VERSION ""

NS_ :

BS_:

BU_: HVESP01 HVESS
VAL_TABLE_ HVESP_HVPackBalance 3 "SNA" 2 "BalancingComplete" 1 "Balancing" 0 "NotBalancing" ;
VAL_TABLE_ HVESP_PackState 7 "Disengage" 6 "Connected" 5 "ExternalIsolationCheck" 4 "PrepareBusJoin" 3 "PrepareBusPrecharge" 2 "StandbyReady" 1 "StandbyNotReady" 0 "StandbyInit" ;
VAL_TABLE_ HVESP_OperationalStatus 15 "NA" 14 "Error" 13 "Reserved" 12 "Reserved" 11 "Reserved" 10 "Reserved" 9 "Reserved" 8 "Reserved" 7 "Reserved" 6 "DisabledInt" 5 "DisabledExtCmd" 4 "EmergencyPowerDown" 3 "NormalPowerDown" 2 "Operational" 1 "InitComplete" 0 "InitInProcess" ;
VAL_TABLE_ HVESP_HvBusConnectionStatus 15 "NA" 14 "Error" 13 "Reserved" 12 "Reserved" 11 "Reserved" 10 "Reserved" 9 "Reserved" 8 "Reserved" 7 "Reserved" 6 "Reserved" 5 "Reserved" 4 "DisconnectedPreChgFail" 3 "DisconnectionInProcess" 2 "ConnectionInProcess" 1 "Connected" 0 "Disconnected" ;
VAL_TABLE_ HVESP_CellBalancingActive 3 "NA" 2 "Error" 1 "CellBalancingActive" 0 "CellBalancingNotActive" ;
VAL_TABLE_ HVESP_InternalChargeStatus 3 "NA" 2 "Error" 1 "ChargingOn" 0 "ChargingOff" ;
VAL_TABLE_ HVESP_CellBalanceStatus 3 "NA" 2 "Error" 1 "CellsUnbalanced" 0 "CellsBalanced" ;
VAL_TABLE_ HVESP_SocStatus 15 "NA" 14 "Error" 13 "Reserved" 12 "Reserved" 11 "Reserved" 10 "Reserved" 9 "Reserved" 8 "Reserved" 7 "Reserved" 6 "SocAboveUpperLimit" 5 "SocRecommendedUpperLimit" 4 "SocApproachingUpperLimit" 3 "SocBelowLowerLimit" 2 "SocRecommendedLowerLimit" 1 "SocApproachingLowerLimit" 0 "SocLevelAcceptableLimit" ;
VAL_TABLE_ HVESP_InertiaSwitchStatus 3 "NA" 2 "Error" 1 "ImpactSensed" 0 "NoImpactSensed" ;
VAL_TABLE_ HVESP_HvilStatus 3 "NA" 2 "Error" 1 "HvilOpen" 0 "HvilClosed" ;
VAL_TABLE_ HVESP_HvBusPassiveIsoTestStatus 15 "NA" 14 "Error" 13 "Reserved" 12 "Reserved" 11 "Reserved" 10 "Reserved" 9 "Reserved" 8 "Reserved" 7 "Reserved" 6 "Reserved" 5 "TestCompleteFault" 4 "TestCompleteMarginal" 3 "TestCompleteAcceptable" 2 "TestInProcess" 1 "TestRequestedNotInProgress" 0 "NoTestRequested" ;
VAL_TABLE_ HVESP_HvBusActiveIsoTestStatus 15 "NA" 14 "Error" 13 "Reserved" 12 "Reserved" 11 "Reserved" 10 "Reserved" 9 "Reserved" 8 "Reserved" 7 "Reserved" 6 "Reserved" 5 "TestCompleteFault" 4 "TestCompleteMarginal" 3 "TestCompleteAcceptable" 2 "TestInProcess" 1 "TestRequestedNotInProgress" 0 "NoTestRequested" ;
VAL_TABLE_ HVESP_CenterOfPackContState 3 "NA" 2 "Error" 1 "ContactorClosed" 0 "ContactorOpen" ;
VAL_TABLE_ HVESP_HvBusPrechgRelayState 3 "NA" 2 "Error" 1 "RelayOpen" 0 "RelayClosed" ;
VAL_TABLE_ HVESP_HvBusDisconnect 15 "NA" 14 "Error" 13 "DisconnectImminent" 12 "Reserved" 11 "Reserved" 10 "Reserved" 9 "Reserved" 8 "Reserved" 7 "DisconnectImminentPckCurrMax" 6 "DisconnectImminentCellVoltMax" 5 "DisconnectImminentCellVoltMin" 4 "DisconnectImminentModVoltMax" 3 "DisconnectImminentModVoltMin" 2 "DisconnectImminentBattPckVoltMax" 1 "DisconnectImminentBattPackVoltMin" 0 "DisconnectNotPending" ;
VAL_TABLE_ HVESP_HvBusNegContState 3 "NA" 2 "Error" 1 "ContactorClosed" 0 "ContactorOpen" ;
VAL_TABLE_ HVESP_HvBusPosContState 3 "NA" 2 "Error" 1 "ContactorClosed" 0 "ContactorOpen" ;
VAL_TABLE_ HVESP_ThermMngmntMaintReq 3 "DontCare" 2 "Reserved" 1 "ThermMngmntMaintModeNotReq" 0 "ThermMngmntMaintReq" ;
VAL_TABLE_ HVESP_HvBusLsResistor 3 "DontCare" 2 "Reserved" 1 "ConnectionRequested" 0 "ConnectionNotRequested" ;
VAL_TABLE_ HVESP_HvBusHsResistor 3 "DontCare" 2 "Reserved" 1 "ConnectionRequested" 0 "ConnectionNotRequested" ;
VAL_TABLE_ HVESP_OperationConsent 3 "DontCare" 2 "Reserved" 1 "ConsentGiven" 0 "ConsentRevoked" ;
VAL_TABLE_ HVESP_EnableIntChargerCmd 3 "DontCare" 2 "Error" 1 "EnableCharging" 0 "DisableCharging" ;
VAL_TABLE_ HVESP_CellBalancingCmd 3 "DontCare" 2 "Reserved" 1 "CellBalancingRequested" 0 "CellBalancingNotRequested" ;
VAL_TABLE_ HVESP_HvBusPassiveIsolationTest 3 "DontCare" 2 "Reserved" 1 "PassiveIsolationTestRequested" 0 "PassiveIsolationTestNotRequested" ;
VAL_TABLE_ HVESP_HvBusActiveIsoTestCmd 3 "DontCare" 2 "Reserved" 1 "ActiveIsoTestRequested" 0 "ActiveIsoTestNotRequested" ;
VAL_TABLE_ HVESP_PowerDownCmd 3 "DontCare" 2 "EmergencyPowerDown" 1 "NormalPowerDown" 0 "PowerDownNotRequested" ;
VAL_TABLE_ HVESP_HvBusConnectCmd 3 "DontCare" 2 "EmergencyContactorClose" 1 "CloseContactor" 0 "OpenContactor" ;

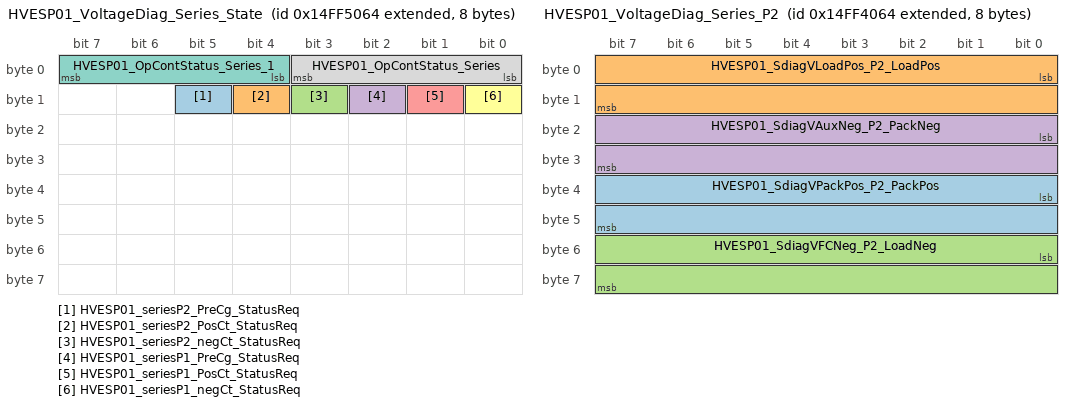
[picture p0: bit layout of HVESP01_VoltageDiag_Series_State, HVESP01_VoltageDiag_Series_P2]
BO_ 2499760228 HVESP01_VoltageDiag_Series_State: 8 HVESP01
 SG_ HVESP01_seriesP2_PreCg_StatusReq : 13|1@1+ (1,0) [0|1] ""  HVESP01
 SG_ HVESP01_seriesP2_PosCt_StatusReq : 12|1@1+ (1,0) [0|1] ""  HVESP01
 SG_ HVESP01_seriesP2_negCt_StatusReq : 11|1@1+ (1,0) [0|1] ""  HVESP01
 SG_ HVESP01_seriesP1_PreCg_StatusReq : 10|1@1+ (1,0) [0|1] ""  HVESP01
 SG_ HVESP01_seriesP1_PosCt_StatusReq : 9|1@1+ (1,0) [0|1] ""  HVESP01
 SG_ HVESP01_seriesP1_negCt_StatusReq : 8|1@1+ (1,0) [0|1] ""  HVESP01
 SG_ HVESP01_OpContStatus_Series_1 : 4|4@1+ (1,0) [0|15] ""  HVESP01
 SG_ HVESP01_OpContStatus_Series : 0|4@1+ (1,0) [0|15] ""  HVESP01

BO_ 2499756132 HVESP01_VoltageDiag_Series_P2: 8 HVESP01
 SG_ HVESP01_SdiagVPackPos_P2_PackPos : 32|16@1+ (0.01,0) [0|655.35] "v"  HVESP01
 SG_ HVESP01_SdiagVLoadPos_P2_LoadPos : 0|16@1+ (0.01,0) [0|655.35] "v"  HVESP01
 SG_ HVESP01_SdiagVFCNeg_P2_LoadNeg : 48|16@1+ (0.01,0) [0|655.35] "v"  HVESP01
 SG_ HVESP01_SdiagVAuxNeg_P2_PackNeg : 16|16@1+ (0.01,0) [0|655.35] "v"  HVESP01

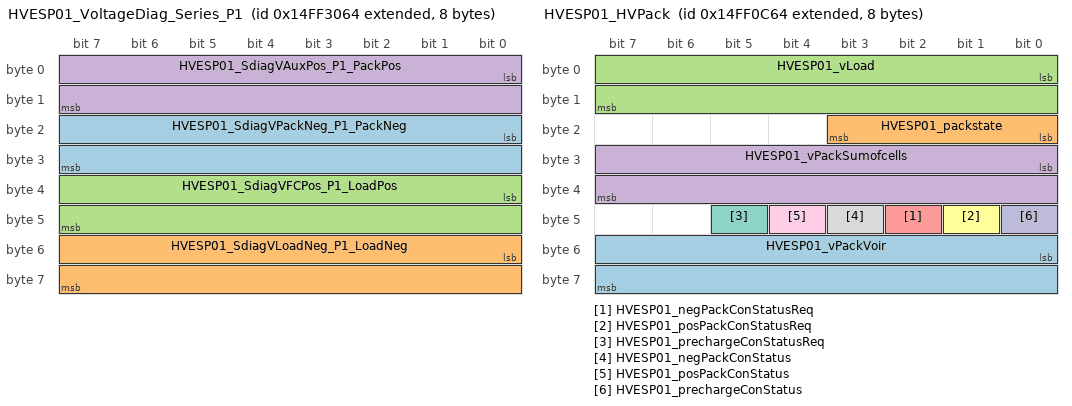
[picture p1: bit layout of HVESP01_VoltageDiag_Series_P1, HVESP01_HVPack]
BO_ 2499752036 HVESP01_VoltageDiag_Series_P1: 8 HVESP01
 SG_ HVESP01_SdiagVPackNeg_P1_PackNeg : 16|16@1+ (0.01,0) [0|655.35] "v"  HVESP01
 SG_ HVESP01_SdiagVLoadNeg_P1_LoadNeg : 48|16@1+ (0.01,0) [0|655.35] "v"  HVESP01
 SG_ HVESP01_SdiagVFCPos_P1_LoadPos : 32|16@1+ (0.01,0) [0|655.35] "v"  HVESP01
 SG_ HVESP01_SdiagVAuxPos_P1_PackPos : 0|16@1+ (0.01,0) [0|655.35] "v"  HVESP01

BO_ 2499760996 HVESP01_packBoardDetails: 2 HVESP01
 SG_ HVESP01_packBoardDetails_pack_id : 8|4@1+ (1,0) [0|15] ""  HVESP01
 SG_ HVESP01_packBoardDetails_board : 0|4@1+ (1,0) [0|15] ""  HVESP01

BO_ 2499743588 HVESP01_brickCapacity: 8 HVESP01
 SG_ HVESP01_brickCapacity_01 m0 : 8|14@1+ (1,0) [0|16383] "Ah"  HVESP01
 SG_ HVESP01_brickCapacity_02 m0 : 22|14@1+ (1,0) [0|16383] "Ah"  HVESP01
 SG_ HVESP01_brickCapacity_03 m0 : 36|14@1+ (1,0) [0|16383] "Ah"  HVESP01
 SG_ HVESP01_brickCapacity_04 m0 : 50|14@1+ (1,0) [0|16383] "Ah"  HVESP01
 SG_ HVESP01_brickCapacity_05 m1 : 8|14@1+ (1,0) [0|16383] "Ah"  HVESP01
 SG_ HVESP01_brickCapacity_06 m1 : 22|14@1+ (1,0) [0|16383] "Ah"  HVESP01
 SG_ HVESP01_brickCapacity_07 m1 : 36|14@1+ (1,0) [0|16383] "Ah"  HVESP01
 SG_ HVESP01_brickCapacity_08 m1 : 50|14@1+ (1,0) [0|16383] "Ah"  HVESP01
 SG_ HVESP01_brickCapacity_09 m2 : 8|14@1+ (1,0) [0|16383] "Ah"  HVESP01
 SG_ HVESP01_brickCapacity_10 m2 : 22|14@1+ (1,0) [0|16383] "Ah"  HVESP01
 SG_ HVESP01_brickCapacity_11 m2 : 36|14@1+ (1,0) [0|16383] "Ah"  HVESP01
 SG_ HVESP01_brickCapacity_12 m2 : 50|14@1+ (1,0) [0|16383] "Ah"  HVESP01
 SG_ HVESP01_brickCapacity_13 m3 : 8|14@1+ (1,0) [0|16383] "Ah"  HVESP01
 SG_ HVESP01_brickCapacity_14 m3 : 22|14@1+ (1,0) [0|16383] "Ah"  HVESP01
 SG_ HVESP01_brickCapacity_15 m3 : 36|14@1+ (1,0) [0|16383] "Ah"  HVESP01
 SG_ HVESP01_brickCapacity_16 m3 : 50|14@1+ (1,0) [0|16383] "Ah"  HVESP01
 SG_ HVESP01_brickCapacity_17 m4 : 8|14@1+ (1,0) [0|16383] "Ah"  HVESP01
 SG_ HVESP01_brickCapacity_18 m4 : 22|14@1+ (1,0) [0|16383] "Ah"  HVESP01
 SG_ HVESP01_brickCapacity_19 m4 : 36|14@1+ (1,0) [0|16383] "Ah"  HVESP01
 SG_ HVESP01_brickCapacity_20 m4 : 50|14@1+ (1,0) [0|16383] "Ah"  HVESP01
 SG_ HVESP01_brickCapacity_21 m5 : 8|14@1+ (1,0) [0|16383] "Ah"  HVESP01
 SG_ HVESP01_brickCapacity_22 m5 : 22|14@1+ (1,0) [0|16383] "Ah"  HVESP01
 SG_ HVESP01_brickCapacity_23 m5 : 36|14@1+ (1,0) [0|16383] "Ah"  HVESP01
 SG_ HVESP01_brickCapacity_24 m5 : 50|14@1+ (1,0) [0|16383] "Ah"  HVESP01
 SG_ HVESP01_brickCapacity_25 m6 : 8|14@1+ (1,0) [0|16383] "Ah"  HVESP01
 SG_ HVESP01_brickCapacity_26 m6 : 22|14@1+ (1,0) [0|16383] "Ah"  HVESP01
 SG_ HVESP01_brickCapacity_27 m6 : 36|14@1+ (1,0) [0|16383] "Ah"  HVESP01
 SG_ HVESP01_brickCapacity_28 m6 : 50|14@1+ (1,0) [0|16383] "Ah"  HVESP01
 SG_ HVESP01_brickCapacity_29 m7 : 8|14@1+ (1,0) [0|16383] "Ah"  HVESP01
 SG_ HVESP01_brickCapacity_30 m7 : 22|14@1+ (1,0) [0|16383] "Ah"  HVESP01
 SG_ HVESP01_brickCapacity_31 m7 : 36|14@1+ (1,0) [0|16383] "Ah"  HVESP01
 SG_ HVESP01_brickCapacity_32 m7 : 50|14@1+ (1,0) [0|16383] "Ah"  HVESP01
 SG_ HVESP01_brickCapacity_33 m8 : 8|14@1+ (1,0) [0|16383] "Ah"  HVESP01
 SG_ HVESP01_brickCapacity_34 m8 : 22|14@1+ (1,0) [0|16383] "Ah"  HVESP01
 SG_ HVESP01_brickCapacity_35 m8 : 36|14@1+ (1,0) [0|16383] "Ah"  HVESP01
 SG_ HVESP01_brickCapacity_36 m8 : 50|14@1+ (1,0) [0|16383] "Ah"  HVESP01
 SG_ HVESP01_brickCapacity_37 m9 : 8|14@1+ (1,0) [0|16383] "Ah"  HVESP01
 SG_ HVESP01_brickCapacity_38 m9 : 22|14@1+ (1,0) [0|16383] "Ah"  HVESP01
 SG_ HVESP01_brickCapacity_39 m9 : 36|14@1+ (1,0) [0|16383] "Ah"  HVESP01
 SG_ HVESP01_brickCapacity_40 m9 : 50|14@1+ (1,0) [0|16383] "Ah"  HVESP01
 SG_ HVESP01_brickCapacity_41 m10 : 8|14@1+ (1,0) [0|16383] "Ah"  HVESP01
 SG_ HVESP01_brickCapacity_42 m10 : 22|14@1+ (1,0) [0|16383] "Ah"  HVESP01
 SG_ HVESP01_brickCapacity_43 m10 : 36|14@1+ (1,0) [0|16383] "Ah"  HVESP01
 SG_ HVESP01_brickCapacity_44 m10 : 50|14@1+ (1,0) [0|16383] "Ah"  HVESP01
 SG_ HVESP01_brickCapacity_45 m11 : 8|14@1+ (1,0) [0|16383] "Ah"  HVESP01
 SG_ HVESP01_brickCapacity_46 m11 : 22|14@1+ (1,0) [0|16383] "Ah"  HVESP01
 SG_ HVESP01_brickCapacity_47 m11 : 36|14@1+ (1,0) [0|16383] "Ah"  HVESP01
 SG_ HVESP01_brickCapacity_48 m11 : 50|14@1+ (1,0) [0|16383] "Ah"  HVESP01
 SG_ HVESP01_brickCapacity_49 m12 : 8|14@1+ (1,0) [0|16383] "Ah"  HVESP01
 SG_ HVESP01_brickCapacity_50 m12 : 22|14@1+ (1,0) [0|16383] "Ah"  HVESP01
 SG_ HVESP01_brickCapacity_51 m12 : 36|14@1+ (1,0) [0|16383] "Ah"  HVESP01
 SG_ HVESP01_brickCapacity_52 m12 : 50|14@1+ (1,0) [0|16383] "Ah"  HVESP01
 SG_ HVESP01_brickCapacity_53 m13 : 8|14@1+ (1,0) [0|16383] "Ah"  HVESP01
 SG_ HVESP01_brickCapacity_54 m13 : 22|14@1+ (1,0) [0|16383] "Ah"  HVESP01
 SG_ HVESP01_brickCapacity_55 m13 : 36|14@1+ (1,0) [0|16383] "Ah"  HVESP01
 SG_ HVESP01_brickCapacity_56 m13 : 50|14@1+ (1,0) [0|16383] "Ah"  HVESP01
 SG_ HVESP01_brickCapacity_57 m14 : 8|14@1+ (1,0) [0|16383] "Ah"  HVESP01
 SG_ HVESP01_brickCapacity_58 m14 : 22|14@1+ (1,0) [0|16383] "Ah"  HVESP01
 SG_ HVESP01_brickCapacity_59 m14 : 36|14@1+ (1,0) [0|16383] "Ah"  HVESP01
 SG_ HVESP01_brickCapacity_60 m14 : 50|14@1+ (1,0) [0|16383] "Ah"  HVESP01
 SG_ HVESP01_brickCapacity_61 m15 : 8|14@1+ (1,0) [0|16383] "Ah"  HVESP01
 SG_ HVESP01_brickCapacity_62 m15 : 22|14@1+ (1,0) [0|16383] "Ah"  HVESP01
 SG_ HVESP01_brickCapacity_63 m15 : 36|14@1+ (1,0) [0|16383] "Ah"  HVESP01
 SG_ HVESP01_brickCapacity_64 m15 : 50|14@1+ (1,0) [0|16383] "Ah"  HVESP01
 SG_ HVESP01_brickCapacity_65 m16 : 8|14@1+ (1,0) [0|16383] "Ah"  HVESP01
 SG_ HVESP01_brickCapacity_66 m16 : 22|14@1+ (1,0) [0|16383] "Ah"  HVESP01
 SG_ HVESP01_brickCapacity_67 m16 : 36|14@1+ (1,0) [0|16383] "Ah"  HVESP01
 SG_ HVESP01_brickCapacity_68 m16 : 50|14@1+ (1,0) [0|16383] "Ah"  HVESP01
 SG_ HVESP01_brickCapacity_69 m17 : 8|14@1+ (1,0) [0|16383] "Ah"  HVESP01
 SG_ HVESP01_brickCapacity_70 m17 : 22|14@1+ (1,0) [0|16383] "Ah"  HVESP01
 SG_ HVESP01_brickCapacity_71 m17 : 36|14@1+ (1,0) [0|16383] "Ah"  HVESP01
 SG_ HVESP01_brickCapacity_72 m17 : 50|14@1+ (1,0) [0|16383] "Ah"  HVESP01
 SG_ HVESP01_brickCapacity_73 m18 : 8|14@1+ (1,0) [0|16383] "Ah"  HVESP01
 SG_ HVESP01_brickCapacity_74 m18 : 22|14@1+ (1,0) [0|16383] "Ah"  HVESP01
 SG_ HVESP01_brickCapacity_75 m18 : 36|14@1+ (1,0) [0|16383] "Ah"  HVESP01
 SG_ HVESP01_brickCapacity_76 m18 : 50|14@1+ (1,0) [0|16383] "Ah"  HVESP01
 SG_ HVESP01_brickCapacity_77 m19 : 8|14@1+ (1,0) [0|16383] "Ah"  HVESP01
 SG_ HVESP01_brickCapacity_78 m19 : 22|14@1+ (1,0) [0|16383] "Ah"  HVESP01
 SG_ HVESP01_brickCapacity_79 m19 : 36|14@1+ (1,0) [0|16383] "Ah"  HVESP01
 SG_ HVESP01_brickCapacity_80 m19 : 50|14@1+ (1,0) [0|16383] "Ah"  HVESP01
 SG_ HVESP01_brickCapacity_81 m20 : 8|14@1+ (1,0) [0|16383] "Ah"  HVESP01
 SG_ HVESP01_brickCapacity_82 m20 : 22|14@1+ (1,0) [0|16383] "Ah"  HVESP01
 SG_ HVESP01_brickCapacity_83 m20 : 36|14@1+ (1,0) [0|16383] "Ah"  HVESP01
 SG_ HVESP01_brickCapacity_84 m20 : 50|14@1+ (1,0) [0|16383] "Ah"  HVESP01
 SG_ HVESP01_brickCapacity_85 m21 : 8|14@1+ (1,0) [0|16383] "Ah"  HVESP01
 SG_ HVESP01_brickCapacity_86 m21 : 22|14@1+ (1,0) [0|16383] "Ah"  HVESP01
 SG_ HVESP01_brickCapacity_87 m21 : 36|14@1+ (1,0) [0|16383] "Ah"  HVESP01
 SG_ HVESP01_brickCapacity_88 m21 : 50|14@1+ (1,0) [0|16383] "Ah"  HVESP01
 SG_ HVESP01_brickCapacity_89 m22 : 8|14@1+ (1,0) [0|16383] "Ah"  HVESP01
 SG_ HVESP01_brickCapacity_90 m22 : 22|14@1+ (1,0) [0|16383] "Ah"  HVESP01
 SG_ HVESP01_brickCapacity_91 m22 : 36|14@1+ (1,0) [0|16383] "Ah"  HVESP01
 SG_ HVESP01_brickCapacity_92 m22 : 50|14@1+ (1,0) [0|16383] "Ah"  HVESP01
 SG_ HVESP01_brickCapacity_93 m23 : 8|14@1+ (1,0) [0|16383] "Ah"  HVESP01
 SG_ HVESP01_brickCapacity_94 m23 : 22|14@1+ (1,0) [0|16383] "Ah"  HVESP01
 SG_ HVESP01_brickCapacity_95 m23 : 36|14@1+ (1,0) [0|16383] "Ah"  HVESP01
 SG_ HVESP01_brickCapacity_96 m23 : 50|14@1+ (1,0) [0|16383] "Ah"  HVESP01
 SG_ HVESP01_brickCapacity_97 m24 : 8|14@1+ (1,0) [0|16383] "Ah"  HVESP01
 SG_ HVESP01_brickCapacity_98 m24 : 22|14@1+ (1,0) [0|16383] "Ah"  HVESP01
 SG_ HVESP01_brickCapacity_99 m24 : 36|14@1+ (1,0) [0|16383] "Ah"  HVESP01
 SG_ HVESP01_brickCapacity_100 m24 : 50|14@1+ (1,0) [0|16383] "Ah"  HVESP01
 SG_ HVESP01_brickCapacity_101 m25 : 8|14@1+ (1,0) [0|16383] "Ah"  HVESP01
 SG_ HVESP01_brickCapacity_102 m25 : 22|14@1+ (1,0) [0|16383] "Ah"  HVESP01
 SG_ HVESP01_brickCapacity_103 m25 : 36|14@1+ (1,0) [0|16383] "Ah"  HVESP01
 SG_ HVESP01_brickCapacity_104 m25 : 50|14@1+ (1,0) [0|16383] "Ah"  HVESP01
 SG_ HVESP01_brickCapacity_105 m26 : 8|14@1+ (1,0) [0|16383] "Ah"  HVESP01
 SG_ HVESP01_brickCapacity_106 m26 : 22|14@1+ (1,0) [0|16383] "Ah"  HVESP01
 SG_ HVESP01_brickCapacity_107 m26 : 36|14@1+ (1,0) [0|16383] "Ah"  HVESP01
 SG_ HVESP01_brickCapacity_108 m26 : 50|14@1+ (1,0) [0|16383] "Ah"  HVESP01
 SG_ HVESP01_brickCapacity_109 m27 : 8|14@1+ (1,0) [0|16383] "Ah"  HVESP01
 SG_ HVESP01_brickCapacity_110 m27 : 22|14@1+ (1,0) [0|16383] "Ah"  HVESP01
 SG_ HVESP01_brickCapacity_111 m27 : 36|14@1+ (1,0) [0|16383] "Ah"  HVESP01
 SG_ HVESP01_brickCapacity_112 m27 : 50|14@1+ (1,0) [0|16383] "Ah"  HVESP01
 SG_ HVESP01_brickCapacity_113 m28 : 8|14@1+ (1,0) [0|16383] "Ah"  HVESP01
 SG_ HVESP01_brickCapacity_114 m28 : 22|14@1+ (1,0) [0|16383] "Ah"  HVESP01
 SG_ HVESP01_brickCapacity_115 m28 : 36|14@1+ (1,0) [0|16383] "Ah"  HVESP01
 SG_ HVESP01_brickCapacity_116 m28 : 50|14@1+ (1,0) [0|16383] "Ah"  HVESP01
 SG_ HVESP01_brickCapacity_117 m29 : 8|14@1+ (1,0) [0|16383] "Ah"  HVESP01
 SG_ HVESP01_brickCapacity_118 m29 : 22|14@1+ (1,0) [0|16383] "Ah"  HVESP01
 SG_ HVESP01_brickCapacity_119 m29 : 36|14@1+ (1,0) [0|16383] "Ah"  HVESP01
 SG_ HVESP01_brickCapacity_120 m29 : 50|14@1+ (1,0) [0|16383] "Ah"  HVESP01
 SG_ HVESP01_brickCapacity_121 m30 : 8|14@1+ (1,0) [0|16383] "Ah"  HVESP01
 SG_ HVESP01_brickCapacity_122 m30 : 22|14@1+ (1,0) [0|16383] "Ah"  HVESP01
 SG_ HVESP01_brickCapacity_123 m30 : 36|14@1+ (1,0) [0|16383] "Ah"  HVESP01
 SG_ HVESP01_brickCapacity_124 m30 : 50|14@1+ (1,0) [0|16383] "Ah"  HVESP01
 SG_ HVESP01_brickCapacity_125 m31 : 8|14@1+ (1,0) [0|16383] "Ah"  HVESP01
 SG_ HVESP01_brickCapacity_126 m31 : 22|14@1+ (1,0) [0|16383] "Ah"  HVESP01
 SG_ HVESP01_brickCapacity_127 m31 : 36|14@1+ (1,0) [0|16383] "Ah"  HVESP01
 SG_ HVESP01_brickCapacity_128 m31 : 50|14@1+ (1,0) [0|16383] "Ah"  HVESP01
 SG_ HVESP01_brickCapacity_129 m32 : 8|14@1+ (1,0) [0|16383] "Ah"  HVESP01
 SG_ HVESP01_brickCapacity_130 m32 : 22|14@1+ (1,0) [0|16383] "Ah"  HVESP01
 SG_ HVESP01_brickCapacity_131 m32 : 36|14@1+ (1,0) [0|16383] "Ah"  HVESP01
 SG_ HVESP01_brickCapacity_132 m32 : 50|14@1+ (1,0) [0|16383] "Ah"  HVESP01
 SG_ HVESP01_brickCapacity_133 m33 : 8|14@1+ (1,0) [0|16383] "Ah"  HVESP01
 SG_ HVESP01_brickCapacity_134 m33 : 22|14@1+ (1,0) [0|16383] "Ah"  HVESP01
 SG_ HVESP01_brickCapacity_135 m33 : 36|14@1+ (1,0) [0|16383] "Ah"  HVESP01
 SG_ HVESP01_brickCapacity_136 m33 : 50|14@1+ (1,0) [0|16383] "Ah"  HVESP01
 SG_ HVESP01_brickCapacity_137 m34 : 8|14@1+ (1,0) [0|16383] "Ah"  HVESP01
 SG_ HVESP01_brickCapacity_138 m34 : 22|14@1+ (1,0) [0|16383] "Ah"  HVESP01
 SG_ HVESP01_brickCapacity_139 m34 : 36|14@1+ (1,0) [0|16383] "Ah"  HVESP01
 SG_ HVESP01_brickCapacity_140 m34 : 50|14@1+ (1,0) [0|16383] "Ah"  HVESP01
 SG_ HVESP01_brickCapacity_141 m35 : 8|14@1+ (1,0) [0|16383] "Ah"  HVESP01
 SG_ HVESP01_brickCapacity_142 m35 : 22|14@1+ (1,0) [0|16383] "Ah"  HVESP01
 SG_ HVESP01_brickCapacity_143 m35 : 36|14@1+ (1,0) [0|16383] "Ah"  HVESP01
 SG_ HVESP01_brickCapacity_144 m35 : 50|14@1+ (1,0) [0|16383] "Ah"  HVESP01
 SG_ HVESP01_brickCapacity_145 m36 : 8|14@1+ (1,0) [0|16383] "Ah"  HVESP01
 SG_ HVESP01_brickCapacity_146 m36 : 22|14@1+ (1,0) [0|16383] "Ah"  HVESP01
 SG_ HVESP01_brickCapacity_147 m36 : 36|14@1+ (1,0) [0|16383] "Ah"  HVESP01
 SG_ HVESP01_brickCapacity_148 m36 : 50|14@1+ (1,0) [0|16383] "Ah"  HVESP01
 SG_ HVESP01_brickCapacity_149 m37 : 8|14@1+ (1,0) [0|16383] "Ah"  HVESP01
 SG_ HVESP01_brickCapacity_150 m37 : 22|14@1+ (1,0) [0|16383] "Ah"  HVESP01
 SG_ HVESP01_brickCapacity_151 m37 : 36|14@1+ (1,0) [0|16383] "Ah"  HVESP01
 SG_ HVESP01_brickCapacity_152 m37 : 50|14@1+ (1,0) [0|16383] "Ah"  HVESP01
 SG_ HVESP01_brickCapacity_153 m38 : 8|14@1+ (1,0) [0|16383] "Ah"  HVESP01
 SG_ HVESP01_brickCapacity_154 m38 : 22|14@1+ (1,0) [0|16383] "Ah"  HVESP01
 SG_ HVESP01_brickCapacity_155 m38 : 36|14@1+ (1,0) [0|16383] "Ah"  HVESP01
 SG_ HVESP01_brickCapacity_156 m38 : 50|14@1+ (1,0) [0|16383] "Ah"  HVESP01
 SG_ HVESP01_brickCapacity_157 m39 : 8|14@1+ (1,0) [0|16383] "Ah"  HVESP01
 SG_ HVESP01_brickCapacity_158 m39 : 22|14@1+ (1,0) [0|16383] "Ah"  HVESP01
 SG_ HVESP01_brickCapacity_159 m39 : 36|14@1+ (1,0) [0|16383] "Ah"  HVESP01
 SG_ HVESP01_brickCapacity_160 m39 : 50|14@1+ (1,0) [0|16383] "Ah"  HVESP01
 SG_ HVESP01_brickCapacity_161 m40 : 8|14@1+ (1,0) [0|16383] "Ah"  HVESP01
 SG_ HVESP01_brickCapacity_162 m40 : 22|14@1+ (1,0) [0|16383] "Ah"  HVESP01
 SG_ HVESP01_brickCapacity_163 m40 : 36|14@1+ (1,0) [0|16383] "Ah"  HVESP01
 SG_ HVESP01_brickCapacity_164 m40 : 50|14@1+ (1,0) [0|16383] "Ah"  HVESP01
 SG_ HVESP01_brickCapacity_165 m41 : 8|14@1+ (1,0) [0|16383] "Ah"  HVESP01
 SG_ HVESP01_brickCapacity_166 m41 : 22|14@1+ (1,0) [0|16383] "Ah"  HVESP01
 SG_ HVESP01_brickCapacity_167 m41 : 36|14@1+ (1,0) [0|16383] "Ah"  HVESP01
 SG_ HVESP01_brickCapacity_168 m41 : 50|14@1+ (1,0) [0|16383] "Ah"  HVESP01
 SG_ HVESP01_brickCapacity_169 m42 : 8|14@1+ (1,0) [0|16383] "Ah"  HVESP01
 SG_ HVESP01_brickCapacity_170 m42 : 22|14@1+ (1,0) [0|16383] "Ah"  HVESP01
 SG_ HVESP01_brickCapacity_171 m42 : 36|14@1+ (1,0) [0|16383] "Ah"  HVESP01
 SG_ HVESP01_brickCapacity_172 m42 : 50|14@1+ (1,0) [0|16383] "Ah"  HVESP01
 SG_ HVESP01_brickCapacity_173 m43 : 8|14@1+ (1,0) [0|16383] "Ah"  HVESP01
 SG_ HVESP01_brickCapacity_174 m43 : 22|14@1+ (1,0) [0|16383] "Ah"  HVESP01
 SG_ HVESP01_brickCapacity_175 m43 : 36|14@1+ (1,0) [0|16383] "Ah"  HVESP01
 SG_ HVESP01_brickCapacity_176 m43 : 50|14@1+ (1,0) [0|16383] "Ah"  HVESP01
 SG_ HVESP01_brickCapacity_177 m44 : 8|14@1+ (1,0) [0|16383] "Ah"  HVESP01
 SG_ HVESP01_brickCapacity_178 m44 : 22|14@1+ (1,0) [0|16383] "Ah"  HVESP01
 SG_ HVESP01_brickCapacity_179 m44 : 36|14@1+ (1,0) [0|16383] "Ah"  HVESP01
 SG_ HVESP01_brickCapacity_180 m44 : 50|14@1+ (1,0) [0|16383] "Ah"  HVESP01
 SG_ multiplexorcap M : 0|8@1+ (1,0) [0|255] ""  HVESP01

BO_ 2499743332 HVESP01_CellBalance: 8 HVESP01
 SG_ HVESP01_PackBalance : 16|2@1+ (1,0) [0|3] ""  HVESP01
 SG_ HVESP01_CellBalance_01 m0 : 8|1@1+ (1,0) [0|1] ""  HVESP01
 SG_ HVESP01_CellBalance_02 m0 : 9|1@1+ (1,0) [0|1] ""  HVESP01
 SG_ HVESP01_CellBalance_03 m0 : 10|1@1+ (1,0) [0|1] ""  HVESP01
 SG_ HVESP01_CellBalance_04 m0 : 11|1@1+ (1,0) [0|1] ""  HVESP01
 SG_ HVESP01_CellBalance_05 m0 : 12|1@1+ (1,0) [0|1] ""  HVESP01
 SG_ HVESP01_CellBalance_06 m0 : 13|1@1+ (1,0) [0|1] ""  HVESP01
 SG_ HVESP01_CellBalance_07 m0 : 14|1@1+ (1,0) [0|1] ""  HVESP01
 SG_ HVESP01_CellBalance_08 m0 : 15|1@1+ (1,0) [0|1] ""  HVESP01
 SG_ HVESP01_CellBalance_09 m1 : 8|1@1+ (1,0) [0|1] ""  HVESP01
 SG_ HVESP01_CellBalance_10 m1 : 9|1@1+ (1,0) [0|1] ""  HVESP01
 SG_ HVESP01_CellBalance_11 m1 : 10|1@1+ (1,0) [0|1] ""  HVESP01
 SG_ HVESP01_CellBalance_12 m1 : 11|1@1+ (1,0) [0|1] ""  HVESP01
 SG_ HVESP01_CellBalance_13 m1 : 12|1@1+ (1,0) [0|1] ""  HVESP01
 SG_ HVESP01_CellBalance_14 m1 : 13|1@1+ (1,0) [0|1] ""  HVESP01
 SG_ HVESP01_CellBalance_15 m1 : 14|1@1+ (1,0) [0|1] ""  HVESP01
 SG_ HVESP01_CellBalance_16 m1 : 15|1@1+ (1,0) [0|1] ""  HVESP01
 SG_ HVESP01_CellBalance_17 m2 : 8|1@1+ (1,0) [0|1] ""  HVESP01
 SG_ HVESP01_CellBalance_18 m2 : 9|1@1+ (1,0) [0|1] ""  HVESP01
 SG_ HVESP01_CellBalance_19 m2 : 10|1@1+ (1,0) [0|1] ""  HVESP01
 SG_ HVESP01_CellBalance_20 m2 : 11|1@1+ (1,0) [0|1] ""  HVESP01
 SG_ HVESP01_CellBalance_21 m2 : 12|1@1+ (1,0) [0|1] ""  HVESP01
 SG_ HVESP01_CellBalance_22 m2 : 13|1@1+ (1,0) [0|1] ""  HVESP01
 SG_ HVESP01_CellBalance_23 m2 : 14|1@1+ (1,0) [0|1] ""  HVESP01
 SG_ HVESP01_CellBalance_24 m2 : 15|1@1+ (1,0) [0|1] ""  HVESP01
 SG_ HVESP01_CellBalance_25 m3 : 8|1@1+ (1,0) [0|1] ""  HVESP01
 SG_ HVESP01_CellBalance_26 m3 : 9|1@1+ (1,0) [0|1] ""  HVESP01
 SG_ HVESP01_CellBalance_27 m3 : 10|1@1+ (1,0) [0|1] ""  HVESP01
 SG_ HVESP01_CellBalance_28 m3 : 11|1@1+ (1,0) [0|1] ""  HVESP01
 SG_ HVESP01_CellBalance_29 m3 : 12|1@1+ (1,0) [0|1] ""  HVESP01
 SG_ HVESP01_CellBalance_30 m3 : 13|1@1+ (1,0) [0|1] ""  HVESP01
 SG_ HVESP01_CellBalance_31 m3 : 14|1@1+ (1,0) [0|1] ""  HVESP01
 SG_ HVESP01_CellBalance_32 m3 : 15|1@1+ (1,0) [0|1] ""  HVESP01
 SG_ HVESP01_CellBalance_33 m4 : 8|1@1+ (1,0) [0|1] ""  HVESP01
 SG_ HVESP01_CellBalance_34 m4 : 9|1@1+ (1,0) [0|1] ""  HVESP01
 SG_ HVESP01_CellBalance_35 m4 : 10|1@1+ (1,0) [0|1] ""  HVESP01
 SG_ HVESP01_CellBalance_36 m4 : 11|1@1+ (1,0) [0|1] ""  HVESP01
 SG_ HVESP01_CellBalance_37 m4 : 12|1@1+ (1,0) [0|1] ""  HVESP01
 SG_ HVESP01_CellBalance_38 m4 : 13|1@1+ (1,0) [0|1] ""  HVESP01
 SG_ HVESP01_CellBalance_39 m4 : 14|1@1+ (1,0) [0|1] ""  HVESP01
 SG_ HVESP01_CellBalance_40 m4 : 15|1@1+ (1,0) [0|1] ""  HVESP01
 SG_ HVESP01_CellBalance_41 m5 : 8|1@1+ (1,0) [0|1] ""  HVESP01
 SG_ HVESP01_CellBalance_42 m5 : 9|1@1+ (1,0) [0|1] ""  HVESP01
 SG_ HVESP01_CellBalance_43 m5 : 10|1@1+ (1,0) [0|1] ""  HVESP01
 SG_ HVESP01_CellBalance_44 m5 : 11|1@1+ (1,0) [0|1] ""  HVESP01
 SG_ HVESP01_CellBalance_45 m5 : 12|1@1+ (1,0) [0|1] ""  HVESP01
 SG_ HVESP01_CellBalance_46 m5 : 13|1@1+ (1,0) [0|1] ""  HVESP01
 SG_ HVESP01_CellBalance_47 m5 : 14|1@1+ (1,0) [0|1] ""  HVESP01
 SG_ HVESP01_CellBalance_48 m5 : 15|1@1+ (1,0) [0|1] ""  HVESP01
 SG_ HVESP01_CellBalance_49 m6 : 8|1@1+ (1,0) [0|1] ""  HVESP01
 SG_ HVESP01_CellBalance_50 m6 : 9|1@1+ (1,0) [0|1] ""  HVESP01
 SG_ HVESP01_CellBalance_51 m6 : 10|1@1+ (1,0) [0|1] ""  HVESP01
 SG_ HVESP01_CellBalance_52 m6 : 11|1@1+ (1,0) [0|1] ""  HVESP01
 SG_ HVESP01_CellBalance_53 m6 : 12|1@1+ (1,0) [0|1] ""  HVESP01
 SG_ HVESP01_CellBalance_54 m6 : 13|1@1+ (1,0) [0|1] ""  HVESP01
 SG_ HVESP01_CellBalance_55 m6 : 14|1@1+ (1,0) [0|1] ""  HVESP01
 SG_ HVESP01_CellBalance_56 m6 : 15|1@1+ (1,0) [0|1] ""  HVESP01
 SG_ HVESP01_CellBalance_57 m7 : 8|1@1+ (1,0) [0|1] ""  HVESP01
 SG_ HVESP01_CellBalance_58 m7 : 9|1@1+ (1,0) [0|1] ""  HVESP01
 SG_ HVESP01_CellBalance_59 m7 : 10|1@1+ (1,0) [0|1] ""  HVESP01
 SG_ HVESP01_CellBalance_60 m7 : 11|1@1+ (1,0) [0|1] ""  HVESP01
 SG_ HVESP01_CellBalance_61 m7 : 12|1@1+ (1,0) [0|1] ""  HVESP01
 SG_ HVESP01_CellBalance_62 m7 : 13|1@1+ (1,0) [0|1] ""  HVESP01
 SG_ HVESP01_CellBalance_63 m7 : 14|1@1+ (1,0) [0|1] ""  HVESP01
 SG_ HVESP01_CellBalance_64 m7 : 15|1@1+ (1,0) [0|1] ""  HVESP01
 SG_ HVESP01_CellBalance_65 m8 : 8|1@1+ (1,0) [0|1] ""  HVESP01
 SG_ HVESP01_CellBalance_66 m8 : 9|1@1+ (1,0) [0|1] ""  HVESP01
 SG_ HVESP01_CellBalance_67 m8 : 10|1@1+ (1,0) [0|1] ""  HVESP01
 SG_ HVESP01_CellBalance_68 m8 : 11|1@1+ (1,0) [0|1] ""  HVESP01
 SG_ HVESP01_CellBalance_69 m8 : 12|1@1+ (1,0) [0|1] ""  HVESP01
 SG_ HVESP01_CellBalance_70 m8 : 13|1@1+ (1,0) [0|1] ""  HVESP01
 SG_ HVESP01_CellBalance_71 m8 : 14|1@1+ (1,0) [0|1] ""  HVESP01
 SG_ HVESP01_CellBalance_72 m8 : 15|1@1+ (1,0) [0|1] ""  HVESP01
 SG_ HVESP01_CellBalance_73 m9 : 8|1@1+ (1,0) [0|1] ""  HVESP01
 SG_ HVESP01_CellBalance_74 m9 : 9|1@1+ (1,0) [0|1] ""  HVESP01
 SG_ HVESP01_CellBalance_75 m9 : 10|1@1+ (1,0) [0|1] ""  HVESP01
 SG_ HVESP01_CellBalance_76 m9 : 11|1@1+ (1,0) [0|1] ""  HVESP01
 SG_ HVESP01_CellBalance_77 m9 : 12|1@1+ (1,0) [0|1] ""  HVESP01
 SG_ HVESP01_CellBalance_78 m9 : 13|1@1+ (1,0) [0|1] ""  HVESP01
 SG_ HVESP01_CellBalance_79 m9 : 14|1@1+ (1,0) [0|1] ""  HVESP01
 SG_ HVESP01_CellBalance_80 m9 : 15|1@1+ (1,0) [0|1] ""  HVESP01
 SG_ HVESP01_CellBalance_81 m10 : 8|1@1+ (1,0) [0|1] ""  HVESP01
 SG_ HVESP01_CellBalance_82 m10 : 9|1@1+ (1,0) [0|1] ""  HVESP01
 SG_ HVESP01_CellBalance_83 m10 : 10|1@1+ (1,0) [0|1] ""  HVESP01
 SG_ HVESP01_CellBalance_84 m10 : 11|1@1+ (1,0) [0|1] ""  HVESP01
 SG_ HVESP01_CellBalance_85 m10 : 12|1@1+ (1,0) [0|1] ""  HVESP01
 SG_ HVESP01_CellBalance_86 m10 : 13|1@1+ (1,0) [0|1] ""  HVESP01
 SG_ HVESP01_CellBalance_87 m10 : 14|1@1+ (1,0) [0|1] ""  HVESP01
 SG_ HVESP01_CellBalance_88 m10 : 15|1@1+ (1,0) [0|1] ""  HVESP01
 SG_ HVESP01_CellBalance_89 m11 : 8|1@1+ (1,0) [0|1] ""  HVESP01
 SG_ HVESP01_CellBalance_90 m11 : 9|1@1+ (1,0) [0|1] ""  HVESP01
 SG_ HVESP01_CellBalance_91 m11 : 10|1@1+ (1,0) [0|1] ""  HVESP01
 SG_ HVESP01_CellBalance_92 m11 : 11|1@1+ (1,0) [0|1] ""  HVESP01
 SG_ HVESP01_CellBalance_93 m11 : 12|1@1+ (1,0) [0|1] ""  HVESP01
 SG_ HVESP01_CellBalance_94 m11 : 13|1@1+ (1,0) [0|1] ""  HVESP01
 SG_ HVESP01_CellBalance_95 m11 : 14|1@1+ (1,0) [0|1] ""  HVESP01
 SG_ HVESP01_CellBalance_96 m11 : 15|1@1+ (1,0) [0|1] ""  HVESP01
 SG_ HVESP01_CellBalance_97 m12 : 8|1@1+ (1,0) [0|1] ""  HVESP01
 SG_ HVESP01_CellBalance_98 m12 : 9|1@1+ (1,0) [0|1] ""  HVESP01
 SG_ HVESP01_CellBalance_99 m12 : 10|1@1+ (1,0) [0|1] ""  HVESP01
 SG_ HVESP01_CellBalance_100 m12 : 11|1@1+ (1,0) [0|1] ""  HVESP01
 SG_ HVESP01_CellBalance_101 m12 : 12|1@1+ (1,0) [0|1] ""  HVESP01
 SG_ HVESP01_CellBalance_102 m12 : 13|1@1+ (1,0) [0|1] ""  HVESP01
 SG_ HVESP01_CellBalance_103 m12 : 14|1@1+ (1,0) [0|1] ""  HVESP01
 SG_ HVESP01_CellBalance_104 m12 : 15|1@1+ (1,0) [0|1] ""  HVESP01
 SG_ HVESP01_CellBalance_105 m13 : 8|1@1+ (1,0) [0|1] ""  HVESP01
 SG_ HVESP01_CellBalance_106 m13 : 9|1@1+ (1,0) [0|1] ""  HVESP01
 SG_ HVESP01_CellBalance_107 m13 : 10|1@1+ (1,0) [0|1] ""  HVESP01
 SG_ HVESP01_CellBalance_108 m13 : 11|1@1+ (1,0) [0|1] ""  HVESP01
 SG_ HVESP01_CellBalance_109 m13 : 12|1@1+ (1,0) [0|1] ""  HVESP01
 SG_ HVESP01_CellBalance_110 m13 : 13|1@1+ (1,0) [0|1] ""  HVESP01
 SG_ HVESP01_CellBalance_111 m13 : 14|1@1+ (1,0) [0|1] ""  HVESP01
 SG_ HVESP01_CellBalance_112 m13 : 15|1@1+ (1,0) [0|1] ""  HVESP01
 SG_ HVESP01_CellBalance_113 m14 : 8|1@1+ (1,0) [0|1] ""  HVESP01
 SG_ HVESP01_CellBalance_114 m14 : 9|1@1+ (1,0) [0|1] ""  HVESP01
 SG_ HVESP01_CellBalance_115 m14 : 10|1@1+ (1,0) [0|1] ""  HVESP01
 SG_ HVESP01_CellBalance_116 m14 : 11|1@1+ (1,0) [0|1] ""  HVESP01
 SG_ HVESP01_CellBalance_117 m14 : 12|1@1+ (1,0) [0|1] ""  HVESP01
 SG_ HVESP01_CellBalance_118 m14 : 13|1@1+ (1,0) [0|1] ""  HVESP01
 SG_ HVESP01_CellBalance_119 m14 : 14|1@1+ (1,0) [0|1] ""  HVESP01
 SG_ HVESP01_CellBalance_120 m14 : 15|1@1+ (1,0) [0|1] ""  HVESP01
 SG_ HVESP01_CellBalance_121 m15 : 8|1@1+ (1,0) [0|1] ""  HVESP01
 SG_ HVESP01_CellBalance_122 m15 : 9|1@1+ (1,0) [0|1] ""  HVESP01
 SG_ HVESP01_CellBalance_123 m15 : 10|1@1+ (1,0) [0|1] ""  HVESP01
 SG_ HVESP01_CellBalance_124 m15 : 11|1@1+ (1,0) [0|1] ""  HVESP01
 SG_ HVESP01_CellBalance_125 m15 : 12|1@1+ (1,0) [0|1] ""  HVESP01
 SG_ HVESP01_CellBalance_126 m15 : 13|1@1+ (1,0) [0|1] ""  HVESP01
 SG_ HVESP01_CellBalance_127 m15 : 14|1@1+ (1,0) [0|1] ""  HVESP01
 SG_ HVESP01_CellBalance_128 m15 : 15|1@1+ (1,0) [0|1] ""  HVESP01
 SG_ HVESP01_CellBalance_129 m16 : 8|1@1+ (1,0) [0|1] ""  HVESP01
 SG_ HVESP01_CellBalance_130 m16 : 9|1@1+ (1,0) [0|1] ""  HVESP01
 SG_ HVESP01_CellBalance_131 m16 : 10|1@1+ (1,0) [0|1] ""  HVESP01
 SG_ HVESP01_CellBalance_132 m16 : 11|1@1+ (1,0) [0|1] ""  HVESP01
 SG_ HVESP01_CellBalance_133 m16 : 12|1@1+ (1,0) [0|1] ""  HVESP01
 SG_ HVESP01_CellBalance_134 m16 : 13|1@1+ (1,0) [0|1] ""  HVESP01
 SG_ HVESP01_CellBalance_135 m16 : 14|1@1+ (1,0) [0|1] ""  HVESP01
 SG_ HVESP01_CellBalance_136 m16 : 15|1@1+ (1,0) [0|1] ""  HVESP01
 SG_ HVESP01_CellBalance_137 m17 : 8|1@1+ (1,0) [0|1] ""  HVESP01
 SG_ HVESP01_CellBalance_138 m17 : 9|1@1+ (1,0) [0|1] ""  HVESP01
 SG_ HVESP01_CellBalance_139 m17 : 10|1@1+ (1,0) [0|1] ""  HVESP01
 SG_ HVESP01_CellBalance_140 m17 : 11|1@1+ (1,0) [0|1] ""  HVESP01
 SG_ HVESP01_CellBalance_141 m17 : 12|1@1+ (1,0) [0|1] ""  HVESP01
 SG_ HVESP01_CellBalance_142 m17 : 13|1@1+ (1,0) [0|1] ""  HVESP01
 SG_ HVESP01_CellBalance_143 m17 : 14|1@1+ (1,0) [0|1] ""  HVESP01
 SG_ HVESP01_CellBalance_144 m17 : 15|1@1+ (1,0) [0|1] ""  HVESP01
 SG_ HVESP01_CellBalance_145 m18 : 8|1@1+ (1,0) [0|1] ""  HVESP01
 SG_ HVESP01_CellBalance_146 m18 : 9|1@1+ (1,0) [0|1] ""  HVESP01
 SG_ HVESP01_CellBalance_147 m18 : 10|1@1+ (1,0) [0|1] ""  HVESP01
 SG_ HVESP01_CellBalance_148 m18 : 11|1@1+ (1,0) [0|1] ""  HVESP01
 SG_ HVESP01_CellBalance_149 m18 : 12|1@1+ (1,0) [0|1] ""  HVESP01
 SG_ HVESP01_CellBalance_150 m18 : 13|1@1+ (1,0) [0|1] ""  HVESP01
 SG_ HVESP01_CellBalance_151 m18 : 14|1@1+ (1,0) [0|1] ""  HVESP01
 SG_ HVESP01_CellBalance_152 m18 : 15|1@1+ (1,0) [0|1] ""  HVESP01
 SG_ HVESP01_CellBalance_153 m19 : 8|1@1+ (1,0) [0|1] ""  HVESP01
 SG_ HVESP01_CellBalance_154 m19 : 9|1@1+ (1,0) [0|1] ""  HVESP01
 SG_ HVESP01_CellBalance_155 m19 : 10|1@1+ (1,0) [0|1] ""  HVESP01
 SG_ HVESP01_CellBalance_156 m19 : 11|1@1+ (1,0) [0|1] ""  HVESP01
 SG_ HVESP01_CellBalance_157 m19 : 12|1@1+ (1,0) [0|1] ""  HVESP01
 SG_ HVESP01_CellBalance_158 m19 : 13|1@1+ (1,0) [0|1] ""  HVESP01
 SG_ HVESP01_CellBalance_159 m19 : 14|1@1+ (1,0) [0|1] ""  HVESP01
 SG_ HVESP01_CellBalance_160 m19 : 15|1@1+ (1,0) [0|1] ""  HVESP01
 SG_ HVESP01_CellBalance_161 m20 : 8|1@1+ (1,0) [0|1] ""  HVESP01
 SG_ HVESP01_CellBalance_162 m20 : 9|1@1+ (1,0) [0|1] ""  HVESP01
 SG_ HVESP01_CellBalance_163 m20 : 10|1@1+ (1,0) [0|1] ""  HVESP01
 SG_ HVESP01_CellBalance_164 m20 : 11|1@1+ (1,0) [0|1] ""  HVESP01
 SG_ HVESP01_CellBalance_165 m20 : 12|1@1+ (1,0) [0|1] ""  HVESP01
 SG_ HVESP01_CellBalance_166 m20 : 13|1@1+ (1,0) [0|1] ""  HVESP01
 SG_ HVESP01_CellBalance_167 m20 : 14|1@1+ (1,0) [0|1] ""  HVESP01
 SG_ HVESP01_CellBalance_168 m20 : 15|1@1+ (1,0) [0|1] ""  HVESP01
 SG_ HVESP01_CellBalance_169 m21 : 8|1@1+ (1,0) [0|1] ""  HVESP01
 SG_ HVESP01_CellBalance_170 m21 : 9|1@1+ (1,0) [0|1] ""  HVESP01
 SG_ HVESP01_CellBalance_171 m21 : 10|1@1+ (1,0) [0|1] ""  HVESP01
 SG_ HVESP01_CellBalance_172 m21 : 11|1@1+ (1,0) [0|1] ""  HVESP01
 SG_ HVESP01_CellBalance_173 m21 : 12|1@1+ (1,0) [0|1] ""  HVESP01
 SG_ HVESP01_CellBalance_174 m21 : 13|1@1+ (1,0) [0|1] ""  HVESP01
 SG_ HVESP01_CellBalance_175 m21 : 14|1@1+ (1,0) [0|1] ""  HVESP01
 SG_ HVESP01_CellBalance_176 m21 : 15|1@1+ (1,0) [0|1] ""  HVESP01
 SG_ HVESP01_CellBalance_177 m22 : 8|1@1+ (1,0) [0|1] ""  HVESP01
 SG_ HVESP01_CellBalance_178 m22 : 9|1@1+ (1,0) [0|1] ""  HVESP01
 SG_ HVESP01_CellBalance_179 m22 : 10|1@1+ (1,0) [0|1] ""  HVESP01
 SG_ HVESP01_CellBalance_180 m22 : 11|1@1+ (1,0) [0|1] ""  HVESP01
 SG_ HVESP01_CellBalance_181 m22 : 12|1@1+ (1,0) [0|1] ""  HVESP01
 SG_ HVESP01_CellBalance_182 m22 : 13|1@1+ (1,0) [0|1] ""  HVESP01
 SG_ HVESP01_CellBalance_183 m22 : 14|1@1+ (1,0) [0|1] ""  HVESP01
 SG_ HVESP01_CellBalance_184 m22 : 15|1@1+ (1,0) [0|1] ""  HVESP01
 SG_ multiplexorcb M : 0|8@1+ (1,0) [0|255] ""  HVESP01

BO_ 2499743076 HVESP01_Version: 8 HVESP01
 SG_ HVESP01_SwVerSubMinorApp m0 : 24|8@1+ (1,0) [0|255] ""  HVESP01
 SG_ HVESP01_SwVerMinorApp m0 : 16|8@1+ (1,0) [0|255] ""  HVESP01
 SG_ HVESP01_SwVerMajorApp m0 : 8|8@1+ (1,0) [0|255] ""  HVESP01
 SG_ HVESP01_HwVerApp m0 : 32|8@1+ (1,0) [0|255] ""  HVESP01
 SG_ HVESP01_SwVerAbsCusApp m0 : 40|8@1+ (1,0) [0|255] ""  HVESP01
 SG_ HVESP01_SwVerAbsIntApp m0 : 48|8@1+ (1,0) [0|255] ""  HVESP01
 SG_ HVESP01_SwVerSubMinorBl m1 : 24|8@1+ (1,0) [0|255] ""  HVESP01
 SG_ HVESP01_SwVerMinorBl m1 : 16|8@1+ (1,0) [0|255] ""  HVESP01
 SG_ HVESP01_SwVerMajorBl m1 : 8|8@1+ (1,0) [0|255] ""  HVESP01
 SG_ HVESP01_HwVerBl m1 : 32|8@1+ (1,0) [0|255] ""  HVESP01
 SG_ HVESP01_SwVerAbsCusBl m1 : 40|8@1+ (1,0) [0|255] ""  HVESP01
 SG_ HVESP01_SwVerAbsIntBl m1 : 48|8@1+ (1,0) [0|255] ""  HVESP01
 SG_ HVESP01_SwVerSubMinorCal m2 : 24|8@1+ (1,0) [0|255] ""  HVESP01
 SG_ HVESP01_SwVerMinorCal m2 : 16|8@1+ (1,0) [0|255] ""  HVESP01
 SG_ HVESP01_SwVerMajorCal m2 : 8|8@1+ (1,0) [0|255] ""  HVESP01
 SG_ HVESP01_HwVerCal m2 : 32|8@1+ (1,0) [0|255] ""  HVESP01
 SG_ HVESP01_SwVerAbsCusCal m2 : 40|8@1+ (1,0) [0|255] ""  HVESP01
 SG_ HVESP01_SwVerAbsIntCal m2 : 48|8@1+ (1,0) [0|255] ""  HVESP01
 SG_ multiplexorvr M : 0|2@1+ (1,0) [0|2] ""  HVESP01

BO_ 2499742820 HVESP01_HVPack: 8 HVESP01
 SG_ HVESP01_vPackVoir : 48|16@1+ (0.05,0) [0|3276.75] "V"  HVESP01
 SG_ HVESP01_packstate : 16|4@1+ (1,0) [0|15] ""  HVESP01
 SG_ HVESP01_vLoad : 0|16@1+ (0.05,0) [0|3276.75] "V"  HVESP01
 SG_ HVESP01_vPackSumofcells : 24|16@1+ (0.05,0) [0|3276.75] "V"  HVESP01
 SG_ HVESP01_negPackConStatusReq : 42|1@1+ (1,0) [0|1] ""  HVESP01
 SG_ HVESP01_posPackConStatusReq : 41|1@1+ (1,0) [0|1] ""  HVESP01
 SG_ HVESP01_prechargeConStatusReq : 45|1@1+ (1,0) [0|1] ""  HVESP01
 SG_ HVESP01_negPackConStatus : 43|1@1+ (1,0) [0|1] ""  HVESP01
 SG_ HVESP01_posPackConStatus : 44|1@1+ (1,0) [0|1] ""  HVESP01
 SG_ HVESP01_prechargeConStatus : 40|1@1+ (1,0) [0|1] ""  HVESP01

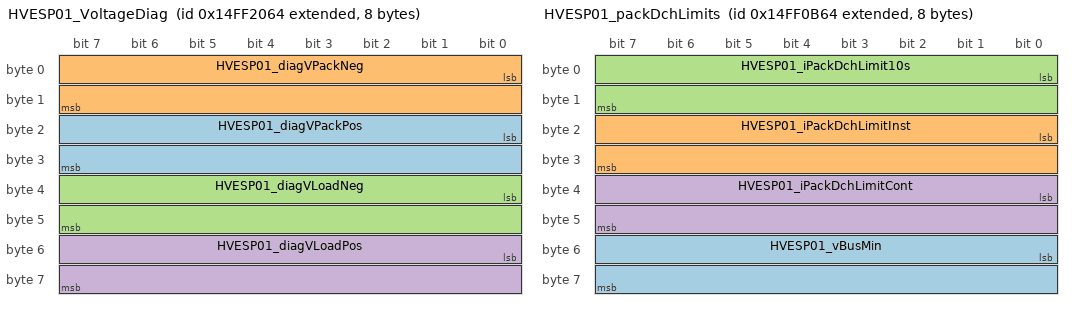
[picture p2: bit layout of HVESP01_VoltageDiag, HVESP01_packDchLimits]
BO_ 2499747940 HVESP01_VoltageDiag: 8 HVESP01
 SG_ HVESP01_diagVPackPos : 16|16@1+ (0.01,0) [0|655.35] "v"  HVESP01
 SG_ HVESP01_diagVPackNeg : 0|16@1+ (0.01,0) [0|655.35] "v"  HVESP01
 SG_ HVESP01_diagVLoadNeg : 32|16@1+ (0.01,0) [0|655.35] "v"  HVESP01
 SG_ HVESP01_diagVLoadPos : 48|16@1+ (0.01,0) [0|655.35] "v"  HVESP01

BO_ 2499742564 HVESP01_packDchLimits: 8 HVESP01
 SG_ HVESP01_vBusMin : 48|16@1+ (0.01,0) [0|655.35] "V"  HVESP01
 SG_ HVESP01_iPackDchLimitInst : 16|16@1- (0.1,0) [-3276.8|0] "A"  HVESP01
 SG_ HVESP01_iPackDchLimit10s : 0|16@1- (-0.1,0) [-3276.7|0] "A"  HVESP01
 SG_ HVESP01_iPackDchLimitCont : 32|16@1- (0.02,0) [-655.36|0] "A"  HVESP01

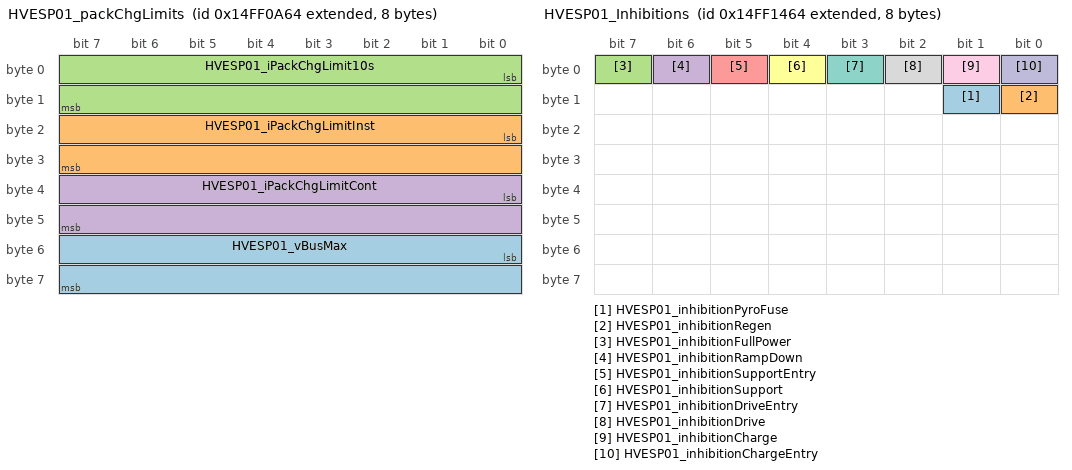
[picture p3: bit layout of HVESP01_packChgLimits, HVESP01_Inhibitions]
BO_ 2499742308 HVESP01_packChgLimits: 8 HVESP01
 SG_ HVESP01_vBusMax : 48|16@1+ (0.01,0) [0|655.35] "V"  HVESP01
 SG_ HVESP01_iPackChgLimitInst : 16|16@1+ (0.025,0) [0|1638.375] "A"  HVESP01
 SG_ HVESP01_iPackChgLimit10s : 0|16@1+ (0.025,0) [0|1638.375] "A"  HVESP01
 SG_ HVESP01_iPackChgLimitCont : 32|16@1+ (0.01,0) [0|655.35] "A"  HVESP01

BO_ 2499741796 HVESP01_InternalResistance: 8 HVESP01
 SG_ HVESP01_brickResistance_01_ m0 : 8|14@1+ (0.01,0) [0|50] "mOhm"  HVESP01
 SG_ HVESP01_brickResistance_02_ m0 : 22|14@1+ (0.01,0) [0|50] "mOhm"  HVESP01
 SG_ HVESP01_brickResistance_03_ m0 : 36|14@1+ (0.01,0) [0|50] "mOhm"  HVESP01
 SG_ HVESP01_brickResistance_04_ m0 : 50|14@1+ (0.01,0) [0|50] "mOhm"  HVESP01
 SG_ HVESP01_brickResistance_05_ m1 : 8|14@1+ (0.01,0) [0|50] "mOhm"  HVESP01
 SG_ HVESP01_brickResistance_06_ m1 : 22|14@1+ (0.01,0) [0|50] "mOhm"  HVESP01
 SG_ HVESP01_brickResistance_07_ m1 : 36|14@1+ (0.01,0) [0|50] "mOhm"  HVESP01
 SG_ HVESP01_brickResistance_08_ m1 : 50|14@1+ (0.01,0) [0|50] "mOhm"  HVESP01
 SG_ HVESP01_brickResistance_09_ m2 : 8|14@1+ (0.01,0) [0|50] "mOhm"  HVESP01
 SG_ HVESP01_brickResistance_10_ m2 : 22|14@1+ (0.01,0) [0|50] "mOhm"  HVESP01
 SG_ HVESP01_brickResistance_11_ m2 : 36|14@1+ (0.01,0) [0|50] "mOhm"  HVESP01
 SG_ HVESP01_brickResistance_12_ m2 : 50|14@1+ (0.01,0) [0|50] "mOhm"  HVESP01
 SG_ HVESP01_brickResistance_13_ m3 : 8|14@1+ (0.01,0) [0|50] "mOhm"  HVESP01
 SG_ HVESP01_brickResistance_14_ m3 : 22|14@1+ (0.01,0) [0|50] "mOhm"  HVESP01
 SG_ HVESP01_brickResistance_15_ m3 : 36|14@1+ (0.01,0) [0|50] "mOhm"  HVESP01
 SG_ HVESP01_brickResistance_16_ m3 : 50|14@1+ (0.01,0) [0|50] "mOhm"  HVESP01
 SG_ HVESP01_brickResistance_17_ m4 : 8|14@1+ (0.01,0) [0|50] "mOhm"  HVESP01
 SG_ HVESP01_brickResistance_18_ m4 : 22|14@1+ (0.01,0) [0|50] "mOhm"  HVESP01
 SG_ HVESP01_brickResistance_19_ m4 : 36|14@1+ (0.01,0) [0|50] "mOhm"  HVESP01
 SG_ HVESP01_brickResistance_20_ m4 : 50|14@1+ (0.01,0) [0|50] "mOhm"  HVESP01
 SG_ HVESP01_brickResistance_21_ m5 : 8|14@1+ (0.01,0) [0|50] "mOhm"  HVESP01
 SG_ HVESP01_brickResistance_22_ m5 : 22|14@1+ (0.01,0) [0|50] "mOhm"  HVESP01
 SG_ HVESP01_brickResistance_23_ m5 : 36|14@1+ (0.01,0) [0|50] "mOhm"  HVESP01
 SG_ HVESP01_brickResistance_24_ m5 : 50|14@1+ (0.01,0) [0|50] "mOhm"  HVESP01
 SG_ HVESP01_brickResistance_25_ m6 : 8|14@1+ (0.01,0) [0|50] "mOhm"  HVESP01
 SG_ HVESP01_brickResistance_26_ m6 : 22|14@1+ (0.01,0) [0|50] "mOhm"  HVESP01
 SG_ HVESP01_brickResistance_27_ m6 : 36|14@1+ (0.01,0) [0|50] "mOhm"  HVESP01
 SG_ HVESP01_brickResistance_28_ m6 : 50|14@1+ (0.01,0) [0|50] "mOhm"  HVESP01
 SG_ HVESP01_brickResistance_29_ m7 : 8|14@1+ (0.01,0) [0|50] "mOhm"  HVESP01
 SG_ HVESP01_brickResistance_30_ m7 : 22|14@1+ (0.01,0) [0|50] "mOhm"  HVESP01
 SG_ HVESP01_brickResistance_31_ m7 : 36|14@1+ (0.01,0) [0|50] "mOhm"  HVESP01
 SG_ HVESP01_brickResistance_32_ m7 : 50|14@1+ (0.01,0) [0|50] "mOhm"  HVESP01
 SG_ HVESP01_brickResistance_33_ m8 : 8|14@1+ (0.01,0) [0|50] "mOhm"  HVESP01
 SG_ HVESP01_brickResistance_34_ m8 : 22|14@1+ (0.01,0) [0|50] "mOhm"  HVESP01
 SG_ HVESP01_brickResistance_35_ m8 : 36|14@1+ (0.01,0) [0|50] "mOhm"  HVESP01
 SG_ HVESP01_brickResistance_36_ m8 : 50|14@1+ (0.01,0) [0|50] "mOhm"  HVESP01
 SG_ HVESP01_brickResistance_37_ m9 : 8|14@1+ (0.01,0) [0|50] "mOhm"  HVESP01
 SG_ HVESP01_brickResistance_38_ m9 : 22|14@1+ (0.01,0) [0|50] "mOhm"  HVESP01
 SG_ HVESP01_brickResistance_39_ m9 : 36|14@1+ (0.01,0) [0|50] "mOhm"  HVESP01
 SG_ HVESP01_brickResistance_40_ m9 : 50|14@1+ (0.01,0) [0|50] "mOhm"  HVESP01
 SG_ HVESP01_brickResistance_41_ m10 : 8|14@1+ (0.01,0) [0|50] "mOhm"  HVESP01
 SG_ HVESP01_brickResistance_42_ m10 : 22|14@1+ (0.01,0) [0|50] "mOhm"  HVESP01
 SG_ HVESP01_brickResistance_43_ m10 : 36|14@1+ (0.01,0) [0|50] "mOhm"  HVESP01
 SG_ HVESP01_brickResistance_44_ m10 : 50|14@1+ (0.01,0) [0|50] "mOhm"  HVESP01
 SG_ HVESP01_brickResistance_45_ m11 : 8|14@1+ (0.01,0) [0|50] "mOhm"  HVESP01
 SG_ HVESP01_brickResistance_46_ m11 : 22|14@1+ (0.01,0) [0|50] "mOhm"  HVESP01
 SG_ HVESP01_brickResistance_47_ m11 : 36|14@1+ (0.01,0) [0|50] "mOhm"  HVESP01
 SG_ HVESP01_brickResistance_48_ m11 : 50|14@1+ (0.01,0) [0|50] "mOhm"  HVESP01
 SG_ HVESP01_brickResistance_49_ m12 : 8|14@1+ (0.01,0) [0|50] "mOhm"  HVESP01
 SG_ HVESP01_brickResistance_50_ m12 : 22|14@1+ (0.01,0) [0|50] "mOhm"  HVESP01
 SG_ HVESP01_brickResistance_51_ m12 : 36|14@1+ (0.01,0) [0|50] "mOhm"  HVESP01
 SG_ HVESP01_brickResistance_52_ m12 : 50|14@1+ (0.01,0) [0|50] "mOhm"  HVESP01
 SG_ HVESP01_brickResistance_53_ m13 : 8|14@1+ (0.01,0) [0|50] "mOhm"  HVESP01
 SG_ HVESP01_brickResistance_54_ m13 : 22|14@1+ (0.01,0) [0|50] "mOhm"  HVESP01
 SG_ HVESP01_brickResistance_55_ m13 : 36|14@1+ (0.01,0) [0|50] "mOhm"  HVESP01
 SG_ HVESP01_brickResistance_56_ m13 : 50|14@1+ (0.01,0) [0|50] "mOhm"  HVESP01
 SG_ HVESP01_brickResistance_57_ m14 : 8|14@1+ (0.01,0) [0|50] "mOhm"  HVESP01
 SG_ HVESP01_brickResistance_58_ m14 : 22|14@1+ (0.01,0) [0|50] "mOhm"  HVESP01
 SG_ HVESP01_brickResistance_59_ m14 : 36|14@1+ (0.01,0) [0|50] "mOhm"  HVESP01
 SG_ HVESP01_brickResistance_60_ m14 : 50|14@1+ (0.01,0) [0|50] "mOhm"  HVESP01
 SG_ HVESP01_brickResistance_61_ m15 : 8|14@1+ (0.01,0) [0|50] "mOhm"  HVESP01
 SG_ HVESP01_brickResistance_62_ m15 : 22|14@1+ (0.01,0) [0|50] "mOhm"  HVESP01
 SG_ HVESP01_brickResistance_63_ m15 : 36|14@1+ (0.01,0) [0|50] "mOhm"  HVESP01
 SG_ HVESP01_brickResistance_64_ m15 : 50|14@1+ (0.01,0) [0|50] "mOhm"  HVESP01
 SG_ HVESP01_brickResistance_65_ m16 : 8|14@1+ (0.01,0) [0|50] "mOhm"  HVESP01
 SG_ HVESP01_brickResistance_66_ m16 : 22|14@1+ (0.01,0) [0|50] "mOhm"  HVESP01
 SG_ HVESP01_brickResistance_67_ m16 : 36|14@1+ (0.01,0) [0|50] "mOhm"  HVESP01
 SG_ HVESP01_brickResistance_68_ m16 : 50|14@1+ (0.01,0) [0|50] "mOhm"  HVESP01
 SG_ HVESP01_brickResistance_69_ m17 : 8|14@1+ (0.01,0) [0|50] "mOhm"  HVESP01
 SG_ HVESP01_brickResistance_70_ m17 : 22|14@1+ (0.01,0) [0|50] "mOhm"  HVESP01
 SG_ HVESP01_brickResistance_71_ m17 : 36|14@1+ (0.01,0) [0|50] "mOhm"  HVESP01
 SG_ HVESP01_brickResistance_72_ m17 : 50|14@1+ (0.01,0) [0|50] "mOhm"  HVESP01
 SG_ HVESP01_brickResistance_73_ m18 : 8|14@1+ (0.01,0) [0|50] "mOhm"  HVESP01
 SG_ HVESP01_brickResistance_74_ m18 : 22|14@1+ (0.01,0) [0|50] "mOhm"  HVESP01
 SG_ HVESP01_brickResistance_75_ m18 : 36|14@1+ (0.01,0) [0|50] "mOhm"  HVESP01
 SG_ HVESP01_brickResistance_76_ m18 : 50|14@1+ (0.01,0) [0|50] "mOhm"  HVESP01
 SG_ HVESP01_brickResistance_77_ m19 : 8|14@1+ (0.01,0) [0|50] "mOhm"  HVESP01
 SG_ HVESP01_brickResistance_78_ m19 : 22|14@1+ (0.01,0) [0|50] "mOhm"  HVESP01
 SG_ HVESP01_brickResistance_79_ m19 : 36|14@1+ (0.01,0) [0|50] "mOhm"  HVESP01
 SG_ HVESP01_brickResistance_80_ m19 : 50|14@1+ (0.01,0) [0|50] "mOhm"  HVESP01
 SG_ HVESP01_brickResistance_81_ m20 : 8|14@1+ (0.01,0) [0|50] "mOhm"  HVESP01
 SG_ HVESP01_brickResistance_82_ m20 : 22|14@1+ (0.01,0) [0|50] "mOhm"  HVESP01
 SG_ HVESP01_brickResistance_83_ m20 : 36|14@1+ (0.01,0) [0|50] "mOhm"  HVESP01
 SG_ HVESP01_brickResistance_84_ m20 : 50|14@1+ (0.01,0) [0|50] "mOhm"  HVESP01
 SG_ HVESP01_brickResistance_85_ m21 : 8|14@1+ (0.01,0) [0|50] "mOhm"  HVESP01
 SG_ HVESP01_brickResistance_86_ m21 : 22|14@1+ (0.01,0) [0|50] "mOhm"  HVESP01
 SG_ HVESP01_brickResistance_87_ m21 : 36|14@1+ (0.01,0) [0|50] "mOhm"  HVESP01
 SG_ HVESP01_brickResistance_88_ m21 : 50|14@1+ (0.01,0) [0|50] "mOhm"  HVESP01
 SG_ HVESP01_brickResistance_89_ m22 : 8|14@1+ (0.01,0) [0|50] "mOhm"  HVESP01
 SG_ HVESP01_brickResistance_90_ m22 : 22|14@1+ (0.01,0) [0|50] "mOhm"  HVESP01
 SG_ HVESP01_brickResistance_91_ m22 : 36|14@1+ (0.01,0) [0|50] "mOhm"  HVESP01
 SG_ HVESP01_brickResistance_92_ m22 : 50|14@1+ (0.01,0) [0|50] "mOhm"  HVESP01
 SG_ HVESP01_brickResistance_93_ m23 : 8|14@1+ (0.01,0) [0|50] "mOhm"  HVESP01
 SG_ HVESP01_brickResistance_94_ m23 : 22|14@1+ (0.01,0) [0|50] "mOhm"  HVESP01
 SG_ HVESP01_brickResistance_95_ m23 : 36|14@1+ (0.01,0) [0|50] "mOhm"  HVESP01
 SG_ HVESP01_brickResistance_96_ m23 : 50|14@1+ (0.01,0) [0|50] "mOhm"  HVESP01
 SG_ HVESP01_brickResistance_97_ m24 : 8|14@1+ (0.01,0) [0|50] "mOhm"  HVESP01
 SG_ HVESP01_brickResistance_98_ m24 : 22|14@1+ (0.01,0) [0|50] "mOhm"  HVESP01
 SG_ HVESP01_brickResistance_99_ m24 : 36|14@1+ (0.01,0) [0|50] "mOhm"  HVESP01
 SG_ HVESP01_brickResistance_100 m24 : 50|14@1+ (0.01,0) [0|50] "mOhm"  HVESP01
 SG_ HVESP01_brickResistance_101 m25 : 8|14@1+ (0.01,0) [0|50] "mOhm"  HVESP01
 SG_ HVESP01_brickResistance_102 m25 : 22|14@1+ (0.01,0) [0|50] "mOhm"  HVESP01
 SG_ HVESP01_brickResistance_103 m25 : 36|14@1+ (0.01,0) [0|50] "mOhm"  HVESP01
 SG_ HVESP01_brickResistance_104 m25 : 50|14@1+ (0.01,0) [0|50] "mOhm"  HVESP01
 SG_ HVESP01_brickResistance_105 m26 : 8|14@1+ (0.01,0) [0|50] "mOhm"  HVESP01
 SG_ HVESP01_brickResistance_106 m26 : 22|14@1+ (0.01,0) [0|50] "mOhm"  HVESP01
 SG_ HVESP01_brickResistance_107 m26 : 36|14@1+ (0.01,0) [0|50] "mOhm"  HVESP01
 SG_ HVESP01_brickResistance_108 m26 : 50|14@1+ (0.01,0) [0|50] "mOhm"  HVESP01
 SG_ HVESP01_brickResistance_109 m27 : 8|14@1+ (0.01,0) [0|50] "mOhm"  HVESP01
 SG_ HVESP01_brickResistance_110 m27 : 22|14@1+ (0.01,0) [0|50] "mOhm"  HVESP01
 SG_ HVESP01_brickResistance_111 m27 : 36|14@1+ (0.01,0) [0|50] "mOhm"  HVESP01
 SG_ HVESP01_brickResistance_112 m27 : 50|14@1+ (0.01,0) [0|50] "mOhm"  HVESP01
 SG_ HVESP01_brickResistance_113 m28 : 8|14@1+ (0.01,0) [0|50] "mOhm"  HVESP01
 SG_ HVESP01_brickResistance_114 m28 : 22|14@1+ (0.01,0) [0|50] "mOhm"  HVESP01
 SG_ HVESP01_brickResistance_115 m28 : 36|14@1+ (0.01,0) [0|50] "mOhm"  HVESP01
 SG_ HVESP01_brickResistance_116 m28 : 50|14@1+ (0.01,0) [0|50] "mOhm"  HVESP01
 SG_ HVESP01_brickResistance_117 m29 : 8|14@1+ (0.01,0) [0|50] "mOhm"  HVESP01
 SG_ HVESP01_brickResistance_118 m29 : 22|14@1+ (0.01,0) [0|50] "mOhm"  HVESP01
 SG_ HVESP01_brickResistance_119 m29 : 36|14@1+ (0.01,0) [0|50] "mOhm"  HVESP01
 SG_ HVESP01_brickResistance_120 m29 : 50|14@1+ (0.01,0) [0|50] "mOhm"  HVESP01
 SG_ HVESP01_brickResistance_121 m30 : 8|14@1+ (0.01,0) [0|50] "mOhm"  HVESP01
 SG_ HVESP01_brickResistance_122 m30 : 22|14@1+ (0.01,0) [0|50] "mOhm"  HVESP01
 SG_ HVESP01_brickResistance_123 m30 : 36|14@1+ (0.01,0) [0|50] "mOhm"  HVESP01
 SG_ HVESP01_brickResistance_124 m30 : 50|14@1+ (0.01,0) [0|50] "mOhm"  HVESP01
 SG_ HVESP01_brickResistance_125 m31 : 8|14@1+ (0.01,0) [0|50] "mOhm"  HVESP01
 SG_ HVESP01_brickResistance_126 m31 : 22|14@1+ (0.01,0) [0|50] "mOhm"  HVESP01
 SG_ HVESP01_brickResistance_127 m31 : 36|14@1+ (0.01,0) [0|50] "mOhm"  HVESP01
 SG_ HVESP01_brickResistance_128 m31 : 50|14@1+ (0.01,0) [0|50] "mOhm"  HVESP01
 SG_ HVESP01_brickResistance_129 m32 : 8|14@1+ (0.01,0) [0|50] "mOhm"  HVESP01
 SG_ HVESP01_brickResistance_130 m32 : 22|14@1+ (0.01,0) [0|50] "mOhm"  HVESP01
 SG_ HVESP01_brickResistance_131 m32 : 36|14@1+ (0.01,0) [0|50] "mOhm"  HVESP01
 SG_ HVESP01_brickResistance_132 m32 : 50|14@1+ (0.01,0) [0|50] "mOhm"  HVESP01
 SG_ HVESP01_brickResistance_133 m33 : 8|14@1+ (0.01,0) [0|50] "mOhm"  HVESP01
 SG_ HVESP01_brickResistance_134 m33 : 22|14@1+ (0.01,0) [0|50] "mOhm"  HVESP01
 SG_ HVESP01_brickResistance_135 m33 : 36|14@1+ (0.01,0) [0|50] "mOhm"  HVESP01
 SG_ HVESP01_brickResistance_136 m33 : 50|14@1+ (0.01,0) [0|50] "mOhm"  HVESP01
 SG_ HVESP01_brickResistance_137 m34 : 8|14@1+ (0.01,0) [0|50] "mOhm"  HVESP01
 SG_ HVESP01_brickResistance_138 m34 : 22|14@1+ (0.01,0) [0|50] "mOhm"  HVESP01
 SG_ HVESP01_brickResistance_139 m34 : 36|14@1+ (0.01,0) [0|50] "mOhm"  HVESP01
 SG_ HVESP01_brickResistance_140 m34 : 50|14@1+ (0.01,0) [0|50] "mOhm"  HVESP01
 SG_ HVESP01_brickResistance_141 m35 : 8|14@1+ (0.01,0) [0|50] "mOhm"  HVESP01
 SG_ HVESP01_brickResistance_142 m35 : 22|14@1+ (0.01,0) [0|50] "mOhm"  HVESP01
 SG_ HVESP01_brickResistance_143 m35 : 36|14@1+ (0.01,0) [0|50] "mOhm"  HVESP01
 SG_ HVESP01_brickResistance_144 m35 : 50|14@1+ (0.01,0) [0|50] "mOhm"  HVESP01
 SG_ HVESP01_brickResistance_145 m36 : 8|14@1+ (0.01,0) [0|50] "mOhm"  HVESP01
 SG_ HVESP01_brickResistance_146 m36 : 22|14@1+ (0.01,0) [0|50] "mOhm"  HVESP01
 SG_ HVESP01_brickResistance_147 m36 : 36|14@1+ (0.01,0) [0|50] "mOhm"  HVESP01
 SG_ HVESP01_brickResistance_148 m36 : 50|14@1+ (0.01,0) [0|50] "mOhm"  HVESP01
 SG_ HVESP01_brickResistance_149 m37 : 8|14@1+ (0.01,0) [0|50] "mOhm"  HVESP01
 SG_ HVESP01_brickResistance_150 m37 : 22|14@1+ (0.01,0) [0|50] "mOhm"  HVESP01
 SG_ HVESP01_brickResistance_151 m37 : 36|14@1+ (0.01,0) [0|50] "mOhm"  HVESP01
 SG_ HVESP01_brickResistance_152 m37 : 50|14@1+ (0.01,0) [0|50] "mOhm"  HVESP01
 SG_ HVESP01_brickResistance_153 m38 : 8|14@1+ (0.01,0) [0|50] "mOhm"  HVESP01
 SG_ HVESP01_brickResistance_154 m38 : 22|14@1+ (0.01,0) [0|50] "mOhm"  HVESP01
 SG_ HVESP01_brickResistance_155 m38 : 36|14@1+ (0.01,0) [0|50] "mOhm"  HVESP01
 SG_ HVESP01_brickResistance_156 m38 : 50|14@1+ (0.01,0) [0|50] "mOhm"  HVESP01
 SG_ HVESP01_brickResistance_157 m39 : 8|14@1+ (0.01,0) [0|50] "mOhm"  HVESP01
 SG_ HVESP01_brickResistance_158 m39 : 22|14@1+ (0.01,0) [0|50] "mOhm"  HVESP01
 SG_ HVESP01_brickResistance_159 m39 : 36|14@1+ (0.01,0) [0|50] "mOhm"  HVESP01
 SG_ HVESP01_brickResistance_160 m39 : 50|14@1+ (0.01,0) [0|50] "mOhm"  HVESP01
 SG_ HVESP01_brickResistance_161 m40 : 8|14@1+ (0.01,0) [0|50] "mOhm"  HVESP01
 SG_ HVESP01_brickResistance_162 m40 : 22|14@1+ (0.01,0) [0|50] "mOhm"  HVESP01
 SG_ HVESP01_brickResistance_163 m40 : 36|14@1+ (0.01,0) [0|50] "mOhm"  HVESP01
 SG_ HVESP01_brickResistance_164 m40 : 50|14@1+ (0.01,0) [0|50] "mOhm"  HVESP01
 SG_ HVESP01_brickResistance_165 m41 : 8|14@1+ (0.01,0) [0|50] "mOhm"  HVESP01
 SG_ HVESP01_brickResistance_166 m41 : 22|14@1+ (0.01,0) [0|50] "mOhm"  HVESP01
 SG_ HVESP01_brickResistance_167 m41 : 36|14@1+ (0.01,0) [0|50] "mOhm"  HVESP01
 SG_ HVESP01_brickResistance_168 m41 : 50|14@1+ (0.01,0) [0|50] "mOhm"  HVESP01
 SG_ HVESP01_brickResistance_169 m42 : 8|14@1+ (0.01,0) [0|50] "mOhm"  HVESP01
 SG_ HVESP01_brickResistance_170 m42 : 22|14@1+ (0.01,0) [0|50] "mOhm"  HVESP01
 SG_ HVESP01_brickResistance_171 m42 : 36|14@1+ (0.01,0) [0|50] "mOhm"  HVESP01
 SG_ HVESP01_brickResistance_172 m42 : 50|14@1+ (0.01,0) [0|50] "mOhm"  HVESP01
 SG_ HVESP01_brickResistance_173 m43 : 8|14@1+ (0.01,0) [0|50] "mOhm"  HVESP01
 SG_ HVESP01_brickResistance_174 m43 : 22|14@1+ (0.01,0) [0|50] "mOhm"  HVESP01
 SG_ HVESP01_brickResistance_175 m43 : 36|14@1+ (0.01,0) [0|50] "mOhm"  HVESP01
 SG_ HVESP01_brickResistance_176 m43 : 50|14@1+ (0.01,0) [0|50] "mOhm"  HVESP01
 SG_ HVESP01_brickResistance_177 m44 : 8|14@1+ (0.01,0) [0|50] "mOhm"  HVESP01
 SG_ HVESP01_brickResistance_178 m44 : 22|14@1+ (0.01,0) [0|50] "mOhm"  HVESP01
 SG_ HVESP01_brickResistance_179 m44 : 36|14@1+ (0.01,0) [0|50] "mOhm"  HVESP01
 SG_ HVESP01_brickResistance_180 m44 : 50|14@1+ (0.01,0) [0|50] "mOhm"  HVESP01
 SG_ multiplexorbr M : 0|8@1+ (1,0) [0|255] ""  HVESP01

BO_ 2499742052 HVESP01_modTemperature: 8 HVESP01
 SG_ HVESP01_modTemperature_01 m0 : 16|8@1- (1,25) [-103|152] "Celsius"  HVESP01
 SG_ HVESP01_modTemperature_02 m0 : 24|8@1- (1,25) [-103|152] "Celsius"  HVESP01
 SG_ HVESP01_modTemperature_03 m0 : 32|8@1- (1,25) [-103|152] "Celsius"  HVESP01
 SG_ HVESP01_modTemperature_04 m0 : 40|8@1- (1,25) [-103|152] "Celsius"  HVESP01
 SG_ HVESP01_modTemperature_05 m0 : 48|8@1- (1,25) [-103|152] "Celsius"  HVESP01
 SG_ HVESP01_modTemperature_06 m1 : 16|8@1- (1,25) [-103|152] "Celsius"  HVESP01
 SG_ HVESP01_modTemperature_07 m1 : 24|8@1- (1,25) [-103|152] "Celsius"  HVESP01
 SG_ HVESP01_modTemperature_08 m1 : 32|8@1- (1,25) [-103|152] "Celsius"  HVESP01
 SG_ HVESP01_modTemperature_09 m1 : 40|8@1- (1,25) [-103|152] "Celsius"  HVESP01
 SG_ HVESP01_modTemperature_10 m1 : 48|8@1- (1,25) [-103|152] "Celsius"  HVESP01
 SG_ HVESP01_modTemperature_11 m2 : 16|8@1- (1,25) [-103|152] "Celsius"  HVESP01
 SG_ HVESP01_modTemperature_12 m2 : 24|8@1- (1,25) [-103|152] "Celsius"  HVESP01
 SG_ HVESP01_modTemperature_13 m2 : 32|8@1- (1,25) [-103|152] "Celsius"  HVESP01
 SG_ HVESP01_modTemperature_14 m2 : 40|8@1- (1,25) [-103|152] "Celsius"  HVESP01
 SG_ HVESP01_modTemperature_15 m2 : 48|8@1- (1,25) [-103|152] "Celsius"  HVESP01
 SG_ HVESP01_modTemperature_16 m3 : 16|8@1- (1,25) [-103|152] "Celsius"  HVESP01
 SG_ HVESP01_modTemperature_17 m3 : 24|8@1- (1,25) [-103|152] "Celsius"  HVESP01
 SG_ HVESP01_modTemperature_18 m3 : 32|8@1- (1,25) [-103|152] "Celsius"  HVESP01
 SG_ HVESP01_modTemperature_19 m3 : 40|8@1- (1,25) [-103|152] "Celsius"  HVESP01
 SG_ HVESP01_modTemperature_20 m3 : 48|8@1- (1,25) [-103|152] "Celsius"  HVESP01
 SG_ HVESP01_modTemperature_21 m4 : 16|8@1- (1,25) [-103|152] "Celsius"  HVESP01
 SG_ HVESP01_modTemperature_22 m4 : 24|8@1- (1,25) [-103|152] "Celsius"  HVESP01
 SG_ HVESP01_modTemperature_23 m4 : 32|8@1- (1,25) [-103|152] "Celsius"  HVESP01
 SG_ HVESP01_modTemperature_24 m4 : 40|8@1- (1,25) [-103|152] "Celsius"  HVESP01
 SG_ HVESP01_modTemperature_25 m4 : 48|8@1- (1,25) [-103|152] "Celsius"  HVESP01
 SG_ HVESP01_modTemperature_26 m5 : 16|8@1- (1,25) [-103|152] "Celsius"  HVESP01
 SG_ HVESP01_modTemperature_27 m5 : 24|8@1- (1,25) [-103|152] "Celsius"  HVESP01
 SG_ HVESP01_modTemperature_28 m5 : 32|8@1- (1,25) [-103|152] "Celsius"  HVESP01
 SG_ HVESP01_modTemperature_29 m5 : 40|8@1- (1,25) [-103|152] "Celsius"  HVESP01
 SG_ HVESP01_modTemperature_30 m5 : 48|8@1- (1,25) [-103|152] "Celsius"  HVESP01
 SG_ HVESP01_modTemperature_31 m6 : 16|8@1- (1,25) [-103|152] "Celsius"  HVESP01
 SG_ HVESP01_modTemperature_32 m6 : 24|8@1- (1,25) [-103|152] "Celsius"  HVESP01
 SG_ HVESP01_modTemperature_33 m6 : 32|8@1- (1,25) [-103|152] "Celsius"  HVESP01
 SG_ HVESP01_modTemperature_34 m6 : 40|8@1- (1,25) [-103|152] "Celsius"  HVESP01
 SG_ HVESP01_modTemperature_35 m6 : 48|8@1- (1,25) [-103|152] "Celsius"  HVESP01
 SG_ HVESP01_modTemperature_36 m7 : 16|8@1- (1,25) [-103|152] "Celsius"  HVESP01
 SG_ HVESP01_modTemperature_37 m7 : 24|8@1- (1,25) [-103|152] "Celsius"  HVESP01
 SG_ HVESP01_modTemperature_38 m7 : 32|8@1- (1,25) [-103|152] "Celsius"  HVESP01
 SG_ HVESP01_modTemperature_39 m7 : 40|8@1- (1,25) [-103|152] "Celsius"  HVESP01
 SG_ HVESP01_modTemperature_40 m7 : 48|8@1- (1,25) [-103|152] "Celsius"  HVESP01
 SG_ HVESP01_modTemperature_41 m8 : 16|8@1- (1,25) [-103|152] "Celsius"  HVESP01
 SG_ HVESP01_modTemperature_42 m8 : 24|8@1- (1,25) [-103|152] "Celsius"  HVESP01
 SG_ HVESP01_modTemperature_43 m8 : 32|8@1- (1,25) [-103|152] "Celsius"  HVESP01
 SG_ HVESP01_modTemperature_44 m8 : 40|8@1- (1,25) [-103|152] "Celsius"  HVESP01
 SG_ HVESP01_modTemperature_45 m8 : 48|8@1- (1,25) [-103|152] "Celsius"  HVESP01
 SG_ HVESP01_modTemperature_46 m9 : 16|8@1- (1,25) [-103|152] "Celsius"  HVESP01
 SG_ HVESP01_modTemperature_47 m9 : 24|8@1- (1,25) [-103|152] "Celsius"  HVESP01
 SG_ HVESP01_modTemperature_48 m9 : 32|8@1- (1,25) [-103|152] "Celsius"  HVESP01
 SG_ HVESP01_modTemperature_49 m9 : 40|8@1- (1,25) [-103|152] "Celsius"  HVESP01
 SG_ HVESP01_modTemperature_50 m9 : 48|8@1- (1,25) [-103|152] "Celsius"  HVESP01
 SG_ multiplexormt M : 0|9@1+ (1,0) [0|255] ""  HVESP01

BO_ 2499741540 HVESP01_cellVoltage: 8 HVESP01
 SG_ HVESP01_cellVoltage_01 m0 : 8|14@1+ (0.001,0) [0|16.383] "V"  HVESP01
 SG_ HVESP01_cellVoltage_02 m0 : 22|14@1+ (0.001,0) [0|16.383] "V"  HVESP01
 SG_ HVESP01_cellVoltage_03 m0 : 36|14@1+ (0.001,0) [0|16.383] "V"  HVESP01
 SG_ HVESP01_cellVoltage_04 m0 : 50|14@1+ (0.001,0) [0|16.383] "V"  HVESP01
 SG_ HVESP01_cellVoltage_05 m1 : 8|14@1+ (0.001,0) [0|16.383] "V"  HVESP01
 SG_ HVESP01_cellVoltage_06 m1 : 22|14@1+ (0.001,0) [0|16.383] "V"  HVESP01
 SG_ HVESP01_cellVoltage_07 m1 : 36|14@1+ (0.001,0) [0|16.383] "V"  HVESP01
 SG_ HVESP01_cellVoltage_08 m1 : 50|14@1+ (0.001,0) [0|16.383] "V"  HVESP01
 SG_ HVESP01_cellVoltage_09 m2 : 8|14@1+ (0.001,0) [0|16.383] "V"  HVESP01
 SG_ HVESP01_cellVoltage_10 m2 : 22|14@1+ (0.001,0) [0|16.383] "V"  HVESP01
 SG_ HVESP01_cellVoltage_11 m2 : 36|14@1+ (0.001,0) [0|16.383] "V"  HVESP01
 SG_ HVESP01_cellVoltage_12 m2 : 50|14@1+ (0.001,0) [0|16.383] "V"  HVESP01
 SG_ HVESP01_cellVoltage_13 m3 : 8|14@1+ (0.001,0) [0|16.383] "V"  HVESP01
 SG_ HVESP01_cellVoltage_14 m3 : 22|14@1+ (0.001,0) [0|16.383] "V"  HVESP01
 SG_ HVESP01_cellVoltage_15 m3 : 36|14@1+ (0.001,0) [0|16.383] "V"  HVESP01
 SG_ HVESP01_cellVoltage_16 m3 : 50|14@1+ (0.001,0) [0|16.383] "V"  HVESP01
 SG_ HVESP01_cellVoltage_17 m4 : 8|14@1+ (0.001,0) [0|16.383] "V"  HVESP01
 SG_ HVESP01_cellVoltage_18 m4 : 22|14@1+ (0.001,0) [0|16.383] "V"  HVESP01
 SG_ HVESP01_cellVoltage_19 m4 : 36|14@1+ (0.001,0) [0|16.383] "V"  HVESP01
 SG_ HVESP01_cellVoltage_20 m4 : 50|14@1+ (0.001,0) [0|16.383] "V"  HVESP01
 SG_ HVESP01_cellVoltage_21 m5 : 8|14@1+ (0.001,0) [0|16.383] "V"  HVESP01
 SG_ HVESP01_cellVoltage_22 m5 : 22|14@1+ (0.001,0) [0|16.383] "V"  HVESP01
 SG_ HVESP01_cellVoltage_23 m5 : 36|14@1+ (0.001,0) [0|16.383] "V"  HVESP01
 SG_ HVESP01_cellVoltage_24 m5 : 50|14@1+ (0.001,0) [0|16.383] "V"  HVESP01
 SG_ HVESP01_cellVoltage_25 m6 : 8|14@1+ (0.001,0) [0|16.383] "V"  HVESP01
 SG_ HVESP01_cellVoltage_26 m6 : 22|14@1+ (0.001,0) [0|16.383] "V"  HVESP01
 SG_ HVESP01_cellVoltage_27 m6 : 36|14@1+ (0.001,0) [0|16.383] "V"  HVESP01
 SG_ HVESP01_cellVoltage_28 m6 : 50|14@1+ (0.001,0) [0|16.383] "V"  HVESP01
 SG_ HVESP01_cellVoltage_29 m7 : 8|14@1+ (0.001,0) [0|16.383] "V"  HVESP01
 SG_ HVESP01_cellVoltage_30 m7 : 22|14@1+ (0.001,0) [0|16.383] "V"  HVESP01
 SG_ HVESP01_cellVoltage_31 m7 : 36|14@1+ (0.001,0) [0|16.383] "V"  HVESP01
 SG_ HVESP01_cellVoltage_32 m7 : 50|14@1+ (0.001,0) [0|16.383] "V"  HVESP01
 SG_ HVESP01_cellVoltage_33 m8 : 8|14@1+ (0.001,0) [0|16.383] "V"  HVESP01
 SG_ HVESP01_cellVoltage_34 m8 : 22|14@1+ (0.001,0) [0|16.383] "V"  HVESP01
 SG_ HVESP01_cellVoltage_35 m8 : 36|14@1+ (0.001,0) [0|16.383] "V"  HVESP01
 SG_ HVESP01_cellVoltage_36 m8 : 50|14@1+ (0.001,0) [0|16.383] "V"  HVESP01
 SG_ HVESP01_cellVoltage_37 m9 : 8|14@1+ (0.001,0) [0|16.383] "V"  HVESP01
 SG_ HVESP01_cellVoltage_38 m9 : 22|14@1+ (0.001,0) [0|16.383] "V"  HVESP01
 SG_ HVESP01_cellVoltage_39 m9 : 36|14@1+ (0.001,0) [0|16.383] "V"  HVESP01
 SG_ HVESP01_cellVoltage_40 m9 : 50|14@1+ (0.001,0) [0|16.383] "V"  HVESP01
 SG_ HVESP01_cellVoltage_41 m10 : 8|14@1+ (0.001,0) [0|16.383] "V"  HVESP01
 SG_ HVESP01_cellVoltage_42 m10 : 22|14@1+ (0.001,0) [0|16.383] "V"  HVESP01
 SG_ HVESP01_cellVoltage_43 m10 : 36|14@1+ (0.001,0) [0|16.383] "V"  HVESP01
 SG_ HVESP01_cellVoltage_44 m10 : 50|14@1+ (0.001,0) [0|16.383] "V"  HVESP01
 SG_ HVESP01_cellVoltage_45 m11 : 8|14@1+ (0.001,0) [0|16.383] "V"  HVESP01
 SG_ HVESP01_cellVoltage_46 m11 : 22|14@1+ (0.001,0) [0|16.383] "V"  HVESP01
 SG_ HVESP01_cellVoltage_47 m11 : 36|14@1+ (0.001,0) [0|16.383] "V"  HVESP01
 SG_ HVESP01_cellVoltage_48 m11 : 50|14@1+ (0.001,0) [0|16.383] "V"  HVESP01
 SG_ HVESP01_cellVoltage_49 m12 : 8|14@1+ (0.001,0) [0|16.383] "V"  HVESP01
 SG_ HVESP01_cellVoltage_50 m12 : 22|14@1+ (0.001,0) [0|16.383] "V"  HVESP01
 SG_ HVESP01_cellVoltage_51 m12 : 36|14@1+ (0.001,0) [0|16.383] "V"  HVESP01
 SG_ HVESP01_cellVoltage_52 m12 : 50|14@1+ (0.001,0) [0|16.383] "V"  HVESP01
 SG_ HVESP01_cellVoltage_53 m13 : 8|14@1+ (0.001,0) [0|16.383] "V"  HVESP01
 SG_ HVESP01_cellVoltage_54 m13 : 22|14@1+ (0.001,0) [0|16.383] "V"  HVESP01
 SG_ HVESP01_cellVoltage_55 m13 : 36|14@1+ (0.001,0) [0|16.383] "V"  HVESP01
 SG_ HVESP01_cellVoltage_56 m13 : 50|14@1+ (0.001,0) [0|16.383] "V"  HVESP01
 SG_ HVESP01_cellVoltage_57 m14 : 8|14@1+ (0.001,0) [0|16.383] "V"  HVESP01
 SG_ HVESP01_cellVoltage_58 m14 : 22|14@1+ (0.001,0) [0|16.383] "V"  HVESP01
 SG_ HVESP01_cellVoltage_59 m14 : 36|14@1+ (0.001,0) [0|16.383] "V"  HVESP01
 SG_ HVESP01_cellVoltage_60 m14 : 50|14@1+ (0.001,0) [0|16.383] "V"  HVESP01
 SG_ HVESP01_cellVoltage_61 m15 : 8|14@1+ (0.001,0) [0|16.383] "V"  HVESP01
 SG_ HVESP01_cellVoltage_62 m15 : 22|14@1+ (0.001,0) [0|16.383] "V"  HVESP01
 SG_ HVESP01_cellVoltage_63 m15 : 36|14@1+ (0.001,0) [0|16.383] "V"  HVESP01
 SG_ HVESP01_cellVoltage_64 m15 : 50|14@1+ (0.001,0) [0|16.383] "V"  HVESP01
 SG_ HVESP01_cellVoltage_65 m16 : 8|14@1+ (0.001,0) [0|16.383] "V"  HVESP01
 SG_ HVESP01_cellVoltage_66 m16 : 22|14@1+ (0.001,0) [0|16.383] "V"  HVESP01
 SG_ HVESP01_cellVoltage_67 m16 : 36|14@1+ (0.001,0) [0|16.383] "V"  HVESP01
 SG_ HVESP01_cellVoltage_68 m16 : 50|14@1+ (0.001,0) [0|16.383] "V"  HVESP01
 SG_ HVESP01_cellVoltage_69 m17 : 8|14@1+ (0.001,0) [0|16.383] "V"  HVESP01
 SG_ HVESP01_cellVoltage_70 m17 : 22|14@1+ (0.001,0) [0|16.383] "V"  HVESP01
 SG_ HVESP01_cellVoltage_71 m17 : 36|14@1+ (0.001,0) [0|16.383] "V"  HVESP01
 SG_ HVESP01_cellVoltage_72 m17 : 50|14@1+ (0.001,0) [0|16.383] "V"  HVESP01
 SG_ HVESP01_cellVoltage_73 m18 : 8|14@1+ (0.001,0) [0|16.383] "V"  HVESP01
 SG_ HVESP01_cellVoltage_74 m18 : 22|14@1+ (0.001,0) [0|16.383] "V"  HVESP01
 SG_ HVESP01_cellVoltage_75 m18 : 36|14@1+ (0.001,0) [0|16.383] "V"  HVESP01
 SG_ HVESP01_cellVoltage_76 m18 : 50|14@1+ (0.001,0) [0|16.383] "V"  HVESP01
 SG_ HVESP01_cellVoltage_77 m19 : 8|14@1+ (0.001,0) [0|16.383] "V"  HVESP01
 SG_ HVESP01_cellVoltage_78 m19 : 22|14@1+ (0.001,0) [0|16.383] "V"  HVESP01
 SG_ HVESP01_cellVoltage_79 m19 : 36|14@1+ (0.001,0) [0|16.383] "V"  HVESP01
 SG_ HVESP01_cellVoltage_80 m19 : 50|14@1+ (0.001,0) [0|16.383] "V"  HVESP01
 SG_ HVESP01_cellVoltage_81 m20 : 8|14@1+ (0.001,0) [0|16.383] "V"  HVESP01
 SG_ HVESP01_cellVoltage_82 m20 : 22|14@1+ (0.001,0) [0|16.383] "V"  HVESP01
 SG_ HVESP01_cellVoltage_83 m20 : 36|14@1+ (0.001,0) [0|16.383] "V"  HVESP01
 SG_ HVESP01_cellVoltage_84 m20 : 50|14@1+ (0.001,0) [0|16.383] "V"  HVESP01
 SG_ HVESP01_cellVoltage_85 m21 : 8|14@1+ (0.001,0) [0|16.383] "V"  HVESP01
 SG_ HVESP01_cellVoltage_86 m21 : 22|14@1+ (0.001,0) [0|16.383] "V"  HVESP01
 SG_ HVESP01_cellVoltage_87 m21 : 36|14@1+ (0.001,0) [0|16.383] "V"  HVESP01
 SG_ HVESP01_cellVoltage_88 m21 : 50|14@1+ (0.001,0) [0|16.383] "V"  HVESP01
 SG_ HVESP01_cellVoltage_89 m22 : 8|14@1+ (0.001,0) [0|16.383] "V"  HVESP01
 SG_ HVESP01_cellVoltage_90 m22 : 22|14@1+ (0.001,0) [0|16.383] "V"  HVESP01
 SG_ HVESP01_cellVoltage_91 m22 : 36|14@1+ (0.001,0) [0|16.383] "V"  HVESP01
 SG_ HVESP01_cellVoltage_92 m22 : 50|14@1+ (0.001,0) [0|16.383] "V"  HVESP01
 SG_ HVESP01_cellVoltage_93 m23 : 8|14@1+ (0.001,0) [0|16.383] "V"  HVESP01
 SG_ HVESP01_cellVoltage_94 m23 : 22|14@1+ (0.001,0) [0|16.383] "V"  HVESP01
 SG_ HVESP01_cellVoltage_95 m23 : 36|14@1+ (0.001,0) [0|16.383] "V"  HVESP01
 SG_ HVESP01_cellVoltage_96 m23 : 50|14@1+ (0.001,0) [0|16.383] "V"  HVESP01
 SG_ HVESP01_cellVoltage_97 m24 : 8|14@1+ (0.001,0) [0|16.383] "V"  HVESP01
 SG_ HVESP01_cellVoltage_98 m24 : 22|14@1+ (0.001,0) [0|16.383] "V"  HVESP01
 SG_ HVESP01_cellVoltage_99 m24 : 36|14@1+ (0.001,0) [0|16.383] "V"  HVESP01
 SG_ HVESP01_cellVoltage_100 m24 : 50|14@1+ (0.001,0) [0|16.383] "V"  HVESP01
 SG_ HVESP01_cellVoltage_101 m25 : 8|14@1+ (0.001,0) [0|16.383] "V"  HVESP01
 SG_ HVESP01_cellVoltage_102 m25 : 22|14@1+ (0.001,0) [0|16.383] "V"  HVESP01
 SG_ HVESP01_cellVoltage_103 m25 : 36|14@1+ (0.001,0) [0|16.383] "V"  HVESP01
 SG_ HVESP01_cellVoltage_104 m25 : 50|14@1+ (0.001,0) [0|16.383] "V"  HVESP01
 SG_ HVESP01_cellVoltage_105 m26 : 8|14@1+ (0.001,0) [0|16.383] "V"  HVESP01
 SG_ HVESP01_cellVoltage_106 m26 : 22|14@1+ (0.001,0) [0|16.383] "V"  HVESP01
 SG_ HVESP01_cellVoltage_107 m26 : 36|14@1+ (0.001,0) [0|16.383] "V"  HVESP01
 SG_ HVESP01_cellVoltage_108 m26 : 50|14@1+ (0.001,0) [0|16.383] "V"  HVESP01
 SG_ HVESP01_cellVoltage_109 m27 : 8|14@1+ (0.001,0) [0|16.383] "V"  HVESP01
 SG_ HVESP01_cellVoltage_110 m27 : 22|14@1+ (0.001,0) [0|16.383] "V"  HVESP01
 SG_ HVESP01_cellVoltage_111 m27 : 36|14@1+ (0.001,0) [0|16.383] "V"  HVESP01
 SG_ HVESP01_cellVoltage_112 m27 : 50|14@1+ (0.001,0) [0|16.383] "V"  HVESP01
 SG_ HVESP01_cellVoltage_113 m28 : 8|14@1+ (0.001,0) [0|16.383] "V"  HVESP01
 SG_ HVESP01_cellVoltage_114 m28 : 22|14@1+ (0.001,0) [0|16.383] "V"  HVESP01
 SG_ HVESP01_cellVoltage_115 m28 : 36|14@1+ (0.001,0) [0|16.383] "V"  HVESP01
 SG_ HVESP01_cellVoltage_116 m28 : 50|14@1+ (0.001,0) [0|16.383] "V"  HVESP01
 SG_ HVESP01_cellVoltage_117 m29 : 8|14@1+ (0.001,0) [0|16.383] "V"  HVESP01
 SG_ HVESP01_cellVoltage_118 m29 : 22|14@1+ (0.001,0) [0|16.383] "V"  HVESP01
 SG_ HVESP01_cellVoltage_119 m29 : 36|14@1+ (0.001,0) [0|16.383] "V"  HVESP01
 SG_ HVESP01_cellVoltage_120 m29 : 50|14@1+ (0.001,0) [0|16.383] "V"  HVESP01
 SG_ HVESP01_cellVoltage_121 m30 : 8|14@1+ (0.001,0) [0|16.383] "V"  HVESP01
 SG_ HVESP01_cellVoltage_122 m30 : 22|14@1+ (0.001,0) [0|16.383] "V"  HVESP01
 SG_ HVESP01_cellVoltage_123 m30 : 36|14@1+ (0.001,0) [0|16.383] "V"  HVESP01
 SG_ HVESP01_cellVoltage_124 m30 : 50|14@1+ (0.001,0) [0|16.383] "V"  HVESP01
 SG_ HVESP01_cellVoltage_125 m31 : 8|14@1+ (0.001,0) [0|16.383] "V"  HVESP01
 SG_ HVESP01_cellVoltage_126 m31 : 22|14@1+ (0.001,0) [0|16.383] "V"  HVESP01
 SG_ HVESP01_cellVoltage_127 m31 : 36|14@1+ (0.001,0) [0|16.383] "V"  HVESP01
 SG_ HVESP01_cellVoltage_128 m31 : 50|14@1+ (0.001,0) [0|16.383] "V"  HVESP01
 SG_ HVESP01_cellVoltage_129 m32 : 8|14@1+ (0.001,0) [0|16.383] "V"  HVESP01
 SG_ HVESP01_cellVoltage_130 m32 : 22|14@1+ (0.001,0) [0|16.383] "V"  HVESP01
 SG_ HVESP01_cellVoltage_131 m32 : 36|14@1+ (0.001,0) [0|16.383] "V"  HVESP01
 SG_ HVESP01_cellVoltage_132 m32 : 50|14@1+ (0.001,0) [0|16.383] "V"  HVESP01
 SG_ HVESP01_cellVoltage_133 m33 : 8|14@1+ (0.001,0) [0|16.383] "V"  HVESP01
 SG_ HVESP01_cellVoltage_134 m33 : 22|14@1+ (0.001,0) [0|16.383] "V"  HVESP01
 SG_ HVESP01_cellVoltage_135 m33 : 36|14@1+ (0.001,0) [0|16.383] "V"  HVESP01
 SG_ HVESP01_cellVoltage_136 m33 : 50|14@1+ (0.001,0) [0|16.383] "V"  HVESP01
 SG_ HVESP01_cellVoltage_137 m34 : 8|14@1+ (0.001,0) [0|16.383] "V"  HVESP01
 SG_ HVESP01_cellVoltage_138 m34 : 22|14@1+ (0.001,0) [0|16.383] "V"  HVESP01
 SG_ HVESP01_cellVoltage_139 m34 : 36|14@1+ (0.001,0) [0|16.383] "V"  HVESP01
 SG_ HVESP01_cellVoltage_140 m34 : 50|14@1+ (0.001,0) [0|16.383] "V"  HVESP01
 SG_ HVESP01_cellVoltage_141 m35 : 8|14@1+ (0.001,0) [0|16.383] "V"  HVESP01
 SG_ HVESP01_cellVoltage_142 m35 : 22|14@1+ (0.001,0) [0|16.383] "V"  HVESP01
 SG_ HVESP01_cellVoltage_143 m35 : 36|14@1+ (0.001,0) [0|16.383] "V"  HVESP01
 SG_ HVESP01_cellVoltage_144 m35 : 50|14@1+ (0.001,0) [0|16.383] "V"  HVESP01
 SG_ HVESP01_cellVoltage_145 m36 : 8|14@1+ (0.001,0) [0|16.383] "V"  HVESP01
 SG_ HVESP01_cellVoltage_146 m36 : 22|14@1+ (0.001,0) [0|16.383] "V"  HVESP01
 SG_ HVESP01_cellVoltage_147 m36 : 36|14@1+ (0.001,0) [0|16.383] "V"  HVESP01
 SG_ HVESP01_cellVoltage_148 m36 : 50|14@1+ (0.001,0) [0|16.383] "V"  HVESP01
 SG_ HVESP01_cellVoltage_149 m37 : 8|14@1+ (0.001,0) [0|16.383] "V"  HVESP01
 SG_ HVESP01_cellVoltage_150 m37 : 22|14@1+ (0.001,0) [0|16.383] "V"  HVESP01
 SG_ HVESP01_cellVoltage_151 m37 : 36|14@1+ (0.001,0) [0|16.383] "V"  HVESP01
 SG_ HVESP01_cellVoltage_152 m37 : 50|14@1+ (0.001,0) [0|16.383] "V"  HVESP01
 SG_ HVESP01_cellVoltage_153 m38 : 8|14@1+ (0.001,0) [0|16.383] "V"  HVESP01
 SG_ HVESP01_cellVoltage_154 m38 : 22|14@1+ (0.001,0) [0|16.383] "V"  HVESP01
 SG_ HVESP01_cellVoltage_155 m38 : 36|14@1+ (0.001,0) [0|16.383] "V"  HVESP01
 SG_ HVESP01_cellVoltage_156 m38 : 50|14@1+ (0.001,0) [0|16.383] "V"  HVESP01
 SG_ HVESP01_cellVoltage_157 m39 : 8|14@1+ (0.001,0) [0|16.383] "V"  HVESP01
 SG_ HVESP01_cellVoltage_158 m39 : 22|14@1+ (0.001,0) [0|16.383] "V"  HVESP01
 SG_ HVESP01_cellVoltage_159 m39 : 36|14@1+ (0.001,0) [0|16.383] "V"  HVESP01
 SG_ HVESP01_cellVoltage_160 m39 : 50|14@1+ (0.001,0) [0|16.383] "V"  HVESP01
 SG_ HVESP01_cellVoltage_161 m40 : 8|14@1+ (0.001,0) [0|16.383] "V"  HVESP01
 SG_ HVESP01_cellVoltage_162 m40 : 22|14@1+ (0.001,0) [0|16.383] "V"  HVESP01
 SG_ HVESP01_cellVoltage_163 m40 : 36|14@1+ (0.001,0) [0|16.383] "V"  HVESP01
 SG_ HVESP01_cellVoltage_164 m40 : 50|14@1+ (0.001,0) [0|16.383] "V"  HVESP01
 SG_ HVESP01_cellVoltage_165 m41 : 8|14@1+ (0.001,0) [0|16.383] "V"  HVESP01
 SG_ HVESP01_cellVoltage_166 m41 : 22|14@1+ (0.001,0) [0|16.383] "V"  HVESP01
 SG_ HVESP01_cellVoltage_167 m41 : 36|14@1+ (0.001,0) [0|16.383] "V"  HVESP01
 SG_ HVESP01_cellVoltage_168 m41 : 50|14@1+ (0.001,0) [0|16.383] "V"  HVESP01
 SG_ HVESP01_cellVoltage_169 m42 : 8|14@1+ (0.001,0) [0|16.383] "V"  HVESP01
 SG_ HVESP01_cellVoltage_170 m42 : 22|14@1+ (0.001,0) [0|16.383] "V"  HVESP01
 SG_ HVESP01_cellVoltage_171 m42 : 36|14@1+ (0.001,0) [0|16.383] "V"  HVESP01
 SG_ HVESP01_cellVoltage_172 m42 : 50|14@1+ (0.001,0) [0|16.383] "V"  HVESP01
 SG_ HVESP01_cellVoltage_173 m43 : 8|14@1+ (0.001,0) [0|16.383] "V"  HVESP01
 SG_ HVESP01_cellVoltage_174 m43 : 22|14@1+ (0.001,0) [0|16.383] "V"  HVESP01
 SG_ HVESP01_cellVoltage_175 m43 : 36|14@1+ (0.001,0) [0|16.383] "V"  HVESP01
 SG_ HVESP01_cellVoltage_176 m43 : 50|14@1+ (0.001,0) [0|16.383] "V"  HVESP01
 SG_ HVESP01_cellVoltage_177 m44 : 8|14@1+ (0.001,0) [0|16.383] "V"  HVESP01
 SG_ HVESP01_cellVoltage_178 m44 : 22|14@1+ (0.001,0) [0|16.383] "V"  HVESP01
 SG_ HVESP01_cellVoltage_179 m44 : 36|14@1+ (0.001,0) [0|16.383] "V"  HVESP01
 SG_ HVESP01_cellVoltage_180 m44 : 50|14@1+ (0.001,0) [0|16.383] "V"  HVESP01
 SG_ multiplexorcv M : 0|8@1+ (1,0) [0|255] ""  HVESP01

BO_ 2499741284 HVESP01_brickSOHC: 8 HVESP01
 SG_ HVESP01_brickSOHC_01 m0 : 8|14@1+ (1,0) [0|100] "%"  HVESP01
 SG_ HVESP01_brickSOHC_02 m0 : 22|14@1+ (1,0) [0|100] "%"  HVESP01
 SG_ HVESP01_brickSOHC_03 m0 : 36|14@1+ (1,0) [0|100] "%"  HVESP01
 SG_ HVESP01_brickSOHC_04 m0 : 50|14@1+ (1,0) [0|100] "%"  HVESP01
 SG_ HVESP01_brickSOHC_05 m1 : 8|14@1+ (1,0) [0|100] "%"  HVESP01
 SG_ HVESP01_brickSOHC_06 m1 : 22|14@1+ (1,0) [0|100] "%"  HVESP01
 SG_ HVESP01_brickSOHC_07 m1 : 36|14@1+ (1,0) [0|100] "%"  HVESP01
 SG_ HVESP01_brickSOHC_08 m1 : 50|14@1+ (1,0) [0|100] "%"  HVESP01
 SG_ HVESP01_brickSOHC_09 m2 : 8|14@1+ (1,0) [0|100] "%"  HVESP01
 SG_ HVESP01_brickSOHC_10 m2 : 22|14@1+ (1,0) [0|100] "%"  HVESP01
 SG_ HVESP01_brickSOHC_11 m2 : 36|14@1+ (1,0) [0|100] "%"  HVESP01
 SG_ HVESP01_brickSOHC_12 m2 : 50|14@1+ (1,0) [0|100] "%"  HVESP01
 SG_ HVESP01_brickSOHC_13 m3 : 8|14@1+ (1,0) [0|100] "%"  HVESP01
 SG_ HVESP01_brickSOHC_14 m3 : 22|14@1+ (1,0) [0|100] "%"  HVESP01
 SG_ HVESP01_brickSOHC_15 m3 : 36|14@1+ (1,0) [0|100] "%"  HVESP01
 SG_ HVESP01_brickSOHC_16 m3 : 50|14@1+ (1,0) [0|100] "%"  HVESP01
 SG_ HVESP01_brickSOHC_17 m4 : 8|14@1+ (1,0) [0|100] "%"  HVESP01
 SG_ HVESP01_brickSOHC_18 m4 : 22|14@1+ (1,0) [0|100] "%"  HVESP01
 SG_ HVESP01_brickSOHC_19 m4 : 36|14@1+ (1,0) [0|100] "%"  HVESP01
 SG_ HVESP01_brickSOHC_20 m4 : 50|14@1+ (1,0) [0|100] "%"  HVESP01
 SG_ HVESP01_brickSOHC_21 m5 : 8|14@1+ (1,0) [0|100] "%"  HVESP01
 SG_ HVESP01_brickSOHC_22 m5 : 22|14@1+ (1,0) [0|100] "%"  HVESP01
 SG_ HVESP01_brickSOHC_23 m5 : 36|14@1+ (1,0) [0|100] "%"  HVESP01
 SG_ HVESP01_brickSOHC_24 m5 : 50|14@1+ (1,0) [0|100] "%"  HVESP01
 SG_ HVESP01_brickSOHC_25 m6 : 8|14@1+ (1,0) [0|100] "%"  HVESP01
 SG_ HVESP01_brickSOHC_26 m6 : 22|14@1+ (1,0) [0|100] "%"  HVESP01
 SG_ HVESP01_brickSOHC_27 m6 : 36|14@1+ (1,0) [0|100] "%"  HVESP01
 SG_ HVESP01_brickSOHC_28 m6 : 50|14@1+ (1,0) [0|100] "%"  HVESP01
 SG_ HVESP01_brickSOHC_29 m7 : 8|14@1+ (1,0) [0|100] "%"  HVESP01
 SG_ HVESP01_brickSOHC_30 m7 : 22|14@1+ (1,0) [0|100] "%"  HVESP01
 SG_ HVESP01_brickSOHC_31 m7 : 36|14@1+ (1,0) [0|100] "%"  HVESP01
 SG_ HVESP01_brickSOHC_32 m7 : 50|14@1+ (1,0) [0|100] "%"  HVESP01
 SG_ HVESP01_brickSOHC_33 m8 : 8|14@1+ (1,0) [0|100] "%"  HVESP01
 SG_ HVESP01_brickSOHC_34 m8 : 22|14@1+ (1,0) [0|100] "%"  HVESP01
 SG_ HVESP01_brickSOHC_35 m8 : 36|14@1+ (1,0) [0|100] "%"  HVESP01
 SG_ HVESP01_brickSOHC_36 m8 : 50|14@1+ (1,0) [0|100] "%"  HVESP01
 SG_ HVESP01_brickSOHC_37 m9 : 8|14@1+ (1,0) [0|100] "%"  HVESP01
 SG_ HVESP01_brickSOHC_38 m9 : 22|14@1+ (1,0) [0|100] "%"  HVESP01
 SG_ HVESP01_brickSOHC_39 m9 : 36|14@1+ (1,0) [0|100] "%"  HVESP01
 SG_ HVESP01_brickSOHC_40 m9 : 50|14@1+ (1,0) [0|100] "%"  HVESP01
 SG_ HVESP01_brickSOHC_41 m10 : 8|14@1+ (1,0) [0|100] "%"  HVESP01
 SG_ HVESP01_brickSOHC_42 m10 : 22|14@1+ (1,0) [0|100] "%"  HVESP01
 SG_ HVESP01_brickSOHC_43 m10 : 36|14@1+ (1,0) [0|100] "%"  HVESP01
 SG_ HVESP01_brickSOHC_44 m10 : 50|14@1+ (1,0) [0|100] "%"  HVESP01
 SG_ HVESP01_brickSOHC_45 m11 : 8|14@1+ (1,0) [0|100] "%"  HVESP01
 SG_ HVESP01_brickSOHC_46 m11 : 22|14@1+ (1,0) [0|100] "%"  HVESP01
 SG_ HVESP01_brickSOHC_47 m11 : 36|14@1+ (1,0) [0|100] "%"  HVESP01
 SG_ HVESP01_brickSOHC_48 m11 : 50|14@1+ (1,0) [0|100] "%"  HVESP01
 SG_ HVESP01_brickSOHC_49 m12 : 8|14@1+ (1,0) [0|100] "%"  HVESP01
 SG_ HVESP01_brickSOHC_50 m12 : 22|14@1+ (1,0) [0|100] "%"  HVESP01
 SG_ HVESP01_brickSOHC_51 m12 : 36|14@1+ (1,0) [0|100] "%"  HVESP01
 SG_ HVESP01_brickSOHC_52 m12 : 50|14@1+ (1,0) [0|100] "%"  HVESP01
 SG_ HVESP01_brickSOHC_53 m13 : 8|14@1+ (1,0) [0|100] "%"  HVESP01
 SG_ HVESP01_brickSOHC_54 m13 : 22|14@1+ (1,0) [0|100] "%"  HVESP01
 SG_ HVESP01_brickSOHC_55 m13 : 36|14@1+ (1,0) [0|100] "%"  HVESP01
 SG_ HVESP01_brickSOHC_56 m13 : 50|14@1+ (1,0) [0|100] "%"  HVESP01
 SG_ HVESP01_brickSOHC_57 m14 : 8|14@1+ (1,0) [0|100] "%"  HVESP01
 SG_ HVESP01_brickSOHC_58 m14 : 22|14@1+ (1,0) [0|100] "%"  HVESP01
 SG_ HVESP01_brickSOHC_59 m14 : 36|14@1+ (1,0) [0|100] "%"  HVESP01
 SG_ HVESP01_brickSOHC_60 m14 : 50|14@1+ (1,0) [0|100] "%"  HVESP01
 SG_ HVESP01_brickSOHC_61 m15 : 8|14@1+ (1,0) [0|100] "%"  HVESP01
 SG_ HVESP01_brickSOHC_62 m15 : 22|14@1+ (1,0) [0|100] "%"  HVESP01
 SG_ HVESP01_brickSOHC_63 m15 : 36|14@1+ (1,0) [0|100] "%"  HVESP01
 SG_ HVESP01_brickSOHC_64 m15 : 50|14@1+ (1,0) [0|100] "%"  HVESP01
 SG_ HVESP01_brickSOHC_65 m16 : 8|14@1+ (1,0) [0|100] "%"  HVESP01
 SG_ HVESP01_brickSOHC_66 m16 : 22|14@1+ (1,0) [0|100] "%"  HVESP01
 SG_ HVESP01_brickSOHC_67 m16 : 36|14@1+ (1,0) [0|100] "%"  HVESP01
 SG_ HVESP01_brickSOHC_68 m16 : 50|14@1+ (1,0) [0|100] "%"  HVESP01
 SG_ HVESP01_brickSOHC_69 m17 : 8|14@1+ (1,0) [0|100] "%"  HVESP01
 SG_ HVESP01_brickSOHC_70 m17 : 22|14@1+ (1,0) [0|100] "%"  HVESP01
 SG_ HVESP01_brickSOHC_71 m17 : 36|14@1+ (1,0) [0|100] "%"  HVESP01
 SG_ HVESP01_brickSOHC_72 m17 : 50|14@1+ (1,0) [0|100] "%"  HVESP01
 SG_ HVESP01_brickSOHC_73 m18 : 8|14@1+ (1,0) [0|100] "%"  HVESP01
 SG_ HVESP01_brickSOHC_74 m18 : 22|14@1+ (1,0) [0|100] "%"  HVESP01
 SG_ HVESP01_brickSOHC_75 m18 : 36|14@1+ (1,0) [0|100] "%"  HVESP01
 SG_ HVESP01_brickSOHC_76 m18 : 50|14@1+ (1,0) [0|100] "%"  HVESP01
 SG_ HVESP01_brickSOHC_77 m19 : 8|14@1+ (1,0) [0|100] "%"  HVESP01
 SG_ HVESP01_brickSOHC_78 m19 : 22|14@1+ (1,0) [0|100] "%"  HVESP01
 SG_ HVESP01_brickSOHC_79 m19 : 36|14@1+ (1,0) [0|100] "%"  HVESP01
 SG_ HVESP01_brickSOHC_80 m19 : 50|14@1+ (1,0) [0|100] "%"  HVESP01
 SG_ HVESP01_brickSOHC_81 m20 : 8|14@1+ (1,0) [0|100] "%"  HVESP01
 SG_ HVESP01_brickSOHC_82 m20 : 22|14@1+ (1,0) [0|100] "%"  HVESP01
 SG_ HVESP01_brickSOHC_83 m20 : 36|14@1+ (1,0) [0|100] "%"  HVESP01
 SG_ HVESP01_brickSOHC_84 m20 : 50|14@1+ (1,0) [0|100] "%"  HVESP01
 SG_ HVESP01_brickSOHC_85 m21 : 8|14@1+ (1,0) [0|100] "%"  HVESP01
 SG_ HVESP01_brickSOHC_86 m21 : 22|14@1+ (1,0) [0|100] "%"  HVESP01
 SG_ HVESP01_brickSOHC_87 m21 : 36|14@1+ (1,0) [0|100] "%"  HVESP01
 SG_ HVESP01_brickSOHC_88 m21 : 50|14@1+ (1,0) [0|100] "%"  HVESP01
 SG_ HVESP01_brickSOHC_89 m22 : 8|14@1+ (1,0) [0|100] "%"  HVESP01
 SG_ HVESP01_brickSOHC_90 m22 : 22|14@1+ (1,0) [0|100] "%"  HVESP01
 SG_ HVESP01_brickSOHC_91 m22 : 36|14@1+ (1,0) [0|100] "%"  HVESP01
 SG_ HVESP01_brickSOHC_92 m22 : 50|14@1+ (1,0) [0|100] "%"  HVESP01
 SG_ HVESP01_brickSOHC_93 m23 : 8|14@1+ (1,0) [0|100] "%"  HVESP01
 SG_ HVESP01_brickSOHC_94 m23 : 22|14@1+ (1,0) [0|100] "%"  HVESP01
 SG_ HVESP01_brickSOHC_95 m23 : 36|14@1+ (1,0) [0|100] "%"  HVESP01
 SG_ HVESP01_brickSOHC_96 m23 : 50|14@1+ (1,0) [0|100] "%"  HVESP01
 SG_ HVESP01_brickSOHC_97 m24 : 8|14@1+ (1,0) [0|100] "%"  HVESP01
 SG_ HVESP01_brickSOHC_98 m24 : 22|14@1+ (1,0) [0|100] "%"  HVESP01
 SG_ HVESP01_brickSOHC_99 m24 : 36|14@1+ (1,0) [0|100] "%"  HVESP01
 SG_ HVESP01_brickSOHC_100 m24 : 50|14@1+ (1,0) [0|100] "%"  HVESP01
 SG_ HVESP01_brickSOHC_101 m25 : 8|14@1+ (1,0) [0|100] "%"  HVESP01
 SG_ HVESP01_brickSOHC_102 m25 : 22|14@1+ (1,0) [0|100] "%"  HVESP01
 SG_ HVESP01_brickSOHC_103 m25 : 36|14@1+ (1,0) [0|100] "%"  HVESP01
 SG_ HVESP01_brickSOHC_104 m25 : 50|14@1+ (1,0) [0|100] "%"  HVESP01
 SG_ HVESP01_brickSOHC_105 m26 : 8|14@1+ (1,0) [0|100] "%"  HVESP01
 SG_ HVESP01_brickSOHC_106 m26 : 22|14@1+ (1,0) [0|100] "%"  HVESP01
 SG_ HVESP01_brickSOHC_107 m26 : 36|14@1+ (1,0) [0|100] "%"  HVESP01
 SG_ HVESP01_brickSOHC_108 m26 : 50|14@1+ (1,0) [0|100] "%"  HVESP01
 SG_ HVESP01_brickSOHC_109 m27 : 8|14@1+ (1,0) [0|100] "%"  HVESP01
 SG_ HVESP01_brickSOHC_110 m27 : 22|14@1+ (1,0) [0|100] "%"  HVESP01
 SG_ HVESP01_brickSOHC_111 m27 : 36|14@1+ (1,0) [0|100] "%"  HVESP01
 SG_ HVESP01_brickSOHC_112 m27 : 50|14@1+ (1,0) [0|100] "%"  HVESP01
 SG_ HVESP01_brickSOHC_113 m28 : 8|14@1+ (1,0) [0|100] "%"  HVESP01
 SG_ HVESP01_brickSOHC_114 m28 : 22|14@1+ (1,0) [0|100] "%"  HVESP01
 SG_ HVESP01_brickSOHC_115 m28 : 36|14@1+ (1,0) [0|100] "%"  HVESP01
 SG_ HVESP01_brickSOHC_116 m28 : 50|14@1+ (1,0) [0|100] "%"  HVESP01
 SG_ HVESP01_brickSOHC_117 m29 : 8|14@1+ (1,0) [0|100] "%"  HVESP01
 SG_ HVESP01_brickSOHC_118 m29 : 22|14@1+ (1,0) [0|100] "%"  HVESP01
 SG_ HVESP01_brickSOHC_119 m29 : 36|14@1+ (1,0) [0|100] "%"  HVESP01
 SG_ HVESP01_brickSOHC_120 m29 : 50|14@1+ (1,0) [0|100] "%"  HVESP01
 SG_ HVESP01_brickSOHC_121 m30 : 8|14@1+ (1,0) [0|100] "%"  HVESP01
 SG_ HVESP01_brickSOHC_122 m30 : 22|14@1+ (1,0) [0|100] "%"  HVESP01
 SG_ HVESP01_brickSOHC_123 m30 : 36|14@1+ (1,0) [0|100] "%"  HVESP01
 SG_ HVESP01_brickSOHC_124 m30 : 50|14@1+ (1,0) [0|100] "%"  HVESP01
 SG_ HVESP01_brickSOHC_125 m31 : 8|14@1+ (1,0) [0|100] "%"  HVESP01
 SG_ HVESP01_brickSOHC_126 m31 : 22|14@1+ (1,0) [0|100] "%"  HVESP01
 SG_ HVESP01_brickSOHC_127 m31 : 36|14@1+ (1,0) [0|100] "%"  HVESP01
 SG_ HVESP01_brickSOHC_128 m31 : 50|14@1+ (1,0) [0|100] "%"  HVESP01
 SG_ HVESP01_brickSOHC_129 m32 : 8|14@1+ (1,0) [0|100] "%"  HVESP01
 SG_ HVESP01_brickSOHC_130 m32 : 22|14@1+ (1,0) [0|100] "%"  HVESP01
 SG_ HVESP01_brickSOHC_131 m32 : 36|14@1+ (1,0) [0|100] "%"  HVESP01
 SG_ HVESP01_brickSOHC_132 m32 : 50|14@1+ (1,0) [0|100] "%"  HVESP01
 SG_ HVESP01_brickSOHC_133 m33 : 8|14@1+ (1,0) [0|100] "%"  HVESP01
 SG_ HVESP01_brickSOHC_134 m33 : 22|14@1+ (1,0) [0|100] "%"  HVESP01
 SG_ HVESP01_brickSOHC_135 m33 : 36|14@1+ (1,0) [0|100] "%"  HVESP01
 SG_ HVESP01_brickSOHC_136 m33 : 50|14@1+ (1,0) [0|100] "%"  HVESP01
 SG_ HVESP01_brickSOHC_137 m34 : 8|14@1+ (1,0) [0|100] "%"  HVESP01
 SG_ HVESP01_brickSOHC_138 m34 : 22|14@1+ (1,0) [0|100] "%"  HVESP01
 SG_ HVESP01_brickSOHC_139 m34 : 36|14@1+ (1,0) [0|100] "%"  HVESP01
 SG_ HVESP01_brickSOHC_140 m34 : 50|14@1+ (1,0) [0|100] "%"  HVESP01
 SG_ HVESP01_brickSOHC_141 m35 : 8|14@1+ (1,0) [0|100] "%"  HVESP01
 SG_ HVESP01_brickSOHC_142 m35 : 22|14@1+ (1,0) [0|100] "%"  HVESP01
 SG_ HVESP01_brickSOHC_143 m35 : 36|14@1+ (1,0) [0|100] "%"  HVESP01
 SG_ HVESP01_brickSOHC_144 m35 : 50|14@1+ (1,0) [0|100] "%"  HVESP01
 SG_ HVESP01_brickSOHC_145 m36 : 8|14@1+ (1,0) [0|100] "%"  HVESP01
 SG_ HVESP01_brickSOHC_146 m36 : 22|14@1+ (1,0) [0|100] "%"  HVESP01
 SG_ HVESP01_brickSOHC_147 m36 : 36|14@1+ (1,0) [0|100] "%"  HVESP01
 SG_ HVESP01_brickSOHC_148 m36 : 50|14@1+ (1,0) [0|100] "%"  HVESP01
 SG_ HVESP01_brickSOHC_149 m37 : 8|14@1+ (1,0) [0|100] "%"  HVESP01
 SG_ HVESP01_brickSOHC_150 m37 : 22|14@1+ (1,0) [0|100] "%"  HVESP01
 SG_ HVESP01_brickSOHC_151 m37 : 36|14@1+ (1,0) [0|100] "%"  HVESP01
 SG_ HVESP01_brickSOHC_152 m37 : 50|14@1+ (1,0) [0|100] "%"  HVESP01
 SG_ HVESP01_brickSOHC_153 m38 : 8|14@1+ (1,0) [0|100] "%"  HVESP01
 SG_ HVESP01_brickSOHC_154 m38 : 22|14@1+ (1,0) [0|100] "%"  HVESP01
 SG_ HVESP01_brickSOHC_155 m38 : 36|14@1+ (1,0) [0|100] "%"  HVESP01
 SG_ HVESP01_brickSOHC_156 m38 : 50|14@1+ (1,0) [0|100] "%"  HVESP01
 SG_ HVESP01_brickSOHC_157 m39 : 8|14@1+ (1,0) [0|100] "%"  HVESP01
 SG_ HVESP01_brickSOHC_158 m39 : 22|14@1+ (1,0) [0|100] "%"  HVESP01
 SG_ HVESP01_brickSOHC_159 m39 : 36|14@1+ (1,0) [0|100] "%"  HVESP01
 SG_ HVESP01_brickSOHC_160 m39 : 50|14@1+ (1,0) [0|100] "%"  HVESP01
 SG_ HVESP01_brickSOHC_161 m40 : 8|14@1+ (1,0) [0|100] "%"  HVESP01
 SG_ HVESP01_brickSOHC_162 m40 : 22|14@1+ (1,0) [0|100] "%"  HVESP01
 SG_ HVESP01_brickSOHC_163 m40 : 36|14@1+ (1,0) [0|100] "%"  HVESP01
 SG_ HVESP01_brickSOHC_164 m40 : 50|14@1+ (1,0) [0|100] "%"  HVESP01
 SG_ HVESP01_brickSOHC_165 m41 : 8|14@1+ (1,0) [0|100] "%"  HVESP01
 SG_ HVESP01_brickSOHC_166 m41 : 22|14@1+ (1,0) [0|100] "%"  HVESP01
 SG_ HVESP01_brickSOHC_167 m41 : 36|14@1+ (1,0) [0|100] "%"  HVESP01
 SG_ HVESP01_brickSOHC_168 m41 : 50|14@1+ (1,0) [0|100] "%"  HVESP01
 SG_ HVESP01_brickSOHC_169 m42 : 8|14@1+ (1,0) [0|100] "%"  HVESP01
 SG_ HVESP01_brickSOHC_170 m42 : 22|14@1+ (1,0) [0|100] "%"  HVESP01
 SG_ HVESP01_brickSOHC_171 m42 : 36|14@1+ (1,0) [0|100] "%"  HVESP01
 SG_ HVESP01_brickSOHC_172 m42 : 50|14@1+ (1,0) [0|100] "%"  HVESP01
 SG_ HVESP01_brickSOHC_173 m43 : 8|14@1+ (1,0) [0|100] "%"  HVESP01
 SG_ HVESP01_brickSOHC_174 m43 : 22|14@1+ (1,0) [0|100] "%"  HVESP01
 SG_ HVESP01_brickSOHC_175 m43 : 36|14@1+ (1,0) [0|100] "%"  HVESP01
 SG_ HVESP01_brickSOHC_176 m43 : 50|14@1+ (1,0) [0|100] "%"  HVESP01
 SG_ HVESP01_brickSOHC_177 m44 : 8|14@1+ (1,0) [0|100] "%"  HVESP01
 SG_ HVESP01_brickSOHC_178 m44 : 22|14@1+ (1,0) [0|100] "%"  HVESP01
 SG_ HVESP01_brickSOHC_179 m44 : 36|14@1+ (1,0) [0|100] "%"  HVESP01
 SG_ HVESP01_brickSOHC_180 m44 : 50|14@1+ (1,0) [0|100] "%"  HVESP01
 SG_ multiplexorsohc M : 0|8@1+ (1,0) [0|255] ""  HVESP01

BO_ 2499741028 HVESP01_brickSOC: 8 HVESP01
 SG_ HVESP01_brickSOC_01 m0 : 8|14@1+ (1,0) [0|100] "%"  HVESP01
 SG_ HVESP01_brickSOC_02 m0 : 22|14@1+ (1,0) [0|100] "%"  HVESP01
 SG_ HVESP01_brickSOC_03 m0 : 36|14@1+ (1,0) [0|100] "%"  HVESP01
 SG_ HVESP01_brickSOC_04 m0 : 50|14@1+ (1,0) [0|100] "%"  HVESP01
 SG_ HVESP01_brickSOC_05 m1 : 8|14@1+ (1,0) [0|100] "%"  HVESP01
 SG_ HVESP01_brickSOC_06 m1 : 22|14@1+ (1,0) [0|100] "%"  HVESP01
 SG_ HVESP01_brickSOC_07 m1 : 36|14@1+ (1,0) [0|100] "%"  HVESP01
 SG_ HVESP01_brickSOC_08 m1 : 50|14@1+ (1,0) [0|100] "%"  HVESP01
 SG_ HVESP01_brickSOC_09 m2 : 8|14@1+ (1,0) [0|100] "%"  HVESP01
 SG_ HVESP01_brickSOC_10 m2 : 22|14@1+ (1,0) [0|100] "%"  HVESP01
 SG_ HVESP01_brickSOC_11 m2 : 36|14@1+ (1,0) [0|100] "%"  HVESP01
 SG_ HVESP01_brickSOC_12 m2 : 50|14@1+ (1,0) [0|100] "%"  HVESP01
 SG_ HVESP01_brickSOC_13 m3 : 8|14@1+ (1,0) [0|100] "%"  HVESP01
 SG_ HVESP01_brickSOC_14 m3 : 22|14@1+ (1,0) [0|100] "%"  HVESP01
 SG_ HVESP01_brickSOC_15 m3 : 36|14@1+ (1,0) [0|100] "%"  HVESP01
 SG_ HVESP01_brickSOC_16 m3 : 50|14@1+ (1,0) [0|100] "%"  HVESP01
 SG_ HVESP01_brickSOC_17 m4 : 8|14@1+ (1,0) [0|100] "%"  HVESP01
 SG_ HVESP01_brickSOC_18 m4 : 22|14@1+ (1,0) [0|100] "%"  HVESP01
 SG_ HVESP01_brickSOC_19 m4 : 36|14@1+ (1,0) [0|100] "%"  HVESP01
 SG_ HVESP01_brickSOC_20 m4 : 50|14@1+ (1,0) [0|100] "%"  HVESP01
 SG_ HVESP01_brickSOC_21 m5 : 8|14@1+ (1,0) [0|100] "%"  HVESP01
 SG_ HVESP01_brickSOC_22 m5 : 22|14@1+ (1,0) [0|100] "%"  HVESP01
 SG_ HVESP01_brickSOC_23 m5 : 36|14@1+ (1,0) [0|100] "%"  HVESP01
 SG_ HVESP01_brickSOC_24 m5 : 50|14@1+ (1,0) [0|100] "%"  HVESP01
 SG_ HVESP01_brickSOC_25 m6 : 8|14@1+ (1,0) [0|100] "%"  HVESP01
 SG_ HVESP01_brickSOC_26 m6 : 22|14@1+ (1,0) [0|100] "%"  HVESP01
 SG_ HVESP01_brickSOC_27 m6 : 36|14@1+ (1,0) [0|100] "%"  HVESP01
 SG_ HVESP01_brickSOC_28 m6 : 50|14@1+ (1,0) [0|100] "%"  HVESP01
 SG_ HVESP01_brickSOC_29 m7 : 8|14@1+ (1,0) [0|100] "%"  HVESP01
 SG_ HVESP01_brickSOC_30 m7 : 22|14@1+ (1,0) [0|100] "%"  HVESP01
 SG_ HVESP01_brickSOC_31 m7 : 36|14@1+ (1,0) [0|100] "%"  HVESP01
 SG_ HVESP01_brickSOC_32 m7 : 50|14@1+ (1,0) [0|100] "%"  HVESP01
 SG_ HVESP01_brickSOC_33 m8 : 8|14@1+ (1,0) [0|100] "%"  HVESP01
 SG_ HVESP01_brickSOC_34 m8 : 22|14@1+ (1,0) [0|100] "%"  HVESP01
 SG_ HVESP01_brickSOC_35 m8 : 36|14@1+ (1,0) [0|100] "%"  HVESP01
 SG_ HVESP01_brickSOC_36 m8 : 50|14@1+ (1,0) [0|100] "%"  HVESP01
 SG_ HVESP01_brickSOC_37 m9 : 8|14@1+ (1,0) [0|100] "%"  HVESP01
 SG_ HVESP01_brickSOC_38 m9 : 22|14@1+ (1,0) [0|100] "%"  HVESP01
 SG_ HVESP01_brickSOC_39 m9 : 36|14@1+ (1,0) [0|100] "%"  HVESP01
 SG_ HVESP01_brickSOC_40 m9 : 50|14@1+ (1,0) [0|100] "%"  HVESP01
 SG_ HVESP01_brickSOC_41 m10 : 8|14@1+ (1,0) [0|100] "%"  HVESP01
 SG_ HVESP01_brickSOC_42 m10 : 22|14@1+ (1,0) [0|100] "%"  HVESP01
 SG_ HVESP01_brickSOC_43 m10 : 36|14@1+ (1,0) [0|100] "%"  HVESP01
 SG_ HVESP01_brickSOC_44 m10 : 50|14@1+ (1,0) [0|100] "%"  HVESP01
 SG_ HVESP01_brickSOC_45 m11 : 8|14@1+ (1,0) [0|100] "%"  HVESP01
 SG_ HVESP01_brickSOC_46 m11 : 22|14@1+ (1,0) [0|100] "%"  HVESP01
 SG_ HVESP01_brickSOC_47 m11 : 36|14@1+ (1,0) [0|100] "%"  HVESP01
 SG_ HVESP01_brickSOC_48 m11 : 50|14@1+ (1,0) [0|100] "%"  HVESP01
 SG_ HVESP01_brickSOC_49 m12 : 8|14@1+ (1,0) [0|100] "%"  HVESP01
 SG_ HVESP01_brickSOC_50 m12 : 22|14@1+ (1,0) [0|100] "%"  HVESP01
 SG_ HVESP01_brickSOC_51 m12 : 36|14@1+ (1,0) [0|100] "%"  HVESP01
 SG_ HVESP01_brickSOC_52 m12 : 50|14@1+ (1,0) [0|100] "%"  HVESP01
 SG_ HVESP01_brickSOC_53 m13 : 8|14@1+ (1,0) [0|100] "%"  HVESP01
 SG_ HVESP01_brickSOC_54 m13 : 22|14@1+ (1,0) [0|100] "%"  HVESP01
 SG_ HVESP01_brickSOC_55 m13 : 36|14@1+ (1,0) [0|100] "%"  HVESP01
 SG_ HVESP01_brickSOC_56 m13 : 50|14@1+ (1,0) [0|100] "%"  HVESP01
 SG_ HVESP01_brickSOC_57 m14 : 8|14@1+ (1,0) [0|100] "%"  HVESP01
 SG_ HVESP01_brickSOC_58 m14 : 22|14@1+ (1,0) [0|100] "%"  HVESP01
 SG_ HVESP01_brickSOC_59 m14 : 36|14@1+ (1,0) [0|100] "%"  HVESP01
 SG_ HVESP01_brickSOC_60 m14 : 50|14@1+ (1,0) [0|100] "%"  HVESP01
 SG_ HVESP01_brickSOC_61 m15 : 8|14@1+ (1,0) [0|100] "%"  HVESP01
 SG_ HVESP01_brickSOC_62 m15 : 22|14@1+ (1,0) [0|100] "%"  HVESP01
 SG_ HVESP01_brickSOC_63 m15 : 36|14@1+ (1,0) [0|100] "%"  HVESP01
 SG_ HVESP01_brickSOC_64 m15 : 50|14@1+ (1,0) [0|100] "%"  HVESP01
 SG_ HVESP01_brickSOC_65 m16 : 8|14@1+ (1,0) [0|100] "%"  HVESP01
 SG_ HVESP01_brickSOC_66 m16 : 22|14@1+ (1,0) [0|100] "%"  HVESP01
 SG_ HVESP01_brickSOC_67 m16 : 36|14@1+ (1,0) [0|100] "%"  HVESP01
 SG_ HVESP01_brickSOC_68 m16 : 50|14@1+ (1,0) [0|100] "%"  HVESP01
 SG_ HVESP01_brickSOC_69 m17 : 8|14@1+ (1,0) [0|100] "%"  HVESP01
 SG_ HVESP01_brickSOC_70 m17 : 22|14@1+ (1,0) [0|100] "%"  HVESP01
 SG_ HVESP01_brickSOC_71 m17 : 36|14@1+ (1,0) [0|100] "%"  HVESP01
 SG_ HVESP01_brickSOC_72 m17 : 50|14@1+ (1,0) [0|100] "%"  HVESP01
 SG_ HVESP01_brickSOC_73 m18 : 8|14@1+ (1,0) [0|100] "%"  HVESP01
 SG_ HVESP01_brickSOC_74 m18 : 22|14@1+ (1,0) [0|100] "%"  HVESP01
 SG_ HVESP01_brickSOC_75 m18 : 36|14@1+ (1,0) [0|100] "%"  HVESP01
 SG_ HVESP01_brickSOC_76 m18 : 50|14@1+ (1,0) [0|100] "%"  HVESP01
 SG_ HVESP01_brickSOC_77 m19 : 8|14@1+ (1,0) [0|100] "%"  HVESP01
 SG_ HVESP01_brickSOC_78 m19 : 22|14@1+ (1,0) [0|100] "%"  HVESP01
 SG_ HVESP01_brickSOC_79 m19 : 36|14@1+ (1,0) [0|100] "%"  HVESP01
 SG_ HVESP01_brickSOC_80 m19 : 50|14@1+ (1,0) [0|100] "%"  HVESP01
 SG_ HVESP01_brickSOC_81 m20 : 8|14@1+ (1,0) [0|100] "%"  HVESP01
 SG_ HVESP01_brickSOC_82 m20 : 22|14@1+ (1,0) [0|100] "%"  HVESP01
 SG_ HVESP01_brickSOC_83 m20 : 36|14@1+ (1,0) [0|100] "%"  HVESP01
 SG_ HVESP01_brickSOC_84 m20 : 50|14@1+ (1,0) [0|100] "%"  HVESP01
 SG_ HVESP01_brickSOC_85 m21 : 8|14@1+ (1,0) [0|100] "%"  HVESP01
 SG_ HVESP01_brickSOC_86 m21 : 22|14@1+ (1,0) [0|100] "%"  HVESP01
 SG_ HVESP01_brickSOC_87 m21 : 36|14@1+ (1,0) [0|100] "%"  HVESP01
 SG_ HVESP01_brickSOC_88 m21 : 50|14@1+ (1,0) [0|100] "%"  HVESP01
 SG_ HVESP01_brickSOC_89 m22 : 8|14@1+ (1,0) [0|100] "%"  HVESP01
 SG_ HVESP01_brickSOC_90 m22 : 22|14@1+ (1,0) [0|100] "%"  HVESP01
 SG_ HVESP01_brickSOC_91 m22 : 36|14@1+ (1,0) [0|100] "%"  HVESP01
 SG_ HVESP01_brickSOC_92 m22 : 50|14@1+ (1,0) [0|100] "%"  HVESP01
 SG_ HVESP01_brickSOC_93 m23 : 8|14@1+ (1,0) [0|100] "%"  HVESP01
 SG_ HVESP01_brickSOC_94 m23 : 22|14@1+ (1,0) [0|100] "%"  HVESP01
 SG_ HVESP01_brickSOC_95 m23 : 36|14@1+ (1,0) [0|100] "%"  HVESP01
 SG_ HVESP01_brickSOC_96 m23 : 50|14@1+ (1,0) [0|100] "%"  HVESP01
 SG_ HVESP01_brickSOC_97 m24 : 8|14@1+ (1,0) [0|100] "%"  HVESP01
 SG_ HVESP01_brickSOC_98 m24 : 22|14@1+ (1,0) [0|100] "%"  HVESP01
 SG_ HVESP01_brickSOC_99 m24 : 36|14@1+ (1,0) [0|100] "%"  HVESP01
 SG_ HVESP01_brickSOC_100 m24 : 50|14@1+ (1,0) [0|100] "%"  HVESP01
 SG_ HVESP01_brickSOC_101 m25 : 8|14@1+ (1,0) [0|100] "%"  HVESP01
 SG_ HVESP01_brickSOC_102 m25 : 22|14@1+ (1,0) [0|100] "%"  HVESP01
 SG_ HVESP01_brickSOC_103 m25 : 36|14@1+ (1,0) [0|100] "%"  HVESP01
 SG_ HVESP01_brickSOC_104 m25 : 50|14@1+ (1,0) [0|100] "%"  HVESP01
 SG_ HVESP01_brickSOC_105 m26 : 8|14@1+ (1,0) [0|100] "%"  HVESP01
 SG_ HVESP01_brickSOC_106 m26 : 22|14@1+ (1,0) [0|100] "%"  HVESP01
 SG_ HVESP01_brickSOC_107 m26 : 36|14@1+ (1,0) [0|100] "%"  HVESP01
 SG_ HVESP01_brickSOC_108 m26 : 50|14@1+ (1,0) [0|100] "%"  HVESP01
 SG_ HVESP01_brickSOC_109 m27 : 8|14@1+ (1,0) [0|100] "%"  HVESP01
 SG_ HVESP01_brickSOC_110 m27 : 22|14@1+ (1,0) [0|100] "%"  HVESP01
 SG_ HVESP01_brickSOC_111 m27 : 36|14@1+ (1,0) [0|100] "%"  HVESP01
 SG_ HVESP01_brickSOC_112 m27 : 50|14@1+ (1,0) [0|100] "%"  HVESP01
 SG_ HVESP01_brickSOC_113 m28 : 8|14@1+ (1,0) [0|100] "%"  HVESP01
 SG_ HVESP01_brickSOC_114 m28 : 22|14@1+ (1,0) [0|100] "%"  HVESP01
 SG_ HVESP01_brickSOC_115 m28 : 36|14@1+ (1,0) [0|100] "%"  HVESP01
 SG_ HVESP01_brickSOC_116 m28 : 50|14@1+ (1,0) [0|100] "%"  HVESP01
 SG_ HVESP01_brickSOC_117 m29 : 8|14@1+ (1,0) [0|100] "%"  HVESP01
 SG_ HVESP01_brickSOC_118 m29 : 22|14@1+ (1,0) [0|100] "%"  HVESP01
 SG_ HVESP01_brickSOC_119 m29 : 36|14@1+ (1,0) [0|100] "%"  HVESP01
 SG_ HVESP01_brickSOC_120 m29 : 50|14@1+ (1,0) [0|100] "%"  HVESP01
 SG_ HVESP01_brickSOC_121 m30 : 8|14@1+ (1,0) [0|100] "%"  HVESP01
 SG_ HVESP01_brickSOC_122 m30 : 22|14@1+ (1,0) [0|100] "%"  HVESP01
 SG_ HVESP01_brickSOC_123 m30 : 36|14@1+ (1,0) [0|100] "%"  HVESP01
 SG_ HVESP01_brickSOC_124 m30 : 50|14@1+ (1,0) [0|100] "%"  HVESP01
 SG_ HVESP01_brickSOC_125 m31 : 8|14@1+ (1,0) [0|100] "%"  HVESP01
 SG_ HVESP01_brickSOC_126 m31 : 22|14@1+ (1,0) [0|100] "%"  HVESP01
 SG_ HVESP01_brickSOC_127 m31 : 36|14@1+ (1,0) [0|100] "%"  HVESP01
 SG_ HVESP01_brickSOC_128 m31 : 50|14@1+ (1,0) [0|100] "%"  HVESP01
 SG_ HVESP01_brickSOC_129 m32 : 8|14@1+ (1,0) [0|100] "%"  HVESP01
 SG_ HVESP01_brickSOC_130 m32 : 22|14@1+ (1,0) [0|100] "%"  HVESP01
 SG_ HVESP01_brickSOC_131 m32 : 36|14@1+ (1,0) [0|100] "%"  HVESP01
 SG_ HVESP01_brickSOC_132 m32 : 50|14@1+ (1,0) [0|100] "%"  HVESP01
 SG_ HVESP01_brickSOC_133 m33 : 8|14@1+ (1,0) [0|100] "%"  HVESP01
 SG_ HVESP01_brickSOC_134 m33 : 22|14@1+ (1,0) [0|100] "%"  HVESP01
 SG_ HVESP01_brickSOC_135 m33 : 36|14@1+ (1,0) [0|100] "%"  HVESP01
 SG_ HVESP01_brickSOC_136 m33 : 50|14@1+ (1,0) [0|100] "%"  HVESP01
 SG_ HVESP01_brickSOC_137 m34 : 8|14@1+ (1,0) [0|100] "%"  HVESP01
 SG_ HVESP01_brickSOC_138 m34 : 22|14@1+ (1,0) [0|100] "%"  HVESP01
 SG_ HVESP01_brickSOC_139 m34 : 36|14@1+ (1,0) [0|100] "%"  HVESP01
 SG_ HVESP01_brickSOC_140 m34 : 50|14@1+ (1,0) [0|100] "%"  HVESP01
 SG_ HVESP01_brickSOC_141 m35 : 8|14@1+ (1,0) [0|100] "%"  HVESP01
 SG_ HVESP01_brickSOC_142 m35 : 22|14@1+ (1,0) [0|100] "%"  HVESP01
 SG_ HVESP01_brickSOC_143 m35 : 36|14@1+ (1,0) [0|100] "%"  HVESP01
 SG_ HVESP01_brickSOC_144 m35 : 50|14@1+ (1,0) [0|100] "%"  HVESP01
 SG_ HVESP01_brickSOC_145 m36 : 8|14@1+ (1,0) [0|100] "%"  HVESP01
 SG_ HVESP01_brickSOC_146 m36 : 22|14@1+ (1,0) [0|100] "%"  HVESP01
 SG_ HVESP01_brickSOC_147 m36 : 36|14@1+ (1,0) [0|100] "%"  HVESP01
 SG_ HVESP01_brickSOC_148 m36 : 50|14@1+ (1,0) [0|100] "%"  HVESP01
 SG_ HVESP01_brickSOC_149 m37 : 8|14@1+ (1,0) [0|100] "%"  HVESP01
 SG_ HVESP01_brickSOC_150 m37 : 22|14@1+ (1,0) [0|100] "%"  HVESP01
 SG_ HVESP01_brickSOC_151 m37 : 36|14@1+ (1,0) [0|100] "%"  HVESP01
 SG_ HVESP01_brickSOC_152 m37 : 50|14@1+ (1,0) [0|100] "%"  HVESP01
 SG_ HVESP01_brickSOC_153 m38 : 8|14@1+ (1,0) [0|100] "%"  HVESP01
 SG_ HVESP01_brickSOC_154 m38 : 22|14@1+ (1,0) [0|100] "%"  HVESP01
 SG_ HVESP01_brickSOC_155 m38 : 36|14@1+ (1,0) [0|100] "%"  HVESP01
 SG_ HVESP01_brickSOC_156 m38 : 50|14@1+ (1,0) [0|100] "%"  HVESP01
 SG_ HVESP01_brickSOC_157 m39 : 8|14@1+ (1,0) [0|100] "%"  HVESP01
 SG_ HVESP01_brickSOC_158 m39 : 22|14@1+ (1,0) [0|100] "%"  HVESP01
 SG_ HVESP01_brickSOC_159 m39 : 36|14@1+ (1,0) [0|100] "%"  HVESP01
 SG_ HVESP01_brickSOC_160 m39 : 50|14@1+ (1,0) [0|100] "%"  HVESP01
 SG_ HVESP01_brickSOC_161 m40 : 8|14@1+ (1,0) [0|100] "%"  HVESP01
 SG_ HVESP01_brickSOC_162 m40 : 22|14@1+ (1,0) [0|100] "%"  HVESP01
 SG_ HVESP01_brickSOC_163 m40 : 36|14@1+ (1,0) [0|100] "%"  HVESP01
 SG_ HVESP01_brickSOC_164 m40 : 50|14@1+ (1,0) [0|100] "%"  HVESP01
 SG_ HVESP01_brickSOC_165 m41 : 8|14@1+ (1,0) [0|100] "%"  HVESP01
 SG_ HVESP01_brickSOC_166 m41 : 22|14@1+ (1,0) [0|100] "%"  HVESP01
 SG_ HVESP01_brickSOC_167 m41 : 36|14@1+ (1,0) [0|100] "%"  HVESP01
 SG_ HVESP01_brickSOC_168 m41 : 50|14@1+ (1,0) [0|100] "%"  HVESP01
 SG_ HVESP01_brickSOC_169 m42 : 8|14@1+ (1,0) [0|100] "%"  HVESP01
 SG_ HVESP01_brickSOC_170 m42 : 22|14@1+ (1,0) [0|100] "%"  HVESP01
 SG_ HVESP01_brickSOC_171 m42 : 36|14@1+ (1,0) [0|100] "%"  HVESP01
 SG_ HVESP01_brickSOC_172 m42 : 50|14@1+ (1,0) [0|100] "%"  HVESP01
 SG_ HVESP01_brickSOC_173 m43 : 8|14@1+ (1,0) [0|100] "%"  HVESP01
 SG_ HVESP01_brickSOC_174 m43 : 22|14@1+ (1,0) [0|100] "%"  HVESP01
 SG_ HVESP01_brickSOC_175 m43 : 36|14@1+ (1,0) [0|100] "%"  HVESP01
 SG_ HVESP01_brickSOC_176 m43 : 50|14@1+ (1,0) [0|100] "%"  HVESP01
 SG_ HVESP01_brickSOC_177 m44 : 8|14@1+ (1,0) [0|100] "%"  HVESP01
 SG_ HVESP01_brickSOC_178 m44 : 22|14@1+ (1,0) [0|100] "%"  HVESP01
 SG_ HVESP01_brickSOC_179 m44 : 36|14@1+ (1,0) [0|100] "%"  HVESP01
 SG_ HVESP01_brickSOC_180 m44 : 50|14@1+ (1,0) [0|100] "%"  HVESP01
 SG_ multiplexorsoc M : 0|8@1+ (1,0) [0|255] ""  HVESP01

BO_ 2499744868 HVESP01_Inhibitions: 8 HVESP01
 SG_ HVESP01_inhibitionPyroFuse : 9|1@1+ (1,0) [0|1] ""  HVESP01
 SG_ HVESP01_inhibitionRegen : 8|1@1+ (1,0) [0|1] ""  HVESP01
 SG_ HVESP01_inhibitionFullPower : 7|1@1+ (1,0) [0|1] ""  HVESP01
 SG_ HVESP01_inhibitionRampDown : 6|1@1+ (1,0) [0|1] ""  HVESP01
 SG_ HVESP01_inhibitionSupportEntry : 5|1@1+ (1,0) [0|1] ""  HVESP01
 SG_ HVESP01_inhibitionSupport : 4|1@1+ (1,0) [0|1] ""  HVESP01
 SG_ HVESP01_inhibitionDriveEntry : 3|1@1+ (1,0) [0|1] ""  HVESP01
 SG_ HVESP01_inhibitionDrive : 2|1@1+ (1,0) [0|1] ""  HVESP01
 SG_ HVESP01_inhibitionCharge : 1|1@1+ (1,0) [0|1] ""  HVESP01
 SG_ HVESP01_inhibitionChargeEntry : 0|1@1+ (1,0) [0|1] ""  HVESP01

BO_ 2499740772 HVESP01_SpeakerClaim: 8 HVESP01
 SG_ HVESP01_speakerClaimFlag : 0|2@1+ (1,0) [0|3] ""  HVESP01
 SG_ HVESP01_expectedSpeakerID : 2|8@1+ (1,0) [0|255] ""  HVESP01

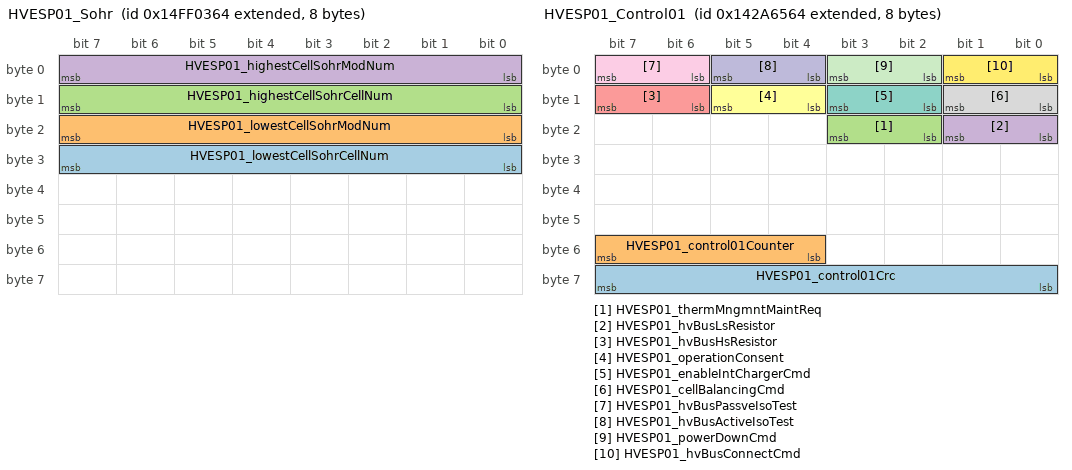
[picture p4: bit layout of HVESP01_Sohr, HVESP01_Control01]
BO_ 2499740516 HVESP01_Sohr: 8 HVESP01
 SG_ HVESP01_lowestCellSohrCellNum : 24|8@1+ (1,0) [0|250] "count"  HVESP01
 SG_ HVESP01_lowestCellSohrModNum : 16|8@1+ (1,0) [0|250] "count"  HVESP01
 SG_ HVESP01_highestCellSohrCellNum : 8|8@1+ (1,0) [0|250] "count"  HVESP01
 SG_ HVESP01_highestCellSohrModNum : 0|8@1+ (1,0) [0|250] "count"  HVESP01

BO_ 2499500388 HVESP01_History: 8 HVESP01
 SG_ HVESP01_stateOfHealth : 0|8@1+ (0.4,0) [0|100] "%"  HVESP01

BO_ 2485806436 HVESP01_Control01: 8 HVESS
 SG_ HVESP01_control01Crc : 56|8@1+ (1,0) [0|255] ""  HVESS
 SG_ HVESP01_control01Counter : 52|4@1+ (1,0) [0|15] ""  HVESS
 SG_ HVESP01_thermMngmntMaintReq : 18|2@1+ (1,0) [0|3] ""  HVESS
 SG_ HVESP01_hvBusLsResistor : 16|2@1+ (1,0) [0|3] ""  HVESS
 SG_ HVESP01_hvBusHsResistor : 14|2@1+ (1,0) [0|3] ""  HVESS
 SG_ HVESP01_operationConsent : 12|2@1+ (1,0) [0|3] ""  HVESS
 SG_ HVESP01_enableIntChargerCmd : 10|2@1+ (1,0) [0|3] ""  HVESS
 SG_ HVESP01_cellBalancingCmd : 8|2@1+ (1,0) [0|3] ""  HVESS
 SG_ HVESP01_hvBusPassveIsoTest : 6|2@1+ (1,0) [0|3] ""  HVESS
 SG_ HVESP01_hvBusActiveIsoTest : 4|2@1+ (1,0) [0|3] ""  HVESS
 SG_ HVESP01_powerDownCmd : 2|2@1+ (1,0) [0|3] ""  HVESS
 SG_ HVESP01_hvBusConnectCmd : 0|2@1+ (1,0) [0|3] ""  HVESS

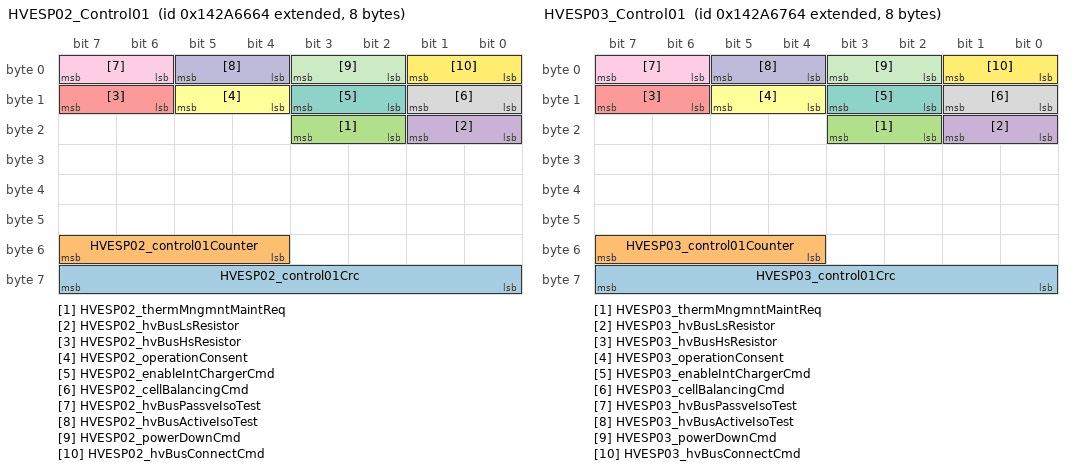
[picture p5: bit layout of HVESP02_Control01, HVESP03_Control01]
BO_ 2485806692 HVESP02_Control01: 8 HVESS
 SG_ HVESP02_control01Crc : 56|8@1+ (1,0) [0|255] ""  HVESS
 SG_ HVESP02_control01Counter : 52|4@1+ (1,0) [0|15] ""  HVESS
 SG_ HVESP02_thermMngmntMaintReq : 18|2@1+ (1,0) [0|3] ""  HVESS
 SG_ HVESP02_hvBusLsResistor : 16|2@1+ (1,0) [0|3] ""  HVESS
 SG_ HVESP02_hvBusHsResistor : 14|2@1+ (1,0) [0|3] ""  HVESS
 SG_ HVESP02_operationConsent : 12|2@1+ (1,0) [0|3] ""  HVESS
 SG_ HVESP02_enableIntChargerCmd : 10|2@1+ (1,0) [0|3] ""  HVESS
 SG_ HVESP02_cellBalancingCmd : 8|2@1+ (1,0) [0|3] ""  HVESS
 SG_ HVESP02_hvBusPassveIsoTest : 6|2@1+ (1,0) [0|3] ""  HVESS
 SG_ HVESP02_hvBusActiveIsoTest : 4|2@1+ (1,0) [0|3] ""  HVESS
 SG_ HVESP02_powerDownCmd : 2|2@1+ (1,0) [0|3] ""  HVESS
 SG_ HVESP02_hvBusConnectCmd : 0|2@1+ (1,0) [0|3] ""  HVESS

BO_ 2485806948 HVESP03_Control01: 8 HVESS
 SG_ HVESP03_control01Crc : 56|8@1+ (1,0) [0|255] ""  HVESS
 SG_ HVESP03_control01Counter : 52|4@1+ (1,0) [0|15] ""  HVESS
 SG_ HVESP03_thermMngmntMaintReq : 18|2@1+ (1,0) [0|3] ""  HVESS
 SG_ HVESP03_hvBusLsResistor : 16|2@1+ (1,0) [0|3] ""  HVESS
 SG_ HVESP03_hvBusHsResistor : 14|2@1+ (1,0) [0|3] ""  HVESS
 SG_ HVESP03_operationConsent : 12|2@1+ (1,0) [0|3] ""  HVESS
 SG_ HVESP03_enableIntChargerCmd : 10|2@1+ (1,0) [0|3] ""  HVESS
 SG_ HVESP03_cellBalancingCmd : 8|2@1+ (1,0) [0|3] ""  HVESS
 SG_ HVESP03_hvBusPassveIsoTest : 6|2@1+ (1,0) [0|3] ""  HVESS
 SG_ HVESP03_hvBusActiveIsoTest : 4|2@1+ (1,0) [0|3] ""  HVESS
 SG_ HVESP03_powerDownCmd : 2|2@1+ (1,0) [0|3] ""  HVESS
 SG_ HVESP03_hvBusConnectCmd : 0|2@1+ (1,0) [0|3] ""  HVESS

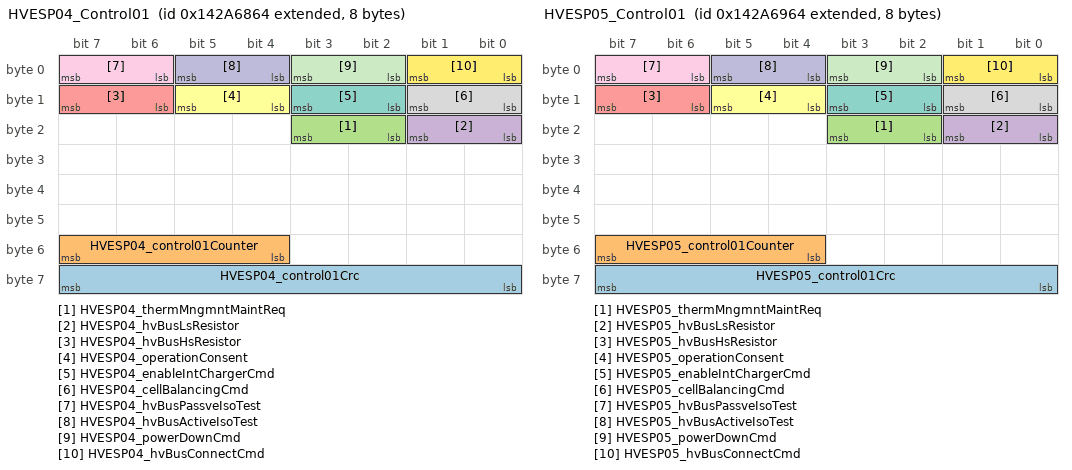
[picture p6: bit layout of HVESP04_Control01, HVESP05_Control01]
BO_ 2485807204 HVESP04_Control01: 8 HVESS
 SG_ HVESP04_control01Crc : 56|8@1+ (1,0) [0|255] ""  HVESS
 SG_ HVESP04_control01Counter : 52|4@1+ (1,0) [0|15] ""  HVESS
 SG_ HVESP04_thermMngmntMaintReq : 18|2@1+ (1,0) [0|3] ""  HVESS
 SG_ HVESP04_hvBusLsResistor : 16|2@1+ (1,0) [0|3] ""  HVESS
 SG_ HVESP04_hvBusHsResistor : 14|2@1+ (1,0) [0|3] ""  HVESS
 SG_ HVESP04_operationConsent : 12|2@1+ (1,0) [0|3] ""  HVESS
 SG_ HVESP04_enableIntChargerCmd : 10|2@1+ (1,0) [0|3] ""  HVESS
 SG_ HVESP04_cellBalancingCmd : 8|2@1+ (1,0) [0|3] ""  HVESS
 SG_ HVESP04_hvBusPassveIsoTest : 6|2@1+ (1,0) [0|3] ""  HVESS
 SG_ HVESP04_hvBusActiveIsoTest : 4|2@1+ (1,0) [0|3] ""  HVESS
 SG_ HVESP04_powerDownCmd : 2|2@1+ (1,0) [0|3] ""  HVESS
 SG_ HVESP04_hvBusConnectCmd : 0|2@1+ (1,0) [0|3] ""  HVESS

BO_ 2485807460 HVESP05_Control01: 8 HVESS
 SG_ HVESP05_control01Crc : 56|8@1+ (1,0) [0|255] ""  HVESS
 SG_ HVESP05_control01Counter : 52|4@1+ (1,0) [0|15] ""  HVESS
 SG_ HVESP05_thermMngmntMaintReq : 18|2@1+ (1,0) [0|3] ""  HVESS
 SG_ HVESP05_hvBusLsResistor : 16|2@1+ (1,0) [0|3] ""  HVESS
 SG_ HVESP05_hvBusHsResistor : 14|2@1+ (1,0) [0|3] ""  HVESS
 SG_ HVESP05_operationConsent : 12|2@1+ (1,0) [0|3] ""  HVESS
 SG_ HVESP05_enableIntChargerCmd : 10|2@1+ (1,0) [0|3] ""  HVESS
 SG_ HVESP05_cellBalancingCmd : 8|2@1+ (1,0) [0|3] ""  HVESS
 SG_ HVESP05_hvBusPassveIsoTest : 6|2@1+ (1,0) [0|3] ""  HVESS
 SG_ HVESP05_hvBusActiveIsoTest : 4|2@1+ (1,0) [0|3] ""  HVESS
 SG_ HVESP05_powerDownCmd : 2|2@1+ (1,0) [0|3] ""  HVESS
 SG_ HVESP05_hvBusConnectCmd : 0|2@1+ (1,0) [0|3] ""  HVESS

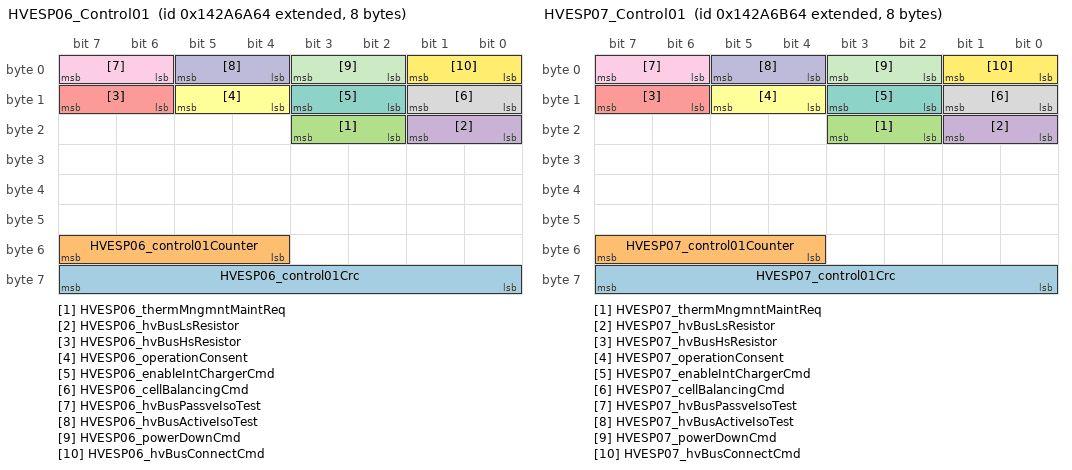
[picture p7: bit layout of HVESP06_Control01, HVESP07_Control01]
BO_ 2485807716 HVESP06_Control01: 8 HVESS
 SG_ HVESP06_control01Crc : 56|8@1+ (1,0) [0|255] ""  HVESS
 SG_ HVESP06_control01Counter : 52|4@1+ (1,0) [0|15] ""  HVESS
 SG_ HVESP06_thermMngmntMaintReq : 18|2@1+ (1,0) [0|3] ""  HVESS
 SG_ HVESP06_hvBusLsResistor : 16|2@1+ (1,0) [0|3] ""  HVESS
 SG_ HVESP06_hvBusHsResistor : 14|2@1+ (1,0) [0|3] ""  HVESS
 SG_ HVESP06_operationConsent : 12|2@1+ (1,0) [0|3] ""  HVESS
 SG_ HVESP06_enableIntChargerCmd : 10|2@1+ (1,0) [0|3] ""  HVESS
 SG_ HVESP06_cellBalancingCmd : 8|2@1+ (1,0) [0|3] ""  HVESS
 SG_ HVESP06_hvBusPassveIsoTest : 6|2@1+ (1,0) [0|3] ""  HVESS
 SG_ HVESP06_hvBusActiveIsoTest : 4|2@1+ (1,0) [0|3] ""  HVESS
 SG_ HVESP06_powerDownCmd : 2|2@1+ (1,0) [0|3] ""  HVESS
 SG_ HVESP06_hvBusConnectCmd : 0|2@1+ (1,0) [0|3] ""  HVESS

BO_ 2485807972 HVESP07_Control01: 8 HVESS
 SG_ HVESP07_control01Crc : 56|8@1+ (1,0) [0|255] ""  HVESS
 SG_ HVESP07_control01Counter : 52|4@1+ (1,0) [0|15] ""  HVESS
 SG_ HVESP07_thermMngmntMaintReq : 18|2@1+ (1,0) [0|3] ""  HVESS
 SG_ HVESP07_hvBusLsResistor : 16|2@1+ (1,0) [0|3] ""  HVESS
 SG_ HVESP07_hvBusHsResistor : 14|2@1+ (1,0) [0|3] ""  HVESS
 SG_ HVESP07_operationConsent : 12|2@1+ (1,0) [0|3] ""  HVESS
 SG_ HVESP07_enableIntChargerCmd : 10|2@1+ (1,0) [0|3] ""  HVESS
 SG_ HVESP07_cellBalancingCmd : 8|2@1+ (1,0) [0|3] ""  HVESS
 SG_ HVESP07_hvBusPassveIsoTest : 6|2@1+ (1,0) [0|3] ""  HVESS
 SG_ HVESP07_hvBusActiveIsoTest : 4|2@1+ (1,0) [0|3] ""  HVESS
 SG_ HVESP07_powerDownCmd : 2|2@1+ (1,0) [0|3] ""  HVESS
 SG_ HVESP07_hvBusConnectCmd : 0|2@1+ (1,0) [0|3] ""  HVESS

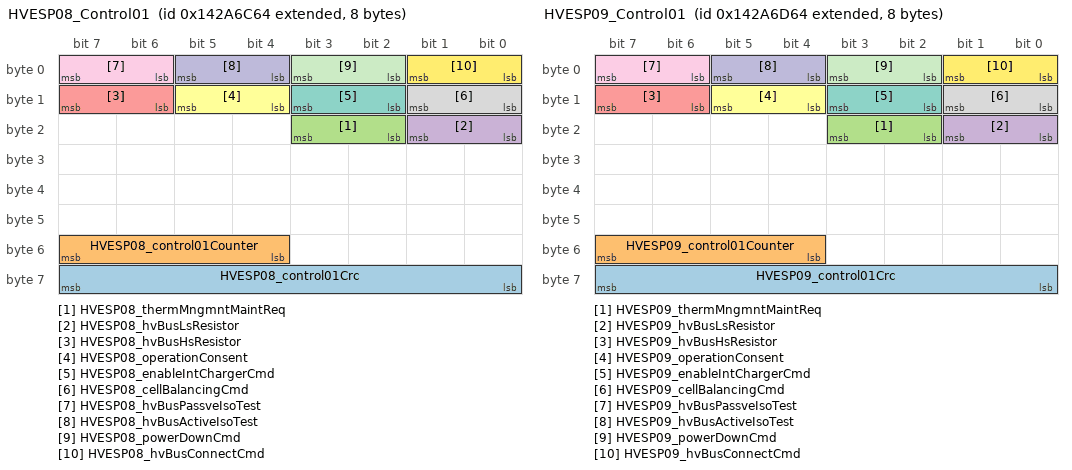
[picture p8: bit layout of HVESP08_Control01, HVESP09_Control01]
BO_ 2485808228 HVESP08_Control01: 8 HVESS
 SG_ HVESP08_control01Crc : 56|8@1+ (1,0) [0|255] ""  HVESS
 SG_ HVESP08_control01Counter : 52|4@1+ (1,0) [0|15] ""  HVESS
 SG_ HVESP08_thermMngmntMaintReq : 18|2@1+ (1,0) [0|3] ""  HVESS
 SG_ HVESP08_hvBusLsResistor : 16|2@1+ (1,0) [0|3] ""  HVESS
 SG_ HVESP08_hvBusHsResistor : 14|2@1+ (1,0) [0|3] ""  HVESS
 SG_ HVESP08_operationConsent : 12|2@1+ (1,0) [0|3] ""  HVESS
 SG_ HVESP08_enableIntChargerCmd : 10|2@1+ (1,0) [0|3] ""  HVESS
 SG_ HVESP08_cellBalancingCmd : 8|2@1+ (1,0) [0|3] ""  HVESS
 SG_ HVESP08_hvBusPassveIsoTest : 6|2@1+ (1,0) [0|3] ""  HVESS
 SG_ HVESP08_hvBusActiveIsoTest : 4|2@1+ (1,0) [0|3] ""  HVESS
 SG_ HVESP08_powerDownCmd : 2|2@1+ (1,0) [0|3] ""  HVESS
 SG_ HVESP08_hvBusConnectCmd : 0|2@1+ (1,0) [0|3] ""  HVESS

BO_ 2485808484 HVESP09_Control01: 8 HVESS
 SG_ HVESP09_control01Crc : 56|8@1+ (1,0) [0|255] ""  HVESS
 SG_ HVESP09_control01Counter : 52|4@1+ (1,0) [0|15] ""  HVESS
 SG_ HVESP09_thermMngmntMaintReq : 18|2@1+ (1,0) [0|3] ""  HVESS
 SG_ HVESP09_hvBusLsResistor : 16|2@1+ (1,0) [0|3] ""  HVESS
 SG_ HVESP09_hvBusHsResistor : 14|2@1+ (1,0) [0|3] ""  HVESS
 SG_ HVESP09_operationConsent : 12|2@1+ (1,0) [0|3] ""  HVESS
 SG_ HVESP09_enableIntChargerCmd : 10|2@1+ (1,0) [0|3] ""  HVESS
 SG_ HVESP09_cellBalancingCmd : 8|2@1+ (1,0) [0|3] ""  HVESS
 SG_ HVESP09_hvBusPassveIsoTest : 6|2@1+ (1,0) [0|3] ""  HVESS
 SG_ HVESP09_hvBusActiveIsoTest : 4|2@1+ (1,0) [0|3] ""  HVESS
 SG_ HVESP09_powerDownCmd : 2|2@1+ (1,0) [0|3] ""  HVESS
 SG_ HVESP09_hvBusConnectCmd : 0|2@1+ (1,0) [0|3] ""  HVESS

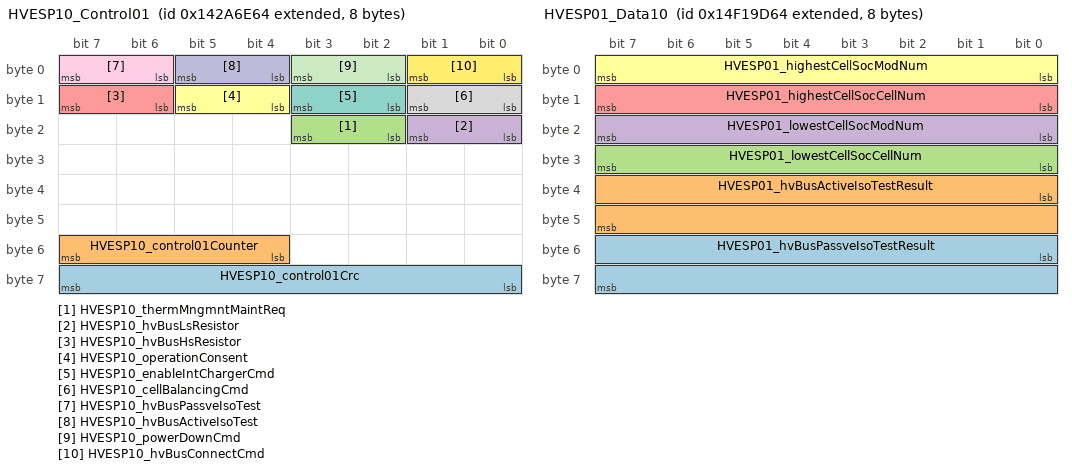
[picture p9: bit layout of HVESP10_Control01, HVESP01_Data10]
BO_ 2485808740 HVESP10_Control01: 8 HVESS
 SG_ HVESP10_control01Crc : 56|8@1+ (1,0) [0|255] ""  HVESS
 SG_ HVESP10_control01Counter : 52|4@1+ (1,0) [0|15] ""  HVESS
 SG_ HVESP10_thermMngmntMaintReq : 18|2@1+ (1,0) [0|3] ""  HVESS
 SG_ HVESP10_hvBusLsResistor : 16|2@1+ (1,0) [0|3] ""  HVESS
 SG_ HVESP10_hvBusHsResistor : 14|2@1+ (1,0) [0|3] ""  HVESS
 SG_ HVESP10_operationConsent : 12|2@1+ (1,0) [0|3] ""  HVESS
 SG_ HVESP10_enableIntChargerCmd : 10|2@1+ (1,0) [0|3] ""  HVESS
 SG_ HVESP10_cellBalancingCmd : 8|2@1+ (1,0) [0|3] ""  HVESS
 SG_ HVESP10_hvBusPassveIsoTest : 6|2@1+ (1,0) [0|3] ""  HVESS
 SG_ HVESP10_hvBusActiveIsoTest : 4|2@1+ (1,0) [0|3] ""  HVESS
 SG_ HVESP10_powerDownCmd : 2|2@1+ (1,0) [0|3] ""  HVESS
 SG_ HVESP10_hvBusConnectCmd : 0|2@1+ (1,0) [0|3] ""  HVESS

BO_ 2498860900 HVESP01_Status01: 8 HVESP01
 SG_ HVESP01_status01Crc : 56|8@1+ (1,0) [0|255] "count"  HVESP01
 SG_ HVESP01_status01Counter : 52|4@1+ (1,0) [0|15] ""  HVESP01
 SG_ HVESP01_operationalStatus : 44|4@1+ (1,0) [0|15] ""  HVESP01
 SG_ HVESP01_hvBusConnectionStatus : 40|4@1+ (1,0) [0|15] ""  HVESP01
 SG_ HVESP01_cellBalancingActive : 30|2@1+ (1,0) [0|3] ""  HVESP01
 SG_ HVESP01_internalChargeStatus : 32|2@1+ (1,0) [0|3] ""  HVESP01
 SG_ HVESP01_cellBalanceStatus : 28|2@1+ (1,0) [0|3] ""  HVESP01
 SG_ HVESP01_socStatus : 24|4@1+ (1,0) [0|15] ""  HVESP01
 SG_ HVESP01_inertiaSwitchStatus : 22|2@1+ (1,0) [0|3] ""  HVESP01
 SG_ HVESP01_hvilStatus : 20|2@1+ (1,0) [0|3] ""  HVESP01
 SG_ HVESP01_hvBusPassveIsoTestStatus : 16|4@1+ (1,0) [0|15] ""  HVESP01
 SG_ HVESP01_hvBusActiveIsoTestStatus : 12|4@1+ (1,0) [0|15] ""  HVESP01
 SG_ HVESP01_centerOfPackContState : 10|2@1+ (1,0) [0|3] ""  HVESP01
 SG_ HVESP01_hvBusPrechgRelayState : 8|2@1+ (1,0) [0|3] "V"  HVESP01
 SG_ HVESP01_hvBusDisconnect : 4|4@1+ (1,0) [0|15] "V"  HVESP01
 SG_ HVESP01_hvBusNegContState : 2|2@1+ (1,0) [0|3] "V"  HVESP01
 SG_ HVESP01_hvBusPosContState : 0|2@1+ (1,0) [0|3] "V"  HVESP01

BO_ 2498862436 HVESP01_Data10: 8 HVESP01
 SG_ HVESP01_hvBusPassveIsoTestResult : 48|16@1+ (0.1,0) [0|6425.5] "ohm per V"  HVESP01
 SG_ HVESP01_hvBusActiveIsoTestResult : 32|16@1+ (0.1,0) [0|6425.5] "ohm per V"  HVESP01
 SG_ HVESP01_lowestCellSocCellNum : 24|8@1+ (1,0) [0|250] "count"  HVESP01
 SG_ HVESP01_lowestCellSocModNum : 16|8@1+ (1,0) [0|250] "count"  HVESP01
 SG_ HVESP01_highestCellSocCellNum : 8|8@1+ (1,0) [0|250] "count"  HVESP01
 SG_ HVESP01_highestCellSocModNum : 0|8@1+ (1,0) [0|250] "count"  HVESP01

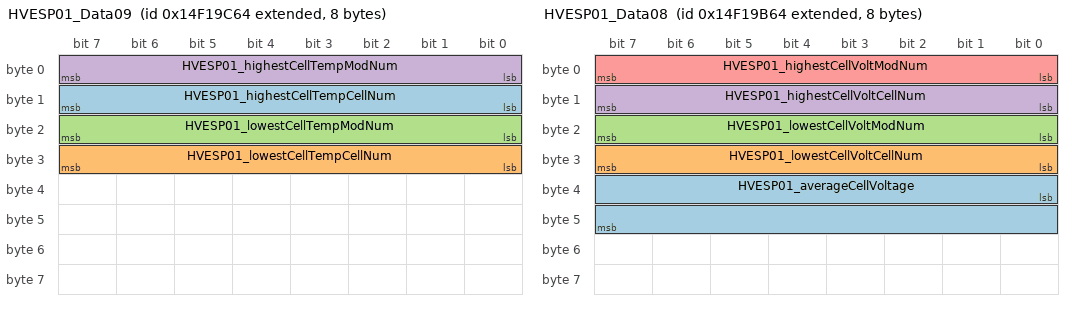
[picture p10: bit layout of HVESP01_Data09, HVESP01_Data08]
BO_ 2498862180 HVESP01_Data09: 8 HVESP01
 SG_ HVESP01_highestCellTempCellNum : 8|8@1+ (1,0) [0|250] "count"  HVESP01
 SG_ HVESP01_lowestCellTempCellNum : 24|8@1+ (1,0) [0|250] "count"  HVESP01
 SG_ HVESP01_lowestCellTempModNum : 16|8@1+ (1,0) [0|250] "count"  HVESP01
 SG_ HVESP01_highestCellTempModNum : 0|8@1+ (1,0) [0|250] "count"  HVESP01

BO_ 2498861924 HVESP01_Data08: 8 HVESP01
 SG_ HVESP01_averageCellVoltage : 32|16@1+ (0.001,0) [0|64.255] "V"  HVESP01
 SG_ HVESP01_lowestCellVoltCellNum : 24|8@1+ (1,0) [0|250] "count"  HVESP01
 SG_ HVESP01_lowestCellVoltModNum : 16|8@1+ (1,0) [0|250] "count"  HVESP01
 SG_ HVESP01_highestCellVoltCellNum : 8|8@1+ (1,0) [0|250] "count"  HVESP01
 SG_ HVESP01_highestCellVoltModNum : 0|8@1+ (1,0) [0|250] "count"  HVESP01

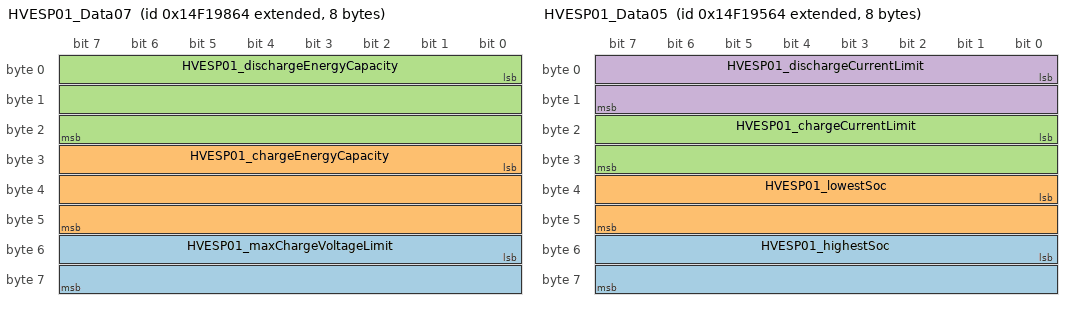
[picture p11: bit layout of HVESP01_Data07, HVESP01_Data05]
BO_ 2498861156 HVESP01_Data07: 8 HVESP01
 SG_ HVESP01_maxChargeVoltageLimit : 48|16@1+ (0.05,0) [0|3212.75] "V"  HVESP01
 SG_ HVESP01_chargeEnergyCapacity : 24|24@1+ (0.001,0) [0|16449.535] "kWh"  HVESP01
 SG_ HVESP01_dischargeEnergyCapacity : 0|24@1+ (0.001,0) [0|16449.535] "kWh"  HVESP01

BO_ 2498860388 HVESP01_Data05: 8 HVESP01
 SG_ HVESP01_highestSoc : 48|16@1+ (0.0015625,0) [0|100.3984375] "%"  HVESP01
 SG_ HVESP01_lowestSoc : 32|16@1+ (0.0015625,0) [0|100.3984375] "%"  HVESP01
 SG_ HVESP01_chargeCurrentLimit : 16|16@1+ (0.05,-1600) [-1600|1612.75] "A"  HVESP01
 SG_ HVESP01_dischargeCurrentLimit : 0|16@1+ (0.05,-1600) [-1600|1612.75] "A"  HVESP01

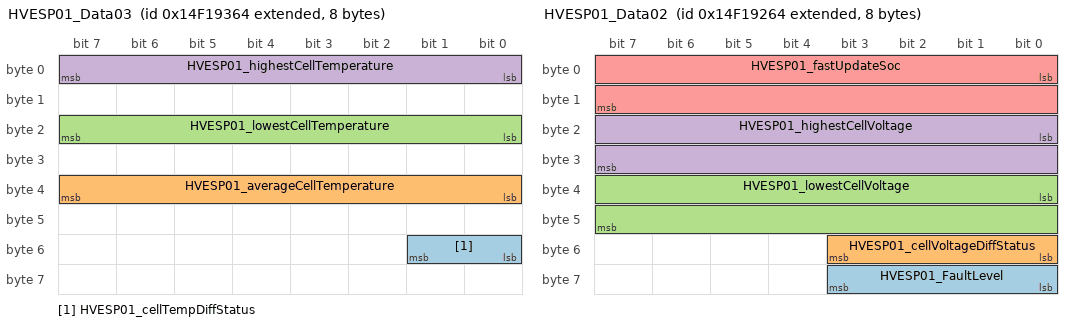
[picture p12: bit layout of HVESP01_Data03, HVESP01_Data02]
BO_ 2498859876 HVESP01_Data03: 8 HVESP01
 SG_ HVESP01_cellTempDiffStatus : 48|2@1+ (1,0) [0|3] ""  HVESP01
 SG_ HVESP01_averageCellTemperature : 32|8@1- (1,25) [-103|152] "C"  HVESP01
 SG_ HVESP01_lowestCellTemperature : 16|8@1- (1,25) [-103|152] "C"  HVESP01
 SG_ HVESP01_highestCellTemperature : 0|8@1- (1,25) [-103|152] "C"  HVESP01

BO_ 2498859620 HVESP01_Data02: 8 HVESP01
 SG_ HVESP01_FaultLevel : 56|4@1+ (1,0) [0|15] ""  HVESP01
 SG_ HVESP01_cellVoltageDiffStatus : 48|4@1+ (1,0) [0|15] ""  HVESP01
 SG_ HVESP01_lowestCellVoltage : 32|16@1+ (0.001,0) [0|64.255] "V"  HVESP01
 SG_ HVESP01_highestCellVoltage : 16|16@1+ (0.001,0) [0|64.255] "V"  HVESP01
 SG_ HVESP01_fastUpdateSoc : 0|16@1+ (0.0015625,0) [0|100.3984375] "%"  HVESP01

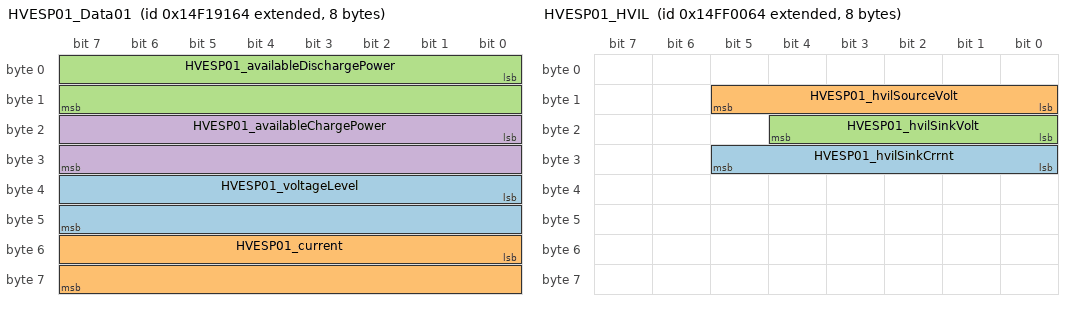
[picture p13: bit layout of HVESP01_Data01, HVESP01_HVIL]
BO_ 2498859364 HVESP01_Data01: 8 HVESP01
 SG_ HVESP01_voltageLevel : 32|16@1+ (0.05,0) [0|3212.75] "V"  HVESP01
 SG_ HVESP01_current : 48|16@1+ (0.05,-1600) [-1600|1612.75] "A"  HVESP01
 SG_ HVESP01_availableDischargePower : 0|16@1+ (0.05,0) [0|3212.75] "kW"  HVESP01
 SG_ HVESP01_availableChargePower : 16|16@1+ (0.05,0) [0|3212.75] "kW"  HVESP01

BO_ 2499743844 HVESP01_DiagnosticA: 8 HVESP01
 SG_ HVESP01_vBrickOverSev : 2|2@1+ (1,0) [0|3] ""  HVESP01
 SG_ HVESP01_vBrickOverMod : 0|2@1+ (1,0) [0|3] ""  HVESP01
 SG_ HVESP01_vBrickOverWar : 14|2@1+ (1,0) [0|3] ""  HVESP01
 SG_ HVESP01_HVESP01Quiet : 12|2@1+ (1,0) [0|3] ""  HVESP01
 SG_ HVESP01_vBrickUnderMod : 10|2@1+ (1,0) [0|3] ""  HVESP01
 SG_ HVESP01_vBrickUnderWar : 8|2@1+ (1,0) [0|3] ""  HVESP01
 SG_ HVESP01_TempModuleOverSev : 22|2@1+ (1,0) [0|3] ""  HVESP01
 SG_ HVESP01_TempModuleOverMod : 20|2@1+ (1,0) [0|3] ""  HVESP01
 SG_ HVESP01_TempModuleOverWar : 18|2@1+ (1,0) [0|3] ""  HVESP01
 SG_ HVESP01_TempModuleUnderSev : 16|2@1+ (1,0) [0|3] ""  HVESP01
 SG_ HVESP01_TempModuleUnderMod : 30|2@1+ (1,0) [0|3] ""  HVESP01
 SG_ HVESP01_TempModuleUnderWar : 28|2@1+ (1,0) [0|3] ""  HVESP01
 SG_ HVESP01_iOvercharge : 26|2@1+ (1,0) [0|3] ""  HVESP01
 SG_ HVESP01_iOverdischarge : 24|2@1+ (1,0) [0|3] ""  HVESP01
 SG_ HVESP01_iOverHardware : 38|2@1+ (1,0) [0|3] ""  HVESP01
 SG_ HVESP01_PosDcContStuckOpen : 36|2@1+ (1,0) [0|3] ""  HVESP01
 SG_ HVESP01_PosDcContWelded : 34|2@1+ (1,0) [0|3] ""  HVESP01
 SG_ HVESP01_NegDcContStuckOpen : 32|2@1+ (1,0) [0|3] ""  HVESP01
 SG_ HVESP01_NegDcContWelded : 46|2@1+ (1,0) [0|3] ""  HVESP01
 SG_ HVESP01_PrechgTooFast : 44|2@1+ (1,0) [0|3] ""  HVESP01
 SG_ HVESP01_PrechgContWelded : 42|2@1+ (1,0) [0|3] ""  HVESP01
 SG_ HVESP01_PrechgTimeout : 40|2@1+ (1,0) [0|3] ""  HVESP01
 SG_ HVESP01_PrechgContStuckOpen : 54|2@1+ (1,0) [0|3] ""  HVESP01
 SG_ HVESP01_ModuleImbalance : 52|2@1+ (1,0) [0|3] ""  HVESP01
 SG_ HVESP01_ModuleMIA : 50|2@1+ (1,0) [0|3] ""  HVESP01
 SG_ HVESP01_SensePackVoltError : 48|2@1+ (1,0) [0|3] ""  HVESP01
 SG_ HVESP01_SenseLoadVoltError : 62|2@1+ (1,0) [0|3] ""  HVESP01
 SG_ HVESP01_SenseShuntError : 60|2@1+ (1,0) [0|3] ""  HVESP01
 SG_ HVESP01_SenseFcVoltErrorr : 58|2@1+ (1,0) [0|3] ""  HVESP01
 SG_ HVESP01_SenseBrickOpen : 56|2@1+ (1,0) [0|3] ""  HVESP01

BO_ 2499744100 HVESP01_DiagnosticB: 8 HVESP01
 SG_ HVESP01_SenseBrickImpHigh : 2|2@1+ (1,0) [0|3] ""  HVESP01
 SG_ HVESP01_AFEfault : 0|2@1+ (1,0) [0|3] ""  HVESP01
 SG_ HVESP01_AFEerror : 14|2@1+ (1,0) [0|3] ""  HVESP01
 SG_ HVESP01_HVESP01MIA : 12|2@1+ (1,0) [0|3] ""  HVESP01
 SG_ HVESP01_TempAmbientOverSev : 10|2@1+ (1,0) [0|3] ""  HVESP01
 SG_ HVESP01_TempAmbientOverMod : 8|2@1+ (1,0) [0|3] ""  HVESP01
 SG_ HVESP01_TempAmbientOverWar : 22|2@1+ (1,0) [0|3] ""  HVESP01
 SG_ HVESP01_AbnormReset : 20|2@1+ (1,0) [0|3] ""  HVESP01
 SG_ HVESP01_SenseAuxVoltError : 18|2@1+ (1,0) [0|3] ""  HVESP01
 SG_ HVESP01_CalibrationInvalid : 16|2@1+ (1,0) [0|3] ""  HVESP01
 SG_ HVESP01_TaskLockup : 30|2@1+ (1,0) [0|3] ""  HVESP01
 SG_ HVESP01_RAMover : 28|2@1+ (1,0) [0|3] ""  HVESP01
 SG_ HVESP01_BrickOverdischarge : 26|2@1+ (1,0) [0|3] ""  HVESP01
 SG_ HVESP01_BrickOvercharge : 24|2@1+ (1,0) [0|3] ""  HVESP01
 SG_ HVESP01_vBrickImbalance : 38|2@1+ (1,0) [0|3] ""  HVESP01
 SG_ HVESP01_TempBrickImbalance : 36|2@1+ (1,0) [0|3] ""  HVESP01
 SG_ HVESP01_CapPackLow : 34|2@1+ (1,0) [0|3] ""  HVESP01
 SG_ HVESP01_rBrickHigh : 32|2@1+ (1,0) [0|3] ""  HVESP01
 SG_ HVESP01_PowerpackInsuffErr : 46|2@1+ (1,0) [0|3] ""  HVESP01
 SG_ HVESP01_BrickSoftShort : 44|2@1+ (1,0) [0|3] ""  HVESP01
 SG_ HVESP01_chargeUndercurrent : 42|2@1+ (1,0) [0|3] ""  HVESP01
 SG_ HVESP01_HVILcurrentSourceError : 40|2@1+ (1,0) [0|3] ""  HVESP01
 SG_ HVESP01_SRS : 54|2@1+ (1,0) [0|3] ""  HVESP01
 SG_ HVESP01_IsolationExtWar : 52|2@1+ (1,0) [0|3] ""  HVESP01
 SG_ HVESP01_IsolationIntWar : 50|2@1+ (1,0) [0|3] ""  HVESP01
 SG_ HVESP01_PyroFuseBlown : 48|2@1+ (1,0) [0|3] ""  HVESP01
 SG_ HVESP01_vBrickUnderSev : 62|2@1+ (1,0) [0|3] ""  HVESP01
 SG_ HVESP01_chargePrechargeTimeout : 60|2@1+ (1,0) [0|3] ""  HVESP01
 SG_ HVESP01_ModuleThermistorShort : 58|2@1+ (1,0) [0|3] ""  HVESP01
 SG_ HVESP01_ModuleThermistorBroken : 56|2@1+ (1,0) [0|3] ""  HVESP01

BO_ 2499744356 HVESP01_DiagnosticC: 8 HVESP01
 SG_ HVESP01_PackVoltageImbalance : 58|2@1+ (1,0) [0|3] ""  HVESP01
 SG_ HVESP01_PrechargeoverCurrent : 56|2@1+ (1,0) [0|3] ""  HVESP01
 SG_ HVESP01_HVILvoltageError : 2|2@1+ (1,0) [0|3] ""  HVESP01
 SG_ HVESP01_HVILcurrentReturnError : 0|2@1+ (1,0) [0|3] ""  HVESP01
 SG_ HVESP01_PosFcContWelded : 14|2@1+ (1,0) [0|3] ""  HVESP01
 SG_ HVESP01_PosFcContStuckOpen : 12|2@1+ (1,0) [0|3] ""  HVESP01
 SG_ HVESP01_NegFcContWelded : 10|2@1+ (1,0) [0|3] ""  HVESP01
 SG_ HVESP01_NegFcContStuckOpen : 8|2@1+ (1,0) [0|3] ""  HVESP01
 SG_ HVESP01_IsospiBreak : 22|2@1+ (1,0) [0|3] ""  HVESP01
 SG_ HVESP01_IsolationIntFault : 20|2@1+ (1,0) [0|3] ""  HVESP01
 SG_ HVESP01_IsolationExtFault : 18|2@1+ (1,0) [0|3] ""  HVESP01
 SG_ HVESP01_12v_filter_error : 16|2@1+ (1,0) [0|3] ""  HVESP01
 SG_ HVESP01_hall_eff_hi_rang_err : 30|2@1+ (1,0) [0|3] ""  HVESP01
 SG_ HVESP01_brick_volt_sns_open : 28|2@1+ (1,0) [0|3] ""  HVESP01
 SG_ HVESP01_5v_error : 26|2@1+ (1,0) [0|3] ""  HVESP01
 SG_ HVESP01_3_3_hot_error : 24|2@1+ (1,0) [0|3] ""  HVESP01
 SG_ HVESP01_12v_input_error : 38|2@1+ (1,0) [0|3] ""  HVESP01
 SG_ HVESP01_1_25v_error : 36|2@1+ (1,0) [0|3] ""  HVESP01
 SG_ HVESP01_shunt_MIA : 34|2@1+ (1,0) [0|3] ""  HVESP01
 SG_ HVESP01_SBC_int_reg_error : 32|2@1+ (1,0) [0|3] ""  HVESP01
 SG_ HVESP01_pos_3_3v_analog_error : 46|2@1+ (1,0) [0|3] ""  HVESP01
 SG_ HVESP01_outlt_clnt_thrm_open : 44|2@1+ (1,0) [0|3] ""  HVESP01
 SG_ HVESP01_neg_3_3_analog_error : 42|2@1+ (1,0) [0|3] ""  HVESP01
 SG_ HVESP01_inlet_clnt_thrm_open : 40|2@1+ (1,0) [0|3] ""  HVESP01
 SG_ HVESP01_hall_eff_lo_rang_err : 54|2@1+ (1,0) [0|3] ""  HVESP01
 SG_ HVESP01_outlt_clnt_thrm_short : 52|2@1+ (1,0) [0|3] ""  HVESP01
 SG_ HVESP01_inlet_clnt_thrm_short : 50|2@1+ (1,0) [0|3] ""  HVESP01
 SG_ HVESP01_3_3v_error : 48|2@1+ (1,0) [0|3] ""  HVESP01

BO_ 2499744612 HVESP01_DiagnosticD: 8 HVESP01
 SG_ HVESP01_Placeholder16 : 10|2@1+ (1,0) [0|3] ""  HVESP01
 SG_ HVESP01_Placeholder15 : 8|2@1+ (1,0) [0|3] ""  HVESP01
 SG_ HVESP01_Placeholder14 : 22|2@1+ (1,0) [0|3] ""  HVESP01
 SG_ HVESP01_Placeholder13 : 20|2@1+ (1,0) [0|3] ""  HVESP01
 SG_ HVESP01_Placeholder02 : 46|2@1+ (1,0) [0|3] ""  HVESP01
 SG_ HVESP01_Placeholder01 : 44|2@1+ (1,0) [0|3] ""  HVESP01
 SG_ HVESP01_Placeholder12 : 18|2@1+ (1,0) [0|3] ""  HVESP01
 SG_ HVESP01_Placeholder11 : 16|2@1+ (1,0) [0|3] ""  HVESP01
 SG_ HVESP01_Placeholder10 : 30|2@1+ (1,0) [0|3] ""  HVESP01
 SG_ HVESP01_Placeholder09 : 28|2@1+ (1,0) [0|3] ""  HVESP01
 SG_ HVESP01_Placeholder08 : 26|2@1+ (1,0) [0|3] ""  HVESP01
 SG_ HVESP01_Placeholder07 : 24|2@1+ (1,0) [0|3] ""  HVESP01
 SG_ HVESP01_Placeholder06 : 38|2@1+ (1,0) [0|3] ""  HVESP01
 SG_ HVESP01_Placeholder05 : 36|2@1+ (1,0) [0|3] ""  HVESP01
 SG_ HVESP01_SpeakerMia : 2|2@1+ (1,0) [0|3] ""  HVESP01
 SG_ HVESP01_Placeholder19 : 0|2@1+ (1,0) [0|3] ""  HVESP01
 SG_ HVESP01_Placeholder18 : 14|2@1+ (1,0) [0|3] ""  HVESP01
 SG_ HVESP01_Placeholder17 : 12|2@1+ (1,0) [0|3] ""  HVESP01
 SG_ HVESP01_Placeholder04 : 34|2@1+ (1,0) [0|3] ""  HVESP01
 SG_ HVESP01_Placeholder03 : 32|2@1+ (1,0) [0|3] ""  HVESP01

BO_ 2499739748 HVESP01_HVIL: 8 HVESP01
 SG_ HVESP01_hvilSinkCrrnt : 24|6@1+ (1,0) [0|50] "mA"  HVESP01
 SG_ HVESP01_hvilSourceVolt : 8|6@1+ (0.1,0) [0|6.3] "Volts"  HVESP01
 SG_ HVESP01_hvilSinkVolt : 16|5@1+ (1,0) [0|29] "Volts"  HVESP01

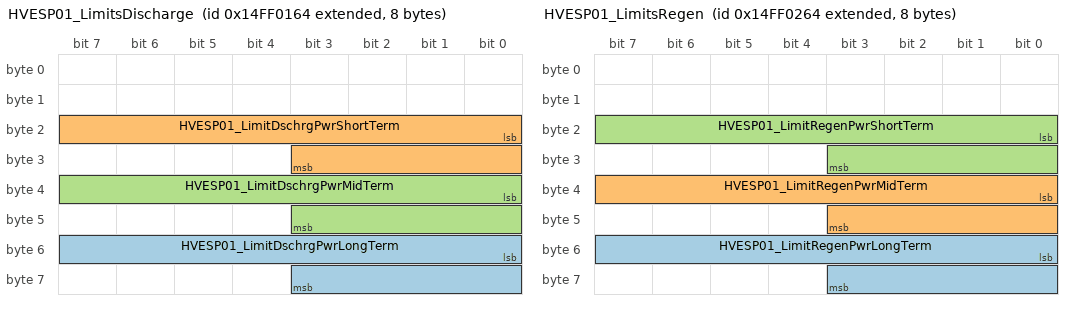
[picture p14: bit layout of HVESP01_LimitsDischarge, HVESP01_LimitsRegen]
BO_ 2499740004 HVESP01_LimitsDischarge: 8 HVESP01
 SG_ HVESP01_LimitDschrgPwrLongTerm : 48|12@1+ (1,0) [0|4095] "kW"  HVESP01
 SG_ HVESP01_LimitDschrgPwrShortTerm : 16|12@1+ (1,0) [0|4095] "kW"  HVESP01
 SG_ HVESP01_LimitDschrgPwrMidTerm : 32|12@1+ (1,0) [0|4095] "kW"  HVESP01

BO_ 2499740260 HVESP01_LimitsRegen: 8 HVESP01
 SG_ HVESP01_LimitRegenPwrLongTerm : 48|12@1+ (1,0) [0|4095] "kW"  HVESP01
 SG_ HVESP01_LimitRegenPwrMidTerm : 32|12@1+ (1,0) [0|4095] "kW"  HVESP01
 SG_ HVESP01_LimitRegenPwrShortTerm : 16|12@1+ (1,0) [0|4095] "kW"  HVESP01

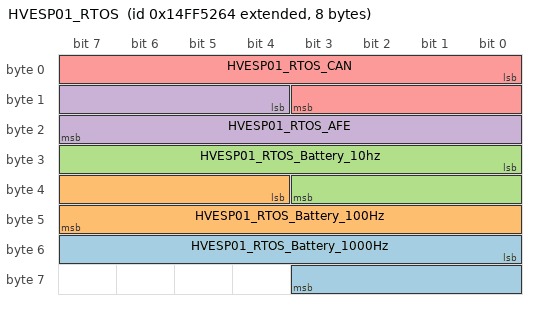
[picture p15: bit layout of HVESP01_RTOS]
BO_ 2499760740 HVESP01_RTOS: 8 HVESP01
 SG_ HVESP01_RTOS_Battery_1000Hz : 48|12@1+ (1,0) [0|4095] ""  HVESP01
 SG_ HVESP01_RTOS_Battery_100Hz : 36|12@1+ (1,0) [0|4095] ""  HVESP01
 SG_ HVESP01_RTOS_Battery_10hz : 24|12@1+ (1,0) [0|4095] ""  HVESP01
 SG_ HVESP01_RTOS_AFE : 12|12@1+ (1,0) [0|4095] ""  HVESP01
 SG_ HVESP01_RTOS_CAN : 0|12@1+ (1,0) [0|4095] ""  HVESP01

CM_ "Application CAN Version: 1908_01";
BA_DEF_ BU_  "GenNodeInstanceStartBit" INT 0 0;
BA_DEF_ BU_  "GenNodeInstanceBitWidth" INT 0 0;
BA_DEF_ BO_  "GenMsgInstanced" STRING ;
BA_DEF_  "NetworkSpeed" ENUM  "250kBit/s","500kBit/s","1000kBit/s";
BA_DEF_ SG_  "SigType" ENUM  "Default","Range","RangeSigned","ASCII","Discrete","Control","ReferencePGN","DTC","StringDelimiter","StringLength","StringLengthControl","MessageCounter","MessageChecksum";
BA_DEF_ SG_  "GenSigEVName" STRING ;
BA_DEF_ SG_  "GenSigILSupport" ENUM  "No","Yes";
BA_DEF_ SG_  "GenSigSendType" ENUM  "Cyclic","OnWrite","OnWriteWithRepetition","OnChange","OnChangeWithRepetition","IfActive","IfActiveWithRepetition","NoSigSendType";
BA_DEF_ BO_  "GenMsgILSupport" ENUM  "No","Yes";
BA_DEF_ BU_  "NmStationAddress" INT 0 255;
BA_DEF_ BO_  "GenMsgSendType" ENUM  "cyclic","NotUsed","IfActive","NotUsed","NotUsed","NotUsed","NotUsed","NotUsed","noMsgSendType";
BA_DEF_ BO_  "GenMsgRequestable" INT 0 1;
BA_DEF_ BO_  "GenMsgCycleTime" INT 0 3600000;
BA_DEF_  "DBName" STRING ;
BA_DEF_  "BusType" STRING ;
BA_DEF_  "ProtocolType" STRING ;
BA_DEF_ BO_  "VFrameFormat" ENUM  "StandardCAN","ExtendedCAN","reserved","J1939PG";
BA_DEF_DEF_  "GenNodeInstanceStartBit" 0;
BA_DEF_DEF_  "GenNodeInstanceBitWidth" 0;
BA_DEF_DEF_  "GenMsgInstanced" "No";
BA_DEF_DEF_  "NetworkSpeed" "250kBit/s";
BA_DEF_DEF_  "SigType" "Default";
BA_DEF_DEF_  "GenSigEVName" "Env@Nodename_@Signame";
BA_DEF_DEF_  "GenSigILSupport" "Yes";
BA_DEF_DEF_  "GenSigSendType" "NoSigSendType";
BA_DEF_DEF_  "GenMsgILSupport" "Yes";
BA_DEF_DEF_  "NmStationAddress" 254;
BA_DEF_DEF_  "GenMsgSendType" "noMsgSendType";
BA_DEF_DEF_  "GenMsgRequestable" 1;
BA_DEF_DEF_  "GenMsgCycleTime" 0;
BA_DEF_DEF_  "DBName" "";
BA_DEF_DEF_  "BusType" "CAN";
BA_DEF_DEF_  "ProtocolType" "J1939";
BA_DEF_DEF_  "VFrameFormat" "J1939PG";
BA_ "ProtocolType" "CAN";
BA_ "DBName" "NF_BMS_Application";
BA_ "GenNodeInstanceBitWidth" BU_ HVESP01 8;
BA_ "GenNodeInstanceBitWidth" BU_ HVESS 8;
BA_ "GenNodeInstanceStartBit" BU_ HVESS 4;
BA_ "GenMsgInstanced" BO_ 2499760228 "Yes";
BA_ "GenMsgCycleTime" BO_ 2499760228 100;
BA_ "VFrameFormat" BO_ 2499760228 1;
BA_ "VFrameFormat" BO_ 2499756132 1;
BA_ "GenMsgCycleTime" BO_ 2499756132 100;
BA_ "GenMsgInstanced" BO_ 2499756132 "Yes";
BA_ "VFrameFormat" BO_ 2499752036 1;
BA_ "GenMsgCycleTime" BO_ 2499752036 100;
BA_ "GenMsgInstanced" BO_ 2499752036 "Yes";
BA_ "GenMsgCycleTime" BO_ 2499760996 1000;
BA_ "GenMsgSendType" BO_ 2499760996 0;
BA_ "GenMsgInstanced" BO_ 2499760996 "Yes";
BA_ "VFrameFormat" BO_ 2499743588 1;
BA_ "GenMsgInstanced" BO_ 2499743588 "Yes";
BA_ "GenMsgInstanced" BO_ 2499743332 "Yes";
BA_ "VFrameFormat" BO_ 2499743076 1;
BA_ "GenMsgInstanced" BO_ 2499743076 "Yes";
BA_ "GenMsgInstanced" BO_ 2499742820 "Yes";
BA_ "GenMsgCycleTime" BO_ 2499742820 100;
BA_ "VFrameFormat" BO_ 2499742820 1;
BA_ "GenMsgInstanced" BO_ 2499747940 "Yes";
BA_ "GenMsgCycleTime" BO_ 2499747940 100;
BA_ "VFrameFormat" BO_ 2499747940 1;
BA_ "GenMsgCycleTime" BO_ 2499742564 100;
BA_ "GenMsgInstanced" BO_ 2499742564 "Yes";
BA_ "GenMsgCycleTime" BO_ 2499742308 100;
BA_ "GenMsgInstanced" BO_ 2499742308 "Yes";
BA_ "GenMsgInstanced" BO_ 2499741796 "Yes";
BA_ "GenMsgInstanced" BO_ 2499742052 "Yes";
BA_ "GenMsgInstanced" BO_ 2499741540 "Yes";
BA_ "GenMsgInstanced" BO_ 2499741284 "Yes";
BA_ "GenMsgInstanced" BO_ 2499741028 "Yes";
BA_ "GenMsgCycleTime" BO_ 2499744868 100;
BA_ "GenMsgInstanced" BO_ 2499744868 "Yes";
BA_ "VFrameFormat" BO_ 2499744868 1;
BA_ "GenMsgCycleTime" BO_ 2499740772 100;
BA_ "GenMsgInstanced" BO_ 2499740772 "Yes";
BA_ "GenMsgSendType" BO_ 2499740772 0;
BA_ "GenMsgCycleTime" BO_ 2499740516 100;
BA_ "GenMsgInstanced" BO_ 2499740516 "Yes";
BA_ "GenMsgSendType" BO_ 2499740516 0;
BA_ "GenMsgCycleTime" BO_ 2499500388 100;
BA_ "GenMsgInstanced" BO_ 2499500388 "Yes";
BA_ "GenMsgSendType" BO_ 2499500388 0;
BA_ "GenMsgSendType" BO_ 2485806436 0;
BA_ "GenMsgSendType" BO_ 2498860900 0;
BA_ "GenMsgInstanced" BO_ 2498860900 "Yes";
BA_ "GenMsgCycleTime" BO_ 2498860900 100;
BA_ "GenMsgSendType" BO_ 2498862436 0;
BA_ "GenMsgInstanced" BO_ 2498862436 "Yes";
BA_ "GenMsgCycleTime" BO_ 2498862436 100;
BA_ "GenMsgSendType" BO_ 2498862180 0;
BA_ "GenMsgInstanced" BO_ 2498862180 "Yes";
BA_ "GenMsgCycleTime" BO_ 2498862180 100;
BA_ "GenMsgSendType" BO_ 2498861924 0;
BA_ "GenMsgInstanced" BO_ 2498861924 "Yes";
BA_ "GenMsgCycleTime" BO_ 2498861924 100;
BA_ "GenMsgSendType" BO_ 2498861156 0;
BA_ "GenMsgInstanced" BO_ 2498861156 "Yes";
BA_ "GenMsgCycleTime" BO_ 2498861156 100;
BA_ "GenMsgSendType" BO_ 2498860388 0;
BA_ "GenMsgInstanced" BO_ 2498860388 "Yes";
BA_ "GenMsgCycleTime" BO_ 2498860388 20;
BA_ "GenMsgSendType" BO_ 2498859876 0;
BA_ "GenMsgInstanced" BO_ 2498859876 "Yes";
BA_ "GenMsgCycleTime" BO_ 2498859876 20;
BA_ "GenMsgSendType" BO_ 2498859620 0;
BA_ "GenMsgInstanced" BO_ 2498859620 "Yes";
BA_ "GenMsgCycleTime" BO_ 2498859620 20;
BA_ "GenMsgSendType" BO_ 2498859364 0;
BA_ "GenMsgInstanced" BO_ 2498859364 "Yes";
BA_ "GenMsgCycleTime" BO_ 2498859364 20;
BA_ "GenMsgInstanced" BO_ 2499743844 "Yes";
BA_ "GenMsgCycleTime" BO_ 2499743844 200;
BA_ "GenMsgSendType" BO_ 2499743844 0;
BA_ "GenMsgInstanced" BO_ 2499744100 "Yes";
BA_ "GenMsgCycleTime" BO_ 2499744100 200;
BA_ "GenMsgSendType" BO_ 2499744100 0;
BA_ "GenMsgInstanced" BO_ 2499744356 "Yes";
BA_ "GenMsgCycleTime" BO_ 2499744356 200;
BA_ "GenMsgSendType" BO_ 2499744356 0;
BA_ "GenMsgInstanced" BO_ 2499744612 "Yes";
BA_ "GenMsgSendType" BO_ 2499744612 0;
BA_ "GenMsgCycleTime" BO_ 2499744612 200;
BA_ "GenMsgInstanced" BO_ 2499739748 "Yes";
BA_ "GenMsgCycleTime" BO_ 2499739748 100;
BA_ "GenMsgSendType" BO_ 2499739748 0;
BA_ "GenMsgInstanced" BO_ 2499740004 "Yes";
BA_ "GenMsgCycleTime" BO_ 2499740004 1000;
BA_ "GenMsgSendType" BO_ 2499740004 0;
BA_ "GenMsgInstanced" BO_ 2499740260 "Yes";
BA_ "GenMsgCycleTime" BO_ 2499740260 1000;
BA_ "GenMsgSendType" BO_ 2499740260 0;
BA_ "GenMsgInstanced" BO_ 2499760740 "Yes";
BA_ "GenMsgCycleTime" BO_ 2499760740 1000;
BA_ "GenMsgSendType" BO_ 2499760740 0;
VAL_ 2499760228 HVESP01_seriesP2_PreCg_StatusReq 3 "DontCare" 2 "EmergencyContactorClose" 1 "CloseContactor" 0 "OpenContactor" ;
VAL_ 2499760228 HVESP01_seriesP2_PosCt_StatusReq 3 "DontCare" 2 "EmergencyContactorClose" 1 "CloseContactor" 0 "OpenContactor" ;
VAL_ 2499760228 HVESP01_seriesP2_negCt_StatusReq 3 "DontCare" 2 "EmergencyContactorClose" 1 "CloseContactor" 0 "OpenContactor" ;
VAL_ 2499760228 HVESP01_seriesP1_PreCg_StatusReq 3 "DontCare" 2 "EmergencyContactorClose" 1 "CloseContactor" 0 "OpenContactor" ;
VAL_ 2499760228 HVESP01_seriesP1_PosCt_StatusReq 3 "DontCare" 2 "EmergencyContactorClose" 1 "CloseContactor" 0 "OpenContactor" ;
VAL_ 2499760228 HVESP01_seriesP1_negCt_StatusReq 3 "DontCare" 2 "EmergencyContactorClose" 1 "CloseContactor" 0 "OpenContactor" ;
VAL_ 2499760996 HVESP01_packBoardDetails_board 3 "Unknown" 2 "Core" 1 "JuiceBox" 0 "BaldEagle" ;
VAL_ 2499743332 HVESP01_PackBalance 3 "SNA" 2 "BalancingComplete" 1 "Balancing" 0 "NotBalancing" ;
VAL_ 2499742820 HVESP01_packstate 7 "Disengage" 6 "Connected" 5 "ExternalIsolationCheck" 4 "PrepareBusJoin" 3 "PrepareBusPrecharge" 2 "StandbyReady" 1 "StandbyNotReady" 0 "StandbyInit" ;
VAL_ 2499742820 HVESP01_negPackConStatusReq 3 "DontCare" 2 "EmergencyContactorClose" 1 "CloseContactor" 0 "OpenContactor" ;
VAL_ 2499742820 HVESP01_posPackConStatusReq 3 "DontCare" 2 "EmergencyContactorClose" 1 "CloseContactor" 0 "OpenContactor" ;
VAL_ 2499742820 HVESP01_prechargeConStatusReq 3 "DontCare" 2 "EmergencyContactorClose" 1 "CloseContactor" 0 "OpenContactor" ;
VAL_ 2499742820 HVESP01_negPackConStatus 15 "NA" 14 "Error" 13 "Reserved" 12 "Reserved" 11 "Reserved" 10 "Reserved" 9 "Reserved" 8 "Reserved" 7 "Reserved" 6 "Reserved" 5 "Reserved" 4 "DisconnectedPreChgFail" 3 "DisconnectionInProcess" 2 "ConnectionInProcess" 1 "Connected" 0 "Disconnected" ;
VAL_ 2499742820 HVESP01_posPackConStatus 15 "NA" 14 "Error" 13 "Reserved" 12 "Reserved" 11 "Reserved" 10 "Reserved" 9 "Reserved" 8 "Reserved" 7 "Reserved" 6 "Reserved" 5 "Reserved" 4 "DisconnectedPreChgFail" 3 "DisconnectionInProcess" 2 "ConnectionInProcess" 1 "Connected" 0 "Disconnected" ;
VAL_ 2499742820 HVESP01_prechargeConStatus 15 "NA" 14 "Error" 13 "Reserved" 12 "Reserved" 11 "Reserved" 10 "Reserved" 9 "Reserved" 8 "Reserved" 7 "Reserved" 6 "Reserved" 5 "Reserved" 4 "DisconnectedPreChgFail" 3 "DisconnectionInProcess" 2 "ConnectionInProcess" 1 "Connected" 0 "Disconnected" ;
VAL_ 2485806436 HVESP01_thermMngmntMaintReq 3 "DontCare" 2 "Reserved" 1 "ThermMngmntMaintModeNotReq" 0 "ThermMngmntMaintReq" ;
VAL_ 2485806436 HVESP01_hvBusLsResistor 3 "DontCare" 2 "Reserved" 1 "ConnectionRequested" 0 "ConnectionNotRequested" ;
VAL_ 2485806436 HVESP01_hvBusHsResistor 3 "DontCare" 2 "Reserved" 1 "ConnectionRequested" 0 "ConnectionNotRequested" ;
VAL_ 2485806436 HVESP01_operationConsent 3 "DontCare" 2 "Reserved" 1 "ConsentGiven" 0 "ConsentRevoked" ;
VAL_ 2485806436 HVESP01_enableIntChargerCmd 3 "DontCare" 2 "Error" 1 "EnableCharging" 0 "DisableCharging" ;
VAL_ 2485806436 HVESP01_cellBalancingCmd 3 "DontCare" 2 "Reserved" 1 "CellBalancingRequested" 0 "CellBalancingNotRequested" ;
VAL_ 2485806436 HVESP01_hvBusPassveIsoTest 3 "DontCare" 2 "Reserved" 1 "PassiveIsolationTestRequested" 0 "PassiveIsolationTestNotRequested" ;
VAL_ 2485806436 HVESP01_hvBusActiveIsoTest 3 "DontCare" 2 "Reserved" 1 "ActiveIsoTestRequested" 0 "ActiveIsoTestNotRequested" ;
VAL_ 2485806436 HVESP01_powerDownCmd 3 "DontCare" 2 "EmergencyPowerDown" 1 "NormalPowerDown" 0 "PowerDownNotRequested" ;
VAL_ 2485806436 HVESP01_hvBusConnectCmd 3 "DontCare" 2 "EmergencyContactorClose" 1 "CloseContactor" 0 "OpenContactor" ;
VAL_ 2498860900 HVESP01_operationalStatus 15 "NA" 14 "Error" 13 "Reserved" 12 "Reserved" 11 "Reserved" 10 "Reserved" 9 "Reserved" 8 "Reserved" 7 "Reserved" 6 "DisabledInt" 5 "DisabledExtCmd" 4 "EmergencyPowerDown" 3 "NormalPowerDown" 2 "Operational" 1 "InitComplete" 0 "InitInProcess" ;
VAL_ 2498860900 HVESP01_hvBusConnectionStatus 15 "NA" 14 "Error" 13 "Reserved" 12 "Reserved" 11 "Reserved" 10 "Reserved" 9 "Reserved" 8 "Reserved" 7 "Reserved" 6 "Reserved" 5 "Reserved" 4 "DisconnectedPreChgFail" 3 "DisconnectionInProcess" 2 "ConnectionInProcess" 1 "Connected" 0 "Disconnected" ;
VAL_ 2498860900 HVESP01_cellBalancingActive 3 "NA" 2 "Error" 1 "CellBalancingActive" 0 "CellBalancingNotActive" ;
VAL_ 2498860900 HVESP01_internalChargeStatus 3 "NA" 2 "Error" 1 "ChargingOn" 0 "ChargingOff" ;
VAL_ 2498860900 HVESP01_cellBalanceStatus 3 "NA" 2 "Error" 1 "CellsUnbalanced" 0 "CellsBalanced" ;
VAL_ 2498860900 HVESP01_socStatus 15 "NA" 14 "Error" 13 "Reserved" 12 "Reserved" 11 "Reserved" 10 "Reserved" 9 "Reserved" 8 "Reserved" 7 "Reserved" 6 "SocAboveUpperLimit" 5 "SocRecommendedUpperLimit" 4 "SocApproachingUpperLimit" 3 "SocBelowLowerLimit" 2 "SocRecommendedLowerLimit" 1 "SocApproachingLowerLimit" 0 "SocLevelAcceptableLimit" ;
VAL_ 2498860900 HVESP01_inertiaSwitchStatus 3 "NA" 2 "Error" 1 "ImpactSensed" 0 "NoImpactSensed" ;
VAL_ 2498860900 HVESP01_hvilStatus 3 "NA" 2 "Error" 1 "HvilOpen" 0 "HvilClosed" ;
VAL_ 2498860900 HVESP01_hvBusPassveIsoTestStatus 15 "NA" 14 "Error" 13 "Reserved" 12 "Reserved" 11 "Reserved" 10 "Reserved" 9 "Reserved" 8 "Reserved" 7 "Reserved" 6 "Reserved" 5 "TestCompleteFault" 4 "TestCompleteMarginal" 3 "TestCompleteAcceptable" 2 "TestInProcess" 1 "TestRequestedNotInProgress" 0 "NoTestRequested" ;
VAL_ 2498860900 HVESP01_hvBusActiveIsoTestStatus 15 "NA" 14 "Error" 13 "Reserved" 12 "Reserved" 11 "Reserved" 10 "Reserved" 9 "Reserved" 8 "Reserved" 7 "Reserved" 6 "Reserved" 5 "TestCompleteFault" 4 "TestCompleteMarginal" 3 "TestCompleteAcceptable" 2 "TestInProcess" 1 "TestRequestedNotInProgress" 0 "NoTestRequested" ;
VAL_ 2498860900 HVESP01_centerOfPackContState 3 "NA" 2 "Error" 1 "ContactorClosed" 0 "ContactorOpen" ;
VAL_ 2498860900 HVESP01_hvBusPrechgRelayState 3 "NA" 2 "Error" 1 "RelayOpen" 0 "RelayClosed" ;
VAL_ 2498860900 HVESP01_hvBusDisconnect 15 "NA" 14 "Error" 13 "DisconnectImminent" 12 "Reserved" 11 "Reserved" 10 "Reserved" 9 "Reserved" 8 "Reserved" 7 "DisconnectImminentPckCurrMax" 6 "DisconnectImminentCellVoltMax" 5 "DisconnectImminentCellVoltMin" 4 "DisconnectImminentModVoltMax" 3 "DisconnectImminentModVoltMin" 2 "DisconnectImminentBattPckVoltMax" 1 "DisconnectImminentBattPackVoltMin" 0 "DisconnectNotPending" ;
VAL_ 2498860900 HVESP01_hvBusNegContState 3 "NA" 2 "Error" 1 "ContactorClosed" 0 "ContactorOpen" ;
VAL_ 2498860900 HVESP01_hvBusPosContState 3 "NA" 2 "Error" 1 "ContactorClosed" 0 "ContactorOpen" ;
